VERSION "dbc-export 1 2026.26.6.5"

NS_ :

BS_:

BU_: ADSP APB APP APS APSB BB BMS CC CMP CMPD CP DAS DI DIF DIR DPB EPAS3P EPAS3S EPASTP EPASTS EPBL EPBR ESP EVSE FC GTW HCML HCMR HVP IBST ICR IDB LS OCS1P ODIN PARK PCS PCS2 PLG PM PMF PMR PNCD PTC RADC RCM RCM2 RCM3 RCU SCCM SCM SCS SDCR TAS TCU TCU2 TPMS TRCM UDS UI UIS UMC USM V2G VC VCBATT VCBATT0 VCBATT1 VCBATT2 VCCC VCFRONT VCFRONT1 VCFRONT2 VCLEFT VCRIGHT VCSEAT2L VCSEAT2R VCSEC VEH

BO_ 1300 FC_serial: 8 FC
 SG_ FC_serialDataSelect M : 0|7@1+ (1,0) [0|127] "" Vector__XXX
 SG_ FC_serialChar01 m0 : 8|8@1+ (1,0) [0|255] "" Vector__XXX
 SG_ FC_serialChar02 m0 : 16|8@1+ (1,0) [0|255] "" Vector__XXX
 SG_ FC_serialChar03 m0 : 24|8@1+ (1,0) [0|255] "" Vector__XXX
 SG_ FC_serialChar04 m0 : 32|8@1+ (1,0) [0|255] "" Vector__XXX
 SG_ FC_serialChar05 m0 : 40|8@1+ (1,0) [0|255] "" Vector__XXX
 SG_ FC_serialChar06 m0 : 48|8@1+ (1,0) [0|255] "" Vector__XXX
 SG_ FC_serialChar07 m0 : 56|8@1+ (1,0) [0|255] "" Vector__XXX
 SG_ FC_serialChar08 m1 : 8|8@1+ (1,0) [0|255] "" Vector__XXX
 SG_ FC_serialChar09 m1 : 16|8@1+ (1,0) [0|255] "" Vector__XXX
 SG_ FC_serialChar10 m1 : 24|8@1+ (1,0) [0|255] "" Vector__XXX
 SG_ FC_serialChar11 m1 : 32|8@1+ (1,0) [0|255] "" Vector__XXX
 SG_ FC_serialChar12 m1 : 40|8@1+ (1,0) [0|255] "" Vector__XXX
 SG_ FC_serialChar13 m1 : 48|8@1+ (1,0) [0|255] "" Vector__XXX
 SG_ FC_serialChar14 m1 : 56|8@1+ (1,0) [0|255] "" Vector__XXX
 SG_ FC_serialChar15 m2 : 8|8@1+ (1,0) [0|255] "" Vector__XXX
 SG_ FC_serialChar16 m2 : 16|8@1+ (1,0) [0|255] "" Vector__XXX
 SG_ FC_serialChar17 m2 : 24|8@1+ (1,0) [0|255] "" Vector__XXX

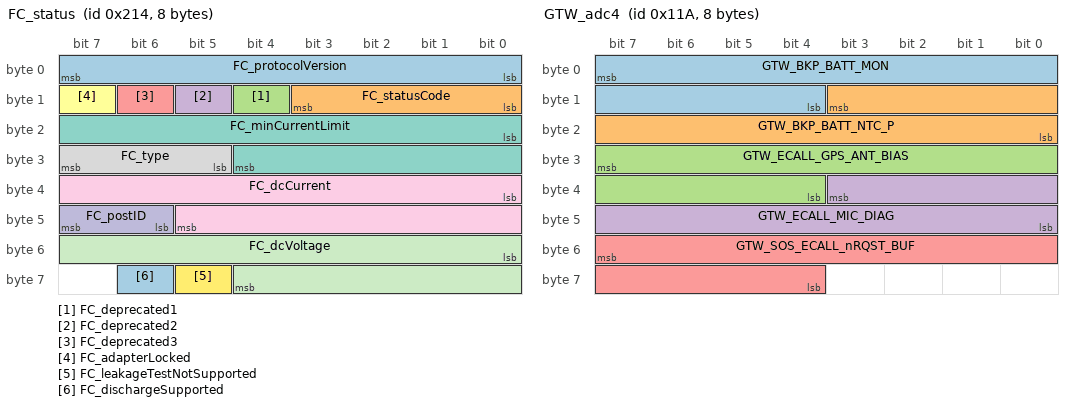
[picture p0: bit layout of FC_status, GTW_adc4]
BO_ 532 FC_status: 8 FC
 SG_ FC_protocolVersion : 0|8@1+ (1,0) [0|255] "" Vector__XXX
 SG_ FC_statusCode : 8|4@1+ (1,0) [1|15] "" Vector__XXX
 SG_ FC_deprecated1 : 12|1@1+ (1,0) [0|1] "" Vector__XXX
 SG_ FC_deprecated2 : 13|1@1+ (1,0) [0|1] "" Vector__XXX
 SG_ FC_deprecated3 : 14|1@1+ (1,0) [0|1] "" Vector__XXX
 SG_ FC_adapterLocked : 15|1@1+ (1,0) [0|1] "" Vector__XXX
 SG_ FC_minCurrentLimit : 16|13@1+ (0.1,0) [0|600] "A" Vector__XXX
 SG_ FC_type : 29|3@1+ (1,0) [0|6] "" Vector__XXX
 SG_ FC_dcCurrent : 32|14@1- (0.07324219,0) [-600|599.92675781] "A" Vector__XXX
 SG_ FC_postID : 46|2@1+ (1,0) [0|2] "" Vector__XXX
 SG_ FC_dcVoltage : 48|13@1+ (0.07324219,0) [0|599.92675822] "V" Vector__XXX
 SG_ FC_leakageTestNotSupported : 61|1@1+ (1,0) [0|1] "" Vector__XXX
 SG_ FC_dischargeSupported : 62|1@1+ (1,0) [0|1] "" Vector__XXX

BO_ 533 FC_status2: 1 FC
 SG_ FC_externalIsolationResistance : 0|8@1+ (40,0) [0|10160] "kOhm" Vector__XXX

BO_ 535 FC_status3: 8 FC
 SG_ FC_status3DataSelect M : 0|7@1+ (1,0) [0|127] "" Vector__XXX
 SG_ FC_status3DummySig : 7|1@1+ (1,0) [0|1] "" Vector__XXX
 SG_ FC_class m0 : 8|8@1+ (1,0) [1|255] "" Vector__XXX
 SG_ FC_brand m0 : 16|4@1+ (1,0) [1|15] "" Vector__XXX
 SG_ FC_coolingType m0 : 20|4@1+ (1,0) [1|15] "" Vector__XXX
 SG_ FC_uiStopType m0 : 24|4@1+ (1,0) [1|15] "" Vector__XXX
 SG_ FC_emergencyShutdownSupported m0 : 28|1@1+ (1,0) [0|1] "" Vector__XXX
 SG_ FC_generation m0 : 32|8@1+ (1,0) [1|255] "" Vector__XXX
 SG_ FC_billingEnergy m1 : 8|16@1+ (0.015259,0) [0|999.998565] "kWh" Vector__XXX

BO_ 888 GTW_ECall: 1 GTW
 SG_ GTW_GTW_SOS_ECALL_RQST : 0|1@1+ (1,0) [0|1] "" Vector__XXX
 SG_ GTW_LTE_ECALL_LOCK : 1|1@1+ (1,0) [0|1] "" Vector__XXX

BO_ 282 GTW_adc4: 8 GTW
 SG_ GTW_BKP_BATT_MON : 7|12@0+ (1,0) [0|4094] "mV" Vector__XXX
 SG_ GTW_BKP_BATT_NTC_P : 11|12@0+ (1,0) [0|4094] "mV" Vector__XXX
 SG_ GTW_ECALL_GPS_ANT_BIAS : 31|12@0+ (1,0) [0|4094] "mV" Vector__XXX
 SG_ GTW_ECALL_MIC_DIAG : 35|12@0+ (1,0) [0|4094] "mV" Vector__XXX
 SG_ GTW_SOS_ECALL_nRQST_BUF : 55|12@0+ (1,0) [0|4094] "mV" Vector__XXX

BO_ 1384 GTW_alertLog: 8 GTW
 SG_ GTW_alertID M : 0|9@1+ (1,0) [0|511] "" Vector__XXX
 SG_ GTW_alertState : 15|1@1+ (1,0) [0|1] "" Vector__XXX
 SG_ GTW_a014_crcVersion m14 : 16|32@1+ (1,0) [0|4294967295] "" Vector__XXX
 SG_ GTW_a015_crcVersion m15 : 16|32@1+ (1,0) [0|4294967295] "" Vector__XXX
 SG_ GTW_a016_crcVersion m16 : 16|32@1+ (1,0) [0|4294967295] "" Vector__XXX
 SG_ GTW_a017_crcVersion m17 : 16|32@1+ (1,0) [0|4294967295] "" Vector__XXX
 SG_ GTW_a018_crcVersion m18 : 16|32@1+ (1,0) [0|4294967295] "" Vector__XXX
 SG_ GTW_a019_crcVersion m19 : 16|32@1+ (1,0) [0|4294967295] "" Vector__XXX
 SG_ GTW_a020_crcVersion m20 : 16|32@1+ (1,0) [0|4294967295] "" Vector__XXX
 SG_ GTW_a021_crcVersion m21 : 16|32@1+ (1,0) [0|4294967295] "" Vector__XXX
 SG_ GTW_a022_crcVersion m22 : 16|32@1+ (1,0) [0|4294967295] "" Vector__XXX
 SG_ GTW_a023_crcVersion m23 : 16|32@1+ (1,0) [0|4294967295] "" Vector__XXX
 SG_ GTW_a024_crcVersion m24 : 16|32@1+ (1,0) [0|4294967295] "" Vector__XXX
 SG_ GTW_a025_crcVersion m25 : 16|32@1+ (1,0) [0|4294967295] "" Vector__XXX
 SG_ GTW_a026_crcVersion m26 : 16|32@1+ (1,0) [0|4294967295] "" Vector__XXX
 SG_ GTW_a027_crcVersion m27 : 16|32@1+ (1,0) [0|4294967295] "" Vector__XXX
 SG_ GTW_a028_crcVersion m28 : 16|32@1+ (1,0) [0|4294967295] "" Vector__XXX
 SG_ GTW_a029_crcVersion m29 : 16|32@1+ (1,0) [0|4294967295] "" Vector__XXX
 SG_ GTW_a030_crcVersion m30 : 16|32@1+ (1,0) [0|4294967295] "" Vector__XXX
 SG_ GTW_a031_crcVersion m31 : 16|32@1+ (1,0) [0|4294967295] "" Vector__XXX
 SG_ GTW_a032_crcVersion m32 : 16|32@1+ (1,0) [0|4294967295] "" Vector__XXX
 SG_ GTW_a033_crcVersion m33 : 16|32@1+ (1,0) [0|4294967295] "" Vector__XXX
 SG_ GTW_a034_crcVersion m34 : 16|32@1+ (1,0) [0|4294967295] "" Vector__XXX
 SG_ GTW_a035_crcVersion m35 : 16|32@1+ (1,0) [0|4294967295] "" Vector__XXX
 SG_ GTW_a036_crcVersion m36 : 16|32@1+ (1,0) [0|4294967295] "" Vector__XXX
 SG_ GTW_a037_crcVersion m37 : 16|32@1+ (1,0) [0|4294967295] "" Vector__XXX
 SG_ GTW_a038_crcVersion m38 : 16|32@1+ (1,0) [0|4294967295] "" Vector__XXX
 SG_ GTW_a039_crcVersion m39 : 16|32@1+ (1,0) [0|4294967295] "" Vector__XXX
 SG_ GTW_a040_crcVersion m40 : 16|32@1+ (1,0) [0|4294967295] "" Vector__XXX
 SG_ GTW_a041_crcVersion m41 : 16|32@1+ (1,0) [0|4294967295] "" Vector__XXX
 SG_ GTW_a042_crcVersion m42 : 16|32@1+ (1,0) [0|4294967295] "" Vector__XXX
 SG_ GTW_a043_crcVersion m43 : 16|32@1+ (1,0) [0|4294967295] "" Vector__XXX
 SG_ GTW_a045_crcVersion m45 : 16|32@1+ (1,0) [0|4294967295] "" Vector__XXX
 SG_ GTW_a046_crcVersion m46 : 16|32@1+ (1,0) [0|4294967295] "" Vector__XXX
 SG_ GTW_a047_crcVersion m47 : 16|32@1+ (1,0) [0|4294967295] "" Vector__XXX
 SG_ GTW_a048_crcVersion m48 : 16|32@1+ (1,0) [0|4294967295] "" Vector__XXX
 SG_ GTW_a049_headerError m49 : 16|2@1+ (1,0) [0|3] "" Vector__XXX
 SG_ GTW_a054_crcVersion m54 : 16|32@1+ (1,0) [0|4294967295] "" Vector__XXX
 SG_ GTW_a055_crcVersion m55 : 16|32@1+ (1,0) [0|4294967295] "" Vector__XXX
 SG_ GTW_a062_bmpWatchdogReason m62 : 16|3@1+ (1,0) [0|7] "" Vector__XXX
 SG_ GTW_a063_VEH_faultConfinement m63 : 16|2@1+ (1,0) [0|3] "" Vector__XXX
 SG_ GTW_a064_CH_faultConfinement m64 : 16|2@1+ (1,0) [0|3] "" Vector__XXX
 SG_ GTW_a065_PARTY_faultConfinement m65 : 16|2@1+ (1,0) [0|3] "" Vector__XXX
 SG_ GTW_a066_type m66 : 16|5@1+ (1,0) [0|31] "" Vector__XXX
 SG_ GTW_a066_exceptionCfgId m66 : 21|8@1+ (1,0) [0|255] "" Vector__XXX
 SG_ GTW_a066_uptime m66 : 29|32@1+ (1,0) [0|4294967295] "" Vector__XXX
 SG_ GTW_a066_core m66 : 61|3@1+ (1,0) [0|7] "" Vector__XXX
 SG_ GTW_a068_codeKeyMissing m68 : 16|1@1+ (1,0) [0|1] "" Vector__XXX
 SG_ GTW_a068_cmdKeyMissing m68 : 17|1@1+ (1,0) [0|1] "" Vector__XXX
 SG_ GTW_a069_sdIntStatusErrs m69 : 16|1@1+ (1,0) [0|1] "" Vector__XXX
 SG_ GTW_a069_sdTimeout m69 : 17|1@1+ (1,0) [0|1] "" Vector__XXX
 SG_ GTW_a069_sdCmdErr m69 : 18|1@1+ (1,0) [0|1] "" Vector__XXX
 SG_ GTW_a069_sdWriteErr m69 : 19|1@1+ (1,0) [0|1] "" Vector__XXX
 SG_ GTW_a069_sdReadErr m69 : 20|1@1+ (1,0) [0|1] "" Vector__XXX
 SG_ GTW_a069_autoCmd12Err m69 : 21|1@1+ (1,0) [0|1] "" Vector__XXX
 SG_ GTW_a072_updtFailureMask m72 : 16|32@1+ (1,0) [0|4294967295] "" Vector__XXX
 SG_ GTW_a073_SOCResetRequestor m73 : 16|3@1+ (1,0) [0|7] "" Vector__XXX
 SG_ GTW_a077_bmpPmicErrorType m77 : 16|3@1+ (1,0) [0|7] "" Vector__XXX
 SG_ GTW_a097_crcVersion m97 : 16|32@1+ (1,0) [0|4294967295] "" Vector__XXX
 SG_ GTW_a098_crcVersion m98 : 16|32@1+ (1,0) [0|4294967295] "" Vector__XXX
 SG_ GTW_a099_crcVersion m99 : 16|32@1+ (1,0) [0|4294967295] "" Vector__XXX
 SG_ GTW_a100_crcVersion m100 : 16|32@1+ (1,0) [0|4294967295] "" Vector__XXX
 SG_ GTW_a101_switchStuck m101 : 16|1@1+ (1,0) [0|1] "" Vector__XXX
 SG_ GTW_a101_ETH_SW_nINT m101 : 17|1@1+ (1,0) [0|1] "" Vector__XXX
 SG_ GTW_a106_crcVersion m106 : 16|32@1+ (1,0) [0|4294967295] "" Vector__XXX
 SG_ GTW_a107_crcVersion m107 : 16|32@1+ (1,0) [0|4294967295] "" Vector__XXX
 SG_ GTW_a108_crcVersion m108 : 16|32@1+ (1,0) [0|4294967295] "" Vector__XXX
 SG_ GTW_a117_MC_RGM_DES m117 : 16|32@1+ (1,0) [0|4294967295] "" Vector__XXX
 SG_ GTW_a118_MC_RGM_FES m118 : 16|32@1+ (1,0) [0|4294967295] "" Vector__XXX
 SG_ GTW_a122_BDY_faultConfinement m122 : 16|2@1+ (1,0) [0|3] "" Vector__XXX
 SG_ GTW_a129_crcVersion m129 : 16|32@1+ (1,0) [0|4294967295] "" Vector__XXX
 SG_ GTW_a138_sdLifetimeUsed m138 : 16|8@1+ (1,0) [0|255] "" Vector__XXX
 SG_ GTW_a139_crcVersion m139 : 16|32@1+ (1,0) [0|4294967295] "" Vector__XXX
 SG_ GTW_a150_crcVersion m150 : 16|32@1+ (1,0) [0|4294967295] "" Vector__XXX
 SG_ GTW_a151_crcVersion m151 : 16|32@1+ (1,0) [0|4294967295] "" Vector__XXX
 SG_ GTW_a155_crcVersion m155 : 16|32@1+ (1,0) [0|4294967295] "" Vector__XXX
 SG_ GTW_a164_crcVersion m164 : 16|32@1+ (1,0) [0|4294967295] "" Vector__XXX
 SG_ GTW_a165_crcVersion m165 : 16|32@1+ (1,0) [0|4294967295] "" Vector__XXX
 SG_ GTW_a169_TPMS_pressureFL m169 : 16|8@1+ (1,0) [0|255] "" Vector__XXX
 SG_ GTW_a170_TPMS_pressureFR m170 : 16|8@1+ (1,0) [0|255] "" Vector__XXX
 SG_ GTW_a171_TPMS_pressureRL m171 : 16|8@1+ (1,0) [0|255] "" Vector__XXX
 SG_ GTW_a172_TPMS_pressureRR m172 : 16|8@1+ (1,0) [0|255] "" Vector__XXX
 SG_ GTW_a173_TPMS_pressureFL m173 : 16|8@1+ (1,0) [0|255] "" Vector__XXX
 SG_ GTW_a174_TPMS_pressureFR m174 : 16|8@1+ (1,0) [0|255] "" Vector__XXX
 SG_ GTW_a175_TPMS_pressureRL m175 : 16|8@1+ (1,0) [0|255] "" Vector__XXX
 SG_ GTW_a176_TPMS_pressureRR m176 : 16|8@1+ (1,0) [0|255] "" Vector__XXX
 SG_ GTW_a219_crcVersion m219 : 16|32@1+ (1,0) [0|4294967295] "" Vector__XXX
 SG_ GTW_a223_crcVersion m223 : 16|32@1+ (1,0) [0|4294967295] "" Vector__XXX
 SG_ GTW_a226_crcVersion m226 : 16|32@1+ (1,0) [0|4294967295] "" Vector__XXX
 SG_ GTW_a227_crcVersion m227 : 16|32@1+ (1,0) [0|4294967295] "" Vector__XXX
 SG_ GTW_a228_crcVersion m228 : 16|32@1+ (1,0) [0|4294967295] "" Vector__XXX
 SG_ GTW_a244_crcVersion m244 : 16|32@1+ (1,0) [0|4294967295] "" Vector__XXX
 SG_ GTW_a245_page0ControlValue m245 : 16|16@1+ (1,0) [0|65535] "" Vector__XXX
 SG_ GTW_a245_page1ControlValue m245 : 32|16@1+ (1,0) [0|65535] "" Vector__XXX
 SG_ GTW_a261_failureReason m261 : 16|3@1+ (1,0) [0|7] "" Vector__XXX
 SG_ GTW_a261_failureData1 m261 : 24|16@1+ (1,0) [0|65535] "" Vector__XXX
 SG_ GTW_a261_failureData2 m261 : 40|16@1+ (1,0) [0|65535] "" Vector__XXX
 SG_ GTW_a273_crcVersion m273 : 16|32@1+ (1,0) [0|4294967295] "" Vector__XXX
 SG_ GTW_a274_crcVersion m274 : 16|32@1+ (1,0) [0|4294967295] "" Vector__XXX
 SG_ GTW_a277_mitigationFailureReason m277 : 16|3@1+ (1,0) [0|7] "" Vector__XXX
 SG_ GTW_a279_repeatCount m279 : 16|8@1+ (1,0) [0|255] "" Vector__XXX
 SG_ GTW_a279_failureReason m279 : 24|3@1+ (1,0) [0|7] "" Vector__XXX
 SG_ GTW_a279_failureData1 m279 : 32|16@1+ (1,0) [0|65535] "" Vector__XXX
 SG_ GTW_a279_failureData2 m279 : 48|16@1+ (1,0) [0|65535] "" Vector__XXX
 SG_ GTW_a309_crcVersion m309 : 16|32@1+ (1,0) [0|4294967295] "" Vector__XXX
 SG_ GTW_a317_status m317 : 16|3@1+ (1,0) [0|7] "" Vector__XXX
 SG_ GTW_a317_errorCode m317 : 19|5@1+ (1,0) [0|31] "" Vector__XXX
 SG_ GTW_a329_crcVersion m329 : 16|32@1+ (1,0) [0|4294967295] "" Vector__XXX
 SG_ GTW_a330_crcVersion m330 : 16|32@1+ (1,0) [0|4294967295] "" Vector__XXX
 SG_ GTW_a331_crcVersion m331 : 16|32@1+ (1,0) [0|4294967295] "" Vector__XXX
 SG_ GTW_a342_crcVersion m342 : 16|32@1+ (1,0) [0|4294967295] "" Vector__XXX
 SG_ GTW_a348_crcVersion m348 : 16|32@1+ (1,0) [0|4294967295] "" Vector__XXX
 SG_ GTW_a349_crcVersion m349 : 16|32@1+ (1,0) [0|4294967295] "" Vector__XXX
 SG_ GTW_a354_crcVersion m354 : 16|32@1+ (1,0) [0|4294967295] "" Vector__XXX
 SG_ GTW_a355_crcVersion m355 : 16|32@1+ (1,0) [0|4294967295] "" Vector__XXX
 SG_ GTW_a358_crcVersion m358 : 16|32@1+ (1,0) [0|4294967295] "" Vector__XXX
 SG_ GTW_a359_crcVersion m359 : 16|32@1+ (1,0) [0|4294967295] "" Vector__XXX
 SG_ GTW_a360_crcVersion m360 : 16|32@1+ (1,0) [0|4294967295] "" Vector__XXX
 SG_ GTW_a361_crcVersion m361 : 16|32@1+ (1,0) [0|4294967295] "" Vector__XXX
 SG_ GTW_a362_crcVersion m362 : 16|32@1+ (1,0) [0|4294967295] "" Vector__XXX
 SG_ GTW_a363_crcVersion m363 : 16|32@1+ (1,0) [0|4294967295] "" Vector__XXX
 SG_ GTW_a364_crcVersion m364 : 16|32@1+ (1,0) [0|4294967295] "" Vector__XXX
 SG_ GTW_a380_crcVersion m380 : 16|32@1+ (1,0) [0|4294967295] "" Vector__XXX
 SG_ GTW_a381_crcVersion m381 : 16|32@1+ (1,0) [0|4294967295] "" Vector__XXX
 SG_ GTW_a382_crcVersion m382 : 16|32@1+ (1,0) [0|4294967295] "" Vector__XXX
 SG_ GTW_a383_crcVersion m383 : 16|32@1+ (1,0) [0|4294967295] "" Vector__XXX
 SG_ GTW_a384_crcVersion m384 : 16|32@1+ (1,0) [0|4294967295] "" Vector__XXX
 SG_ GTW_a385_crcVersion m385 : 16|32@1+ (1,0) [0|4294967295] "" Vector__XXX
 SG_ GTW_a386_crcVersion m386 : 16|32@1+ (1,0) [0|4294967295] "" Vector__XXX
 SG_ GTW_a394_crcVersion m394 : 16|32@1+ (1,0) [0|4294967295] "" Vector__XXX
 SG_ GTW_a401_crcVersion m401 : 16|32@1+ (1,0) [0|4294967295] "" Vector__XXX
 SG_ GTW_a402_crcVersion m402 : 16|32@1+ (1,0) [0|4294967295] "" Vector__XXX
 SG_ GTW_a409_RES_CAUSE m409 : 16|32@1+ (1,0) [0|4294967295] "" Vector__XXX
 SG_ GTW_a410_RES_CAUSE2 m410 : 16|32@1+ (1,0) [0|4294967295] "" Vector__XXX
 SG_ GTW_a418_crcVersion m418 : 16|32@1+ (1,0) [0|4294967295] "" Vector__XXX
 SG_ GTW_a427_crcVersion m427 : 16|32@1+ (1,0) [0|4294967295] "" Vector__XXX
 SG_ GTW_a428_crcVersion m428 : 16|32@1+ (1,0) [0|4294967295] "" Vector__XXX
 SG_ GTW_a429_crcVersion m429 : 16|32@1+ (1,0) [0|4294967295] "" Vector__XXX
 SG_ GTW_a439_crcVersion m439 : 16|32@1+ (1,0) [0|4294967295] "" Vector__XXX

BO_ 62 GTW_alertMatrix: 8 GTW
 SG_ GTW_matrixIndex M : 0|4@1+ (1,0) [0|15] "" Vector__XXX
 SG_ GTW_w001_canEthTxQueue m0 : 4|1@1+ (1,0) [0|1] "" Vector__XXX
 SG_ GTW_w002_taskError m0 : 5|1@1+ (1,0) [0|1] "" Vector__XXX
 SG_ GTW_w003_logWriteRecord m0 : 6|1@1+ (1,0) [0|1] "" Vector__XXX
 SG_ GTW_w004_mallocHook m0 : 7|1@1+ (1,0) [0|1] "" Vector__XXX
 SG_ GTW_w005_stackOverflowHook m0 : 8|1@1+ (1,0) [0|1] "" Vector__XXX
 SG_ GTW_w006_ifTxOutputFull m0 : 9|1@1+ (1,0) [0|1] "" Vector__XXX
 SG_ GTW_w007_ifRxBufError m0 : 10|1@1+ (1,0) [0|1] "" Vector__XXX
 SG_ GTW_w008_ifPbufAllocError m0 : 11|1@1+ (1,0) [0|1] "" Vector__XXX
 SG_ GTW_w009_lateTask m0 : 12|1@1+ (1,0) [0|1] "" Vector__XXX
 SG_ GTW_w010_wdTaskCount m0 : 13|1@1+ (1,0) [0|1] "" Vector__XXX
 SG_ GTW_w011_cancoreWatchdog m0 : 14|1@1+ (1,0) [0|1] "" Vector__XXX
 SG_ GTW_w012_maincoreWatchdog m0 : 15|1@1+ (1,0) [0|1] "" Vector__XXX
 SG_ GTW_w014_APSversionMismatch m0 : 17|1@1+ (1,0) [0|1] "" Vector__XXX
 SG_ GTW_w015_DIFversionMismatch m0 : 18|1@1+ (1,0) [0|1] "" Vector__XXX
 SG_ GTW_w016_BLEEPCENTERversionMisma m0 : 19|1@1+ (1,0) [0|1] "" Vector__XXX
 SG_ GTW_w017_BMSversionMismatch m0 : 20|1@1+ (1,0) [0|1] "" Vector__XXX
 SG_ GTW_w018_CMPversionMismatch m0 : 21|1@1+ (1,0) [0|1] "" Vector__XXX
 SG_ GTW_w019_CPversionMismatch m0 : 22|1@1+ (1,0) [0|1] "" Vector__XXX
 SG_ GTW_w020_DIRversionMismatch m0 : 23|1@1+ (1,0) [0|1] "" Vector__XXX
 SG_ GTW_w021_EPAS3PversionMismatch m0 : 24|1@1+ (1,0) [0|1] "" Vector__XXX
 SG_ GTW_w022_EPBLversionMismatch m0 : 25|1@1+ (1,0) [0|1] "" Vector__XXX
 SG_ GTW_w023_EPBRversionMismatch m0 : 26|1@1+ (1,0) [0|1] "" Vector__XXX
 SG_ GTW_w024_ESPversionMismatch m0 : 27|1@1+ (1,0) [0|1] "" Vector__XXX
 SG_ GTW_w025_ESPCALversionMismatch m0 : 28|1@1+ (1,0) [0|1] "" Vector__XXX
 SG_ GTW_w026_GTWversionMismatch m0 : 29|1@1+ (1,0) [0|1] "" Vector__XXX
 SG_ GTW_w027_HVPversionMismatch m0 : 30|1@1+ (1,0) [0|1] "" Vector__XXX
 SG_ GTW_w028_IBSTversionMismatch m0 : 31|1@1+ (1,0) [0|1] "" Vector__XXX
 SG_ GTW_w029_IBSTCALversionMismatch m0 : 32|1@1+ (1,0) [0|1] "" Vector__XXX
 SG_ GTW_w030_OCS1PversionMismatch m0 : 33|1@1+ (1,0) [0|1] "" Vector__XXX
 SG_ GTW_w031_PARKversionMismatch m0 : 34|1@1+ (1,0) [0|1] "" Vector__XXX
 SG_ GTW_w032_PCSversionMismatch m0 : 35|1@1+ (1,0) [0|1] "" Vector__XXX
 SG_ GTW_w033_PCSCPU2versionMismatch m0 : 36|1@1+ (1,0) [0|1] "" Vector__XXX
 SG_ GTW_w034_PMRversionMismatch m0 : 37|1@1+ (1,0) [0|1] "" Vector__XXX
 SG_ GTW_w035_PMFversionMismatch m0 : 38|1@1+ (1,0) [0|1] "" Vector__XXX
 SG_ GTW_w036_PTCversionMismatch m0 : 39|1@1+ (1,0) [0|1] "" Vector__XXX
 SG_ GTW_w037_RADCversionMismatch m0 : 40|1@1+ (1,0) [0|1] "" Vector__XXX
 SG_ GTW_w038_RCMversionMismatch m0 : 41|1@1+ (1,0) [0|1] "" Vector__XXX
 SG_ GTW_w039_RCMCALversionMismatch m0 : 42|1@1+ (1,0) [0|1] "" Vector__XXX
 SG_ GTW_w040_SCCMversionMismatch m0 : 43|1@1+ (1,0) [0|1] "" Vector__XXX
 SG_ GTW_w041_VCSECversionMismatch m0 : 44|1@1+ (1,0) [0|1] "" Vector__XXX
 SG_ GTW_w042_TASversionMismatch m0 : 45|1@1+ (1,0) [0|1] "" Vector__XXX
 SG_ GTW_w043_THSversionMismatch m0 : 46|1@1+ (1,0) [0|1] "" Vector__XXX
 SG_ GTW_w045_VCFRONTversionMismatch m0 : 48|1@1+ (1,0) [0|1] "" Vector__XXX
 SG_ GTW_w046_VCLEFTversionMismatch m0 : 49|1@1+ (1,0) [0|1] "" Vector__XXX
 SG_ GTW_w047_VCRIGHTversionMismatch m0 : 50|1@1+ (1,0) [0|1] "" Vector__XXX
 SG_ GTW_w048_EPAS3SversionMismatch m0 : 51|1@1+ (1,0) [0|1] "" Vector__XXX
 SG_ GTW_w049_corruptedManifest m0 : 52|1@1+ (1,0) [0|1] "" Vector__XXX
 SG_ GTW_w050_sdCardInitFailure m0 : 53|1@1+ (1,0) [0|1] "" Vector__XXX
 SG_ GTW_w051_sdCardFileSystemFailure m0 : 54|1@1+ (1,0) [0|1] "" Vector__XXX
 SG_ GTW_w052_ifTxSpans m0 : 55|1@1+ (1,0) [0|1] "" Vector__XXX
 SG_ GTW_w053_busSleepFailure m0 : 56|1@1+ (1,0) [0|1] "" Vector__XXX
 SG_ GTW_w054_OPCRversionMismatch m0 : 57|1@1+ (1,0) [0|1] "" Vector__XXX
 SG_ GTW_w055_OPCFversionMismatch m0 : 58|1@1+ (1,0) [0|1] "" Vector__XXX
 SG_ GTW_w057_i2cFailure m0 : 60|1@1+ (1,0) [0|1] "" Vector__XXX
 SG_ GTW_w058_rtcAlarmFailure m0 : 61|1@1+ (1,0) [0|1] "" Vector__XXX
 SG_ GTW_w059_inFactoryMode m0 : 62|1@1+ (1,0) [0|1] "" Vector__XXX
 SG_ GTW_w060_unFused m0 : 63|1@1+ (1,0) [0|1] "" Vector__XXX
 SG_ GTW_w061_bmpSleepFailure m1 : 4|1@1+ (1,0) [0|1] "" Vector__XXX
 SG_ GTW_w062_bmpWatchdog m1 : 5|1@1+ (1,0) [0|1] "" Vector__XXX
 SG_ GTW_w063_VEH_canFault m1 : 6|1@1+ (1,0) [0|1] "" Vector__XXX
 SG_ GTW_w064_CH_canFault m1 : 7|1@1+ (1,0) [0|1] "" Vector__XXX
 SG_ GTW_w065_PARTY_canFault m1 : 8|1@1+ (1,0) [0|1] "" Vector__XXX
 SG_ GTW_w066_exception m1 : 9|1@1+ (1,0) [0|1] "" Vector__XXX
 SG_ GTW_w067_tcpDebug m1 : 10|1@1+ (1,0) [0|1] "" Vector__XXX
 SG_ GTW_w068_prodKeyMissing m1 : 11|1@1+ (1,0) [0|1] "" Vector__XXX
 SG_ GTW_w069_diskioErr m1 : 12|1@1+ (1,0) [0|1] "" Vector__XXX
 SG_ GTW_w070_hrlDump m1 : 13|1@1+ (1,0) [0|1] "" Vector__XXX
 SG_ GTW_w071_hrlTrigger m1 : 14|1@1+ (1,0) [0|1] "" Vector__XXX
 SG_ GTW_w072_updateFailure m1 : 15|1@1+ (1,0) [0|1] "" Vector__XXX
 SG_ GTW_w073_steeringWheelReset m1 : 16|1@1+ (1,0) [0|1] "" Vector__XXX
 SG_ GTW_w074_epas3pMIA m1 : 17|1@1+ (1,0) [0|1] "" Vector__XXX
 SG_ GTW_w075_epas3sMIA m1 : 18|1@1+ (1,0) [0|1] "" Vector__XXX
 SG_ GTW_w076_ethInterfaceReset m1 : 19|1@1+ (1,0) [0|1] "" Vector__XXX
 SG_ GTW_w077_bmpPmicError m1 : 20|1@1+ (1,0) [0|1] "" Vector__XXX
 SG_ GTW_w078_VEHbusOverloaded m1 : 21|1@1+ (1,0) [0|1] "" Vector__XXX
 SG_ GTW_w079_PARTYbusOverloaded m1 : 22|1@1+ (1,0) [0|1] "" Vector__XXX
 SG_ GTW_w080_CHbusOverloaded m1 : 23|1@1+ (1,0) [0|1] "" Vector__XXX
 SG_ GTW_w081_udsMessageRejected m1 : 24|1@1+ (1,0) [0|1] "" Vector__XXX
 SG_ GTW_w082_sdCardBSCorrupted m1 : 25|1@1+ (1,0) [0|1] "" Vector__XXX
 SG_ GTW_w083_udsMsgDroppedByTcpStack m1 : 26|1@1+ (1,0) [0|1] "" Vector__XXX
 SG_ GTW_w084_canFrameDropped m1 : 27|1@1+ (1,0) [0|1] "" Vector__XXX
 SG_ GTW_w085_fuseStateUnknown m1 : 28|1@1+ (1,0) [0|1] "" Vector__XXX
 SG_ GTW_w086_ocu m1 : 29|1@1+ (1,0) [0|1] "" Vector__XXX
 SG_ GTW_w087_ocuInProgress m1 : 30|1@1+ (1,0) [0|1] "" Vector__XXX
 SG_ GTW_w088_sdCardInvReqParallel m1 : 31|1@1+ (1,0) [0|1] "" Vector__XXX
 SG_ GTW_w089_sdCardWatchdog m1 : 32|1@1+ (1,0) [0|1] "" Vector__XXX
 SG_ GTW_w090_ocuFailed m1 : 33|1@1+ (1,0) [0|1] "" Vector__XXX
 SG_ GTW_w091_lowStack m1 : 34|1@1+ (1,0) [0|1] "" Vector__XXX
 SG_ GTW_w092_sdCardInvReqZero m1 : 35|1@1+ (1,0) [0|1] "" Vector__XXX
 SG_ GTW_w093_sdCardInvReqOverflowBas m1 : 36|1@1+ (1,0) [0|1] "" Vector__XXX
 SG_ GTW_w094_sdCardInvReqOverflowCou m1 : 37|1@1+ (1,0) [0|1] "" Vector__XXX
 SG_ GTW_w095_sdCardFull m1 : 38|1@1+ (1,0) [0|1] "" Vector__XXX
 SG_ GTW_w096_sdCardFatCorrupted m1 : 39|1@1+ (1,0) [0|1] "" Vector__XXX
 SG_ GTW_w097_HCMLversionMismatch m1 : 40|1@1+ (1,0) [0|1] "" Vector__XXX
 SG_ GTW_w098_HCMRversionMismatch m1 : 41|1@1+ (1,0) [0|1] "" Vector__XXX
 SG_ GTW_w099_SWCversionMismatch m1 : 42|1@1+ (1,0) [0|1] "" Vector__XXX
 SG_ GTW_w100_CBCversionMismatch m1 : 43|1@1+ (1,0) [0|1] "" Vector__XXX
 SG_ GTW_w101_switchWatchdog m1 : 44|1@1+ (1,0) [0|1] "" Vector__XXX
 SG_ GTW_w103_sdCardFormatted m1 : 46|1@1+ (1,0) [0|1] "" Vector__XXX
 SG_ GTW_w104_sdCardDriverArgCorrupte m1 : 47|1@1+ (1,0) [0|1] "" Vector__XXX
 SG_ GTW_w105_eBuckConfigured m1 : 48|1@1+ (1,0) [0|1] "" Vector__XXX
 SG_ GTW_w106_BLEEPLEFTversionMismatc m1 : 49|1@1+ (1,0) [0|1] "" Vector__XXX
 SG_ GTW_w107_BLEEPRIGHTversionMismat m1 : 50|1@1+ (1,0) [0|1] "" Vector__XXX
 SG_ GTW_w108_BLEEPREARversionMismatc m1 : 51|1@1+ (1,0) [0|1] "" Vector__XXX
 SG_ GTW_w109_failedToStartUpdater m1 : 52|1@1+ (1,0) [0|1] "" Vector__XXX
 SG_ GTW_w110_readMdioFailed m1 : 53|1@1+ (1,0) [0|1] "" Vector__XXX
 SG_ GTW_w111_writeMdioFailed m1 : 54|1@1+ (1,0) [0|1] "" Vector__XXX
 SG_ GTW_w112_z4bDisabled m1 : 55|1@1+ (1,0) [0|1] "" Vector__XXX
 SG_ GTW_w113_unrecognizedCanMessage m1 : 56|1@1+ (1,0) [0|1] "" Vector__XXX
 SG_ GTW_w114_updtRetried m1 : 57|1@1+ (1,0) [0|1] "" Vector__XXX
 SG_ GTW_w115_hrlEventFileAvail m1 : 58|1@1+ (1,0) [0|1] "" Vector__XXX
 SG_ GTW_w116_switchInitFailed m1 : 59|1@1+ (1,0) [0|1] "" Vector__XXX
 SG_ GTW_w117_unexpectedDestructiveRe m1 : 60|1@1+ (1,0) [0|1] "" Vector__XXX
 SG_ GTW_w118_unexpectedFunctionalRes m1 : 61|1@1+ (1,0) [0|1] "" Vector__XXX
 SG_ GTW_w120_switchUnlocked m1 : 63|1@1+ (1,0) [0|1] "" Vector__XXX
 SG_ GTW_w122_BDY_canFault m2 : 5|1@1+ (1,0) [0|1] "" Vector__XXX
 SG_ GTW_w123_BDYbusOverloaded m2 : 6|1@1+ (1,0) [0|1] "" Vector__XXX
 SG_ GTW_w125_switchReplayUnlocked m2 : 8|1@1+ (1,0) [0|1] "" Vector__XXX
 SG_ GTW_w127_noFilePointersAvailable m2 : 10|1@1+ (1,0) [0|1] "" Vector__XXX
 SG_ GTW_w129_ICRversionMismatch m2 : 12|1@1+ (1,0) [0|1] "" Vector__XXX
 SG_ GTW_w133_adspFaultDetected m2 : 16|1@1+ (1,0) [0|1] "" Vector__XXX
 SG_ GTW_w134_disableFeatureFailed m2 : 17|1@1+ (1,0) [0|1] "" Vector__XXX
 SG_ GTW_w135_canLogQueueFull m2 : 18|1@1+ (1,0) [0|1] "" Vector__XXX
 SG_ GTW_w136_hrlGameModeFileAvail m2 : 19|1@1+ (1,0) [0|1] "" Vector__XXX
 SG_ GTW_w137_lowHeap m2 : 20|1@1+ (1,0) [0|1] "" Vector__XXX
 SG_ GTW_w138_sdCardEndOfLife m2 : 21|1@1+ (1,0) [0|1] "" Vector__XXX
 SG_ GTW_w139_CMPDversionMismatch m2 : 22|1@1+ (1,0) [0|1] "" Vector__XXX
 SG_ GTW_w140_cancoreHeartbeat m2 : 23|1@1+ (1,0) [0|1] "" Vector__XXX
 SG_ GTW_w141_teleCANETHis m2 : 24|1@1+ (1,0) [0|1] "" Vector__XXX
 SG_ GTW_w143_possibleCanWakeIssue m2 : 26|1@1+ (1,0) [0|1] "" Vector__XXX
 SG_ GTW_w144_hrlStateMachine m2 : 27|1@1+ (1,0) [0|1] "" Vector__XXX
 SG_ GTW_w145_carConfigsNotWritten m2 : 28|1@1+ (1,0) [0|1] "" Vector__XXX
 SG_ GTW_w146_performancePackageMisma m2 : 29|1@1+ (1,0) [0|1] "" Vector__XXX
 SG_ GTW_w147_updateAbortFor12v m2 : 30|1@1+ (1,0) [0|1] "" Vector__XXX
 SG_ GTW_w149_rtcTimeSetInPast m2 : 32|1@1+ (1,0) [0|1] "" Vector__XXX
 SG_ GTW_w150_HCM3LversionMismatch m2 : 33|1@1+ (1,0) [0|1] "" Vector__XXX
 SG_ GTW_w151_HCM3RversionMismatch m2 : 34|1@1+ (1,0) [0|1] "" Vector__XXX
 SG_ GTW_w153_externalRtcAlarmFailure m2 : 36|1@1+ (1,0) [0|1] "" Vector__XXX
 SG_ GTW_w155_PMversionMismatch m2 : 38|1@1+ (1,0) [0|1] "" Vector__XXX
 SG_ GTW_w164_VCBATTversionMismatch m2 : 47|1@1+ (1,0) [0|1] "" Vector__XXX
 SG_ GTW_w165_USMversionMismatch m2 : 48|1@1+ (1,0) [0|1] "" Vector__XXX
 SG_ GTW_w166_nErrCanFaultVeh m2 : 49|1@1+ (1,0) [0|1] "" Vector__XXX
 SG_ GTW_w167_nErrCanFaultCh m2 : 50|1@1+ (1,0) [0|1] "" Vector__XXX
 SG_ GTW_w168_nErrCanFaultParty m2 : 51|1@1+ (1,0) [0|1] "" Vector__XXX
 SG_ GTW_w169_TPMSsoftWarnFrontLeft m2 : 52|1@1+ (1,0) [0|1] "" Vector__XXX
 SG_ GTW_w170_TPMSsoftWarnFrontRight m2 : 53|1@1+ (1,0) [0|1] "" Vector__XXX
 SG_ GTW_w171_TPMSsoftWarnRearLeft m2 : 54|1@1+ (1,0) [0|1] "" Vector__XXX
 SG_ GTW_w172_TPMSsoftWarnRearRight m2 : 55|1@1+ (1,0) [0|1] "" Vector__XXX
 SG_ GTW_w173_TPMShardWarnFrontLeft m2 : 56|1@1+ (1,0) [0|1] "" Vector__XXX
 SG_ GTW_w174_TPMShardWarnFrontRight m2 : 57|1@1+ (1,0) [0|1] "" Vector__XXX
 SG_ GTW_w175_TPMShardWarnRearLeft m2 : 58|1@1+ (1,0) [0|1] "" Vector__XXX
 SG_ GTW_w176_TPMShardWarnRearRight m2 : 59|1@1+ (1,0) [0|1] "" Vector__XXX
 SG_ GTW_w186_swrPrecaution m3 : 9|1@1+ (1,0) [0|1] "" Vector__XXX
 SG_ GTW_w218_switchOTPIncorrect m3 : 41|1@1+ (1,0) [0|1] "" Vector__XXX
 SG_ GTW_w219_CMPSversionMismatch m3 : 42|1@1+ (1,0) [0|1] "" Vector__XXX
 SG_ GTW_w223_LVBMSversionMismatch m3 : 46|1@1+ (1,0) [0|1] "" Vector__XXX
 SG_ GTW_w224_sdCardUpgradeNeeded m3 : 47|1@1+ (1,0) [0|1] "" Vector__XXX
 SG_ GTW_w225_resetOnSleepWake m3 : 48|1@1+ (1,0) [0|1] "" Vector__XXX
 SG_ GTW_w226_DISPversionMismatch m3 : 49|1@1+ (1,0) [0|1] "" Vector__XXX
 SG_ GTW_w227_DISPTOUCHversionMismatc m3 : 50|1@1+ (1,0) [0|1] "" Vector__XXX
 SG_ GTW_w228_DISPOSDversionMismatch m3 : 51|1@1+ (1,0) [0|1] "" Vector__XXX
 SG_ GTW_w229_displaySoftsetConnectio m3 : 52|1@1+ (1,0) [0|1] "" Vector__XXX
 SG_ GTW_w230_touchInterruptStorm m3 : 53|1@1+ (1,0) [0|1] "" Vector__XXX
 SG_ GTW_w244_SDCRversionMismatch m4 : 7|1@1+ (1,0) [0|1] "" Vector__XXX
 SG_ GTW_w245_apsNotDisabled m4 : 8|1@1+ (1,0) [0|1] "" Vector__XXX
 SG_ GTW_w246_touchcoreHeartbeat m4 : 9|1@1+ (1,0) [0|1] "" Vector__XXX
 SG_ GTW_w255_rtc32KHzWatchdog m4 : 18|1@1+ (1,0) [0|1] "" Vector__XXX
 SG_ GTW_w260_unknownPN m4 : 23|1@1+ (1,0) [0|1] "" Vector__XXX
 SG_ GTW_w261_adspWatchdog m4 : 24|1@1+ (1,0) [0|1] "" Vector__XXX
 SG_ GTW_w262_canLogBlockDropped m4 : 25|1@1+ (1,0) [0|1] "" Vector__XXX
 SG_ GTW_w263_hrlUdpFileAvail m4 : 26|1@1+ (1,0) [0|1] "" Vector__XXX
 SG_ GTW_w264_hrlPseudoFileAvail m4 : 27|1@1+ (1,0) [0|1] "" Vector__XXX
 SG_ GTW_w265_optionFlagsError m4 : 28|1@1+ (1,0) [0|1] "" Vector__XXX
 SG_ GTW_w266_dpp1MIA m4 : 29|1@1+ (1,0) [0|1] "" Vector__XXX
 SG_ GTW_w267_dpp2MIA m4 : 30|1@1+ (1,0) [0|1] "" Vector__XXX
 SG_ GTW_w268_stoMIA m4 : 31|1@1+ (1,0) [0|1] "" Vector__XXX
 SG_ GTW_w273_BLEEPREARLEFTversionMis m4 : 36|1@1+ (1,0) [0|1] "" Vector__XXX
 SG_ GTW_w274_BLEEPREARRIGHTversionMi m4 : 37|1@1+ (1,0) [0|1] "" Vector__XXX
 SG_ GTW_w275_VDDCORE_DrMOS_Fault m4 : 38|1@1+ (1,0) [0|1] "" Vector__XXX
 SG_ GTW_w276_VDDSOC_DrMOS_Fault m4 : 39|1@1+ (1,0) [0|1] "" Vector__XXX
 SG_ GTW_w277_NonRevCDrMOSMitigationF m4 : 40|1@1+ (1,0) [0|1] "" Vector__XXX
 SG_ GTW_w278_ethSwitchCongested m4 : 41|1@1+ (1,0) [0|1] "" Vector__XXX
 SG_ GTW_w279_adspRepeatedWatchdog m4 : 42|1@1+ (1,0) [0|1] "" Vector__XXX
 SG_ GTW_w280_hrlFrameDropped m4 : 43|1@1+ (1,0) [0|1] "" Vector__XXX
 SG_ GTW_w281_likelyMissedPoke m4 : 44|1@1+ (1,0) [0|1] "" Vector__XXX
 SG_ GTW_w282_tcuPhyConfigurationFail m4 : 45|1@1+ (1,0) [0|1] "" Vector__XXX
 SG_ GTW_w309_VCUSBversionMismatch m5 : 12|1@1+ (1,0) [0|1] "" Vector__XXX
 SG_ GTW_w311_canLogQueueFullBeforeFs m5 : 14|1@1+ (1,0) [0|1] "" Vector__XXX
 SG_ GTW_w312_hrlFileIncomplete m5 : 15|1@1+ (1,0) [0|1] "" Vector__XXX
 SG_ GTW_w313_OSDActive m5 : 16|1@1+ (1,0) [0|1] "" Vector__XXX
 SG_ GTW_w314_canLogBlockWriteErr m5 : 17|1@1+ (1,0) [0|1] "" Vector__XXX
 SG_ GTW_w316_sdCardChkdskRepair m5 : 19|1@1+ (1,0) [0|1] "" Vector__XXX
 SG_ GTW_w317_sdCardChkdskRepairFaile m5 : 20|1@1+ (1,0) [0|1] "" Vector__XXX
 SG_ GTW_w322_gestureUnrecognizedFrom m5 : 25|1@1+ (1,0) [0|1] "" Vector__XXX
 SG_ GTW_w323_gestureStartOutOfStrip m5 : 26|1@1+ (1,0) [0|1] "" Vector__XXX
 SG_ GTW_w328_smartShiftDisabled m5 : 31|1@1+ (1,0) [0|1] "" Vector__XXX
 SG_ GTW_w329_FOHMversionMismatch m5 : 32|1@1+ (1,0) [0|1] "" Vector__XXX
 SG_ GTW_w330_SWSLversionMismatch m5 : 33|1@1+ (1,0) [0|1] "" Vector__XXX
 SG_ GTW_w331_SWSRversionMismatch m5 : 34|1@1+ (1,0) [0|1] "" Vector__XXX
 SG_ GTW_w332_unknownDisplayPN m5 : 35|1@1+ (1,0) [0|1] "" Vector__XXX
 SG_ GTW_w334_hrlFolderSpaceLow m5 : 37|1@1+ (1,0) [0|1] "" Vector__XXX
 SG_ GTW_w336_possibleCanTxIssue m5 : 39|1@1+ (1,0) [0|1] "" Vector__XXX
 SG_ GTW_w342_VCBLDCPPversionMismatch m5 : 45|1@1+ (1,0) [0|1] "" Vector__XXX
 SG_ GTW_w348_VCBLDCFversionMismatch m5 : 51|1@1+ (1,0) [0|1] "" Vector__XXX
 SG_ GTW_w349_VCBLDCPBversionMismatch m5 : 52|1@1+ (1,0) [0|1] "" Vector__XXX
 SG_ GTW_w350_mOSDCrcCheck m5 : 53|1@1+ (1,0) [0|1] "" Vector__XXX
 SG_ GTW_w351_sOSDCrcCheck m5 : 54|1@1+ (1,0) [0|1] "" Vector__XXX
 SG_ GTW_w352_mASILStatusCheck m5 : 55|1@1+ (1,0) [0|1] "" Vector__XXX
 SG_ GTW_w353_sASILStatusCheck m5 : 56|1@1+ (1,0) [0|1] "" Vector__XXX
 SG_ GTW_w354_EPASTPversionMismatch m5 : 57|1@1+ (1,0) [0|1] "" Vector__XXX
 SG_ GTW_w355_EPASTSversionMismatch m5 : 58|1@1+ (1,0) [0|1] "" Vector__XXX
 SG_ GTW_w356_touchGPIOStatusCheck m5 : 59|1@1+ (1,0) [0|1] "" Vector__XXX
 SG_ GTW_w358_RGBIPFLversionMismatch m5 : 61|1@1+ (1,0) [0|1] "" Vector__XXX
 SG_ GTW_w359_RGBIPFRversionMismatch m5 : 62|1@1+ (1,0) [0|1] "" Vector__XXX
 SG_ GTW_w360_RGBDOORFLversionMismatc m5 : 63|1@1+ (1,0) [0|1] "" Vector__XXX
 SG_ GTW_w361_RGBDOORRLversionMismatc m6 : 4|1@1+ (1,0) [0|1] "" Vector__XXX
 SG_ GTW_w362_RGBDOORFRversionMismatc m6 : 5|1@1+ (1,0) [0|1] "" Vector__XXX
 SG_ GTW_w363_RGBDOORRRversionMismatc m6 : 6|1@1+ (1,0) [0|1] "" Vector__XXX
 SG_ GTW_w364_BLEEPCRADLEversionMisma m6 : 7|1@1+ (1,0) [0|1] "" Vector__XXX
 SG_ GTW_w366_uiGearRequestMismatch m6 : 9|1@1+ (1,0) [0|1] "" Vector__XXX
 SG_ GTW_w376_blFailedToExecBootImg m6 : 19|1@1+ (1,0) [0|1] "" Vector__XXX
 SG_ GTW_w380_DPBversionMismatch m6 : 23|1@1+ (1,0) [0|1] "" Vector__XXX
 SG_ GTW_w381_DPBCALversionMismatch m6 : 24|1@1+ (1,0) [0|1] "" Vector__XXX
 SG_ GTW_w382_IDBversionMismatch m6 : 25|1@1+ (1,0) [0|1] "" Vector__XXX
 SG_ GTW_w383_IDB1versionMismatch m6 : 26|1@1+ (1,0) [0|1] "" Vector__XXX
 SG_ GTW_w384_IDBCALversionMismatch m6 : 27|1@1+ (1,0) [0|1] "" Vector__XXX
 SG_ GTW_w385_RCUversionMismatch m6 : 28|1@1+ (1,0) [0|1] "" Vector__XXX
 SG_ GTW_w386_RCUCALversionMismatch m6 : 29|1@1+ (1,0) [0|1] "" Vector__XXX
 SG_ GTW_w387_externalRtcReadFailure m6 : 30|1@1+ (1,0) [0|1] "" Vector__XXX
 SG_ GTW_w388_adspWatchdogSkipped m6 : 31|1@1+ (1,0) [0|1] "" Vector__XXX
 SG_ GTW_w389_rcmEventDetected m6 : 32|1@1+ (1,0) [0|1] "" Vector__XXX
 SG_ GTW_w390_displayFwQueryFailed m6 : 33|1@1+ (1,0) [0|1] "" Vector__XXX
 SG_ GTW_w391_adspMacAddrCheckFailed m6 : 34|1@1+ (1,0) [0|1] "" Vector__XXX
 SG_ GTW_w393_osdSramCrcMismatch m6 : 36|1@1+ (1,0) [0|1] "" Vector__XXX
 SG_ GTW_w394_WIPERversionMismatch m6 : 37|1@1+ (1,0) [0|1] "" Vector__XXX
 SG_ GTW_w395_lwipIcmpError m6 : 38|1@1+ (1,0) [0|1] "" Vector__XXX
 SG_ GTW_w396_alreadyInReverse m6 : 39|1@1+ (1,0) [0|1] "" Vector__XXX
 SG_ GTW_w397_alreadyInDrive m6 : 40|1@1+ (1,0) [0|1] "" Vector__XXX
 SG_ GTW_w398_awakeForExtendedTime m6 : 41|1@1+ (1,0) [0|1] "" Vector__XXX
 SG_ GTW_w399_ethIfRxTcpipQueueDrop m6 : 42|1@1+ (1,0) [0|1] "" Vector__XXX
 SG_ GTW_w400_ethlSwitchOTPIncorrect m6 : 43|1@1+ (1,0) [0|1] "" Vector__XXX
 SG_ GTW_w401_VCSEAT2LversionMismatch m6 : 44|1@1+ (1,0) [0|1] "" Vector__XXX
 SG_ GTW_w402_VCSEAT2RversionMismatch m6 : 45|1@1+ (1,0) [0|1] "" Vector__XXX
 SG_ GTW_w409_unexpectedResetCause m6 : 52|1@1+ (1,0) [0|1] "" Vector__XXX
 SG_ GTW_w410_unexpectedResetCause2 m6 : 53|1@1+ (1,0) [0|1] "" Vector__XXX
 SG_ GTW_w411_tASILStatusCheck m6 : 54|1@1+ (1,0) [0|1] "" Vector__XXX
 SG_ GTW_w414_socHeldInReset m6 : 57|1@1+ (1,0) [0|1] "" Vector__XXX
 SG_ GTW_w418_TRCMversionMismatch m6 : 61|1@1+ (1,0) [0|1] "" Vector__XXX
 SG_ GTW_w420_unexpectedCanMessageLen m6 : 63|1@1+ (1,0) [0|1] "" Vector__XXX
 SG_ GTW_w421_ModemEthLinkDown m7 : 4|1@1+ (1,0) [0|1] "" Vector__XXX
 SG_ GTW_w422_ethSwitchSevereCongesti m7 : 5|1@1+ (1,0) [0|1] "" Vector__XXX
 SG_ GTW_w427_DISPBRIDGEversionMismat m7 : 10|1@1+ (1,0) [0|1] "" Vector__XXX
 SG_ GTW_w428_LUMBAR32LversionMismatc m7 : 11|1@1+ (1,0) [0|1] "" Vector__XXX
 SG_ GTW_w429_LUMBAR32RversionMismatc m7 : 12|1@1+ (1,0) [0|1] "" Vector__XXX
 SG_ GTW_w436_possibleCanRxIssue m7 : 19|1@1+ (1,0) [0|1] "" Vector__XXX
 SG_ GTW_w437_softFlowControlNotRunni m7 : 20|1@1+ (1,0) [0|1] "" Vector__XXX
 SG_ GTW_w438_wakeSourceUnknown m7 : 21|1@1+ (1,0) [0|1] "" Vector__XXX
 SG_ GTW_w439_VCCCversionMismatch m7 : 22|1@1+ (1,0) [0|1] "" Vector__XXX
 SG_ GTW_w450_unexpectedAutopilotCont m7 : 33|1@1+ (1,0) [0|1] "" Vector__XXX
 SG_ GTW_w451_diagCanBufferExhausted m7 : 34|1@1+ (1,0) [0|1] "" Vector__XXX
 SG_ GTW_w452_diagCanStaleSocket m7 : 35|1@1+ (1,0) [0|1] "" Vector__XXX
 SG_ GTW_w453_diagCanFdSetDesync m7 : 36|1@1+ (1,0) [0|1] "" Vector__XXX
 SG_ GTW_w454_diagCanFrameOverread m7 : 37|1@1+ (1,0) [0|1] "" Vector__XXX
 SG_ GTW_w455_hrlDumpPageOwnershipErr m7 : 38|1@1+ (1,0) [0|1] "" Vector__XXX
 SG_ GTW_w456_hrlStateMachinePageOwne m7 : 39|1@1+ (1,0) [0|1] "" Vector__XXX
 SG_ GTW_w463_displayEdidReadFailed m7 : 46|1@1+ (1,0) [0|1] "" Vector__XXX
 SG_ GTW_w469_backlightFsmUnhealthy m7 : 52|1@1+ (1,0) [0|1] "" Vector__XXX

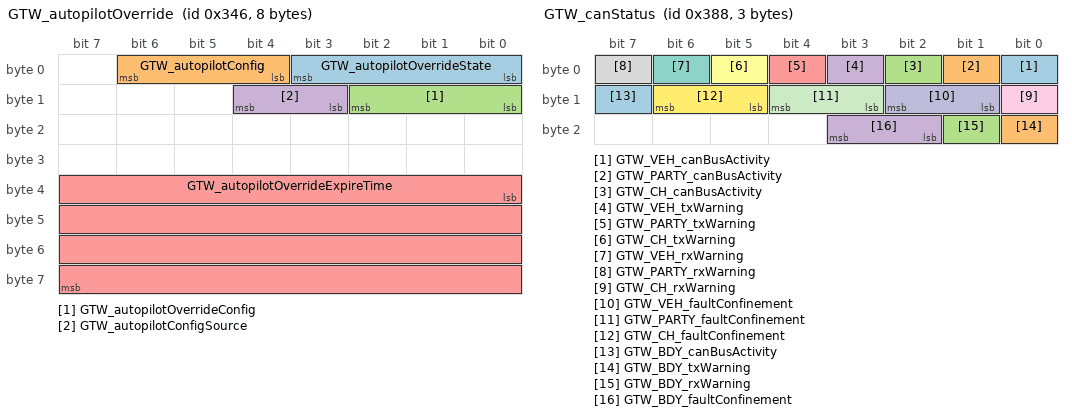
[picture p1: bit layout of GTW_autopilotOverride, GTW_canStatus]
BO_ 838 GTW_autopilotOverride: 8 GTW
 SG_ GTW_autopilotOverrideState : 0|4@1+ (1,0) [0|15] "" Vector__XXX
 SG_ GTW_autopilotConfig : 4|3@1+ (1,0) [0|7] "" Vector__XXX
 SG_ GTW_autopilotOverrideConfig : 8|3@1+ (1,0) [0|7] "" Vector__XXX
 SG_ GTW_autopilotConfigSource : 11|2@1+ (1,0) [0|3] "" Vector__XXX
 SG_ GTW_autopilotOverrideExpireTime : 32|32@1+ (1,0) [0|4294967295] "" Vector__XXX

BO_ 904 GTW_canStatus: 3 GTW
 SG_ GTW_VEH_canBusActivity : 0|1@1+ (1,0) [0|1] "" Vector__XXX
 SG_ GTW_PARTY_canBusActivity : 1|1@1+ (1,0) [0|1] "" Vector__XXX
 SG_ GTW_CH_canBusActivity : 2|1@1+ (1,0) [0|1] "" Vector__XXX
 SG_ GTW_VEH_txWarning : 3|1@1+ (1,0) [0|1] "" Vector__XXX
 SG_ GTW_PARTY_txWarning : 4|1@1+ (1,0) [0|1] "" Vector__XXX
 SG_ GTW_CH_txWarning : 5|1@1+ (1,0) [0|1] "" Vector__XXX
 SG_ GTW_VEH_rxWarning : 6|1@1+ (1,0) [0|1] "" Vector__XXX
 SG_ GTW_PARTY_rxWarning : 7|1@1+ (1,0) [0|1] "" Vector__XXX
 SG_ GTW_CH_rxWarning : 8|1@1+ (1,0) [0|1] "" Vector__XXX
 SG_ GTW_VEH_faultConfinement : 9|2@1+ (1,0) [0|3] "" Vector__XXX
 SG_ GTW_PARTY_faultConfinement : 11|2@1+ (1,0) [0|3] "" Vector__XXX
 SG_ GTW_CH_faultConfinement : 13|2@1+ (1,0) [0|3] "" Vector__XXX
 SG_ GTW_BDY_canBusActivity : 15|1@1+ (1,0) [0|1] "" Vector__XXX
 SG_ GTW_BDY_txWarning : 16|1@1+ (1,0) [0|1] "" Vector__XXX
 SG_ GTW_BDY_rxWarning : 17|1@1+ (1,0) [0|1] "" Vector__XXX
 SG_ GTW_BDY_faultConfinement : 18|2@1+ (1,0) [0|3] "" Vector__XXX

BO_ 2047 GTW_carConfig: 8 GTW
 SG_ GTW_carConfigMultiplexer M : 0|8@1+ (1,0) [0|255] "" Vector__XXX
 SG_ GTW_deliveryStatus m1 : 8|1@1+ (1,0) [0|1] "" Vector__XXX
 SG_ GTW_cabinPTCHeaterType m1 : 10|1@1+ (1,0) [0|1] "" Vector__XXX
 SG_ GTW_rightHandDrive m1 : 11|1@1+ (1,0) [0|1] "" Vector__XXX
 SG_ GTW_rearLightType m1 : 12|2@1+ (1,0) [0|3] "" Vector__XXX
 SG_ GTW_headlamps m1 : 14|2@1+ (1,0) [0|3] "" Vector__XXX
 SG_ GTW_country m1 : 16|16@1+ (1,0) [0|65535] "" Vector__XXX
 SG_ GTW_tireType m1 : 32|6@1+ (1,0) [0|63] "" Vector__XXX
 SG_ GTW_dasHw m1 : 40|3@1+ (1,0) [3|5] "" Vector__XXX
 SG_ GTW_brakeHWType m1 : 43|5@1+ (1,0) [0|31] "" Vector__XXX
 SG_ GTW_restraintsHardwareType m1 : 48|8@1+ (1,0) [0|255] "" Vector__XXX
 SG_ GTW_drivetrainType m1 : 56|4@1+ (1,0) [0|4] "" Vector__XXX
 SG_ GTW_radarHeaterType m1 : 60|3@1+ (1,0) [0|5] "" Vector__XXX
 SG_ GTW_exteriorTrimType m2 : 8|1@1+ (1,0) [0|1] "" Vector__XXX
 SG_ GTW_frontSeatHeaters m2 : 9|1@1+ (1,0) [0|1] "" Vector__XXX
 SG_ GTW_rearSeatHeaters m2 : 10|1@1+ (1,0) [0|1] "" Vector__XXX
 SG_ GTW_eCallAntennaHW m2 : 12|1@1+ (1,0) [0|1] "" Vector__XXX
 SG_ GTW_homelinkType m2 : 13|1@1+ (1,0) [0|1] "" Vector__XXX
 SG_ GTW_vdcType m2 : 14|1@1+ (1,0) [0|1] "" Vector__XXX
 SG_ GTW_memoryMirrors m2 : 17|1@1+ (1,0) [0|1] "" Vector__XXX
 SG_ GTW_powerLiftgateType m2 : 18|2@1+ (1,0) [0|2] "" Vector__XXX
 SG_ GTW_lumbarECUType m2 : 20|4@1+ (1,0) [0|15] "" Vector__XXX
 SG_ GTW_rearSeatHeaterType m2 : 24|2@1+ (1,0) [0|3] "" Vector__XXX
 SG_ GTW_auxParkLamps m2 : 26|2@1+ (1,0) [0|3] "" Vector__XXX
 SG_ GTW_interiorCabinRadarType m2 : 28|1@1+ (1,0) [0|1] "" Vector__XXX
 SG_ GTW_hvacPanelVaneType m2 : 29|1@1+ (1,0) [0|1] "" Vector__XXX
 SG_ GTW_intakeAirFilterType m2 : 30|2@1+ (1,0) [0|2] "" Vector__XXX
 SG_ GTW_eBuckConfig m2 : 32|1@1+ (1,0) [0|1] "" Vector__XXX
 SG_ GTW_steeringHeaterEnabled m2 : 33|1@1+ (1,0) [0|1] "" Vector__XXX
 SG_ GTW_activeHighBeam m2 : 34|1@1+ (1,0) [0|1] "" Vector__XXX
 SG_ GTW_airbagCutoffSwitch m2 : 35|1@1+ (1,0) [0|1] "" Vector__XXX
 SG_ GTW_intrusionSensorType m2 : 36|1@1+ (1,0) [0|1] "" Vector__XXX
 SG_ GTW_spoilerType m2 : 37|1@1+ (1,0) [0|1] "" Vector__XXX
 SG_ GTW_backupCameraType m2 : 38|1@1+ (1,0) [0|1] "" Vector__XXX
 SG_ GTW_rearFogLamps m2 : 39|1@1+ (1,0) [0|1] "" Vector__XXX
 SG_ GTW_roofType m2 : 40|1@1+ (1,0) [0|1] "" Vector__XXX
 SG_ GTW_thirdRowSeatType m2 : 41|1@1+ (1,0) [0|1] "" Vector__XXX
 SG_ GTW_autopilot m2 : 42|3@1+ (1,0) [0|7] "" Vector__XXX
 SG_ GTW_superchargingAccess m2 : 45|2@1+ (1,0) [0|3] "" Vector__XXX
 SG_ GTW_exteriorColor m2 : 48|5@1+ (1,0) [0|31] "" Vector__XXX
 SG_ GTW_pedestrianWarningSound m2 : 53|2@1+ (1,0) [0|3] "" Vector__XXX
 SG_ GTW_steeringColumnUJointType m2 : 55|1@1+ (1,0) [0|1] "" Vector__XXX
 SG_ GTW_bPillarNFCParam m2 : 56|1@1+ (1,0) [0|1] "" Vector__XXX
 SG_ GTW_interiorLighting m2 : 57|3@1+ (1,0) [0|7] "" Vector__XXX
 SG_ GTW_headlightLevelerType m2 : 60|2@1+ (1,0) [0|3] "" Vector__XXX
 SG_ GTW_numberHVILNodes m2 : 62|2@1+ (1,0) [0|3] "" Vector__XXX
 SG_ GTW_mapRegion m3 : 8|4@1+ (1,0) [0|15] "" Vector__XXX
 SG_ GTW_performancePackage m3 : 12|3@1+ (1,0) [0|7] "" Vector__XXX
 SG_ GTW_chassisType m3 : 18|4@1+ (1,0) [0|15] "" Vector__XXX
 SG_ GTW_airSuspension m3 : 22|2@1+ (1,0) [0|3] "" Vector__XXX
 SG_ GTW_centerConsoleControllerType m3 : 24|2@1+ (1,0) [0|3] "" Vector__XXX
 SG_ GTW_autopilotCameraType m3 : 26|1@1+ (1,0) [0|1] "" Vector__XXX
 SG_ GTW_connectivityPackage m3 : 27|1@1+ (1,0) [0|1] "" Vector__XXX
 SG_ GTW_plcSupportType m3 : 28|2@1+ (1,0) [0|3] "" Vector__XXX
 SG_ GTW_badgingVersion m3 : 30|2@1+ (1,0) [0|3] "" Vector__XXX
 SG_ GTW_packEnergy m3 : 32|5@1+ (1,0) [0|31] "" Vector__XXX
 SG_ GTW_frontSeatReclinerHardware m3 : 37|2@1+ (1,0) [0|3] "" Vector__XXX
 SG_ GTW_brakeLineSwitchType m3 : 39|1@1+ (1,0) [0|1] "" Vector__XXX
 SG_ GTW_espValveType m3 : 40|2@1+ (1,0) [0|3] "" Vector__XXX
 SG_ GTW_softRange m3 : 42|3@1+ (1,0) [0|7] "" Vector__XXX
 SG_ GTW_refrigerantType m3 : 45|2@1+ (1,0) [0|3] "" Vector__XXX
 SG_ GTW_wheelType m3 : 48|7@1+ (1,0) [0|127] "" Vector__XXX
 SG_ GTW_ptcControlMode m3 : 55|2@1+ (1,0) [0|3] "" Vector__XXX
 SG_ GTW_brakeActuationType m3 : 57|3@1+ (1,0) [0|4] "" Vector__XXX
 SG_ GTW_secondRowSeatType m3 : 60|3@1+ (1,0) [0|7] "" Vector__XXX
 SG_ GTW_secondRowSeatMotorType m3 : 63|1@1+ (1,0) [0|1] "" Vector__XXX
 SG_ GTW_birthday m4 : 8|32@1+ (1,0) [0|4294967295] "" Vector__XXX
 SG_ GTW_eCallEnabled m4 : 40|2@1+ (1,0) [0|3] "" Vector__XXX
 SG_ GTW_parkAssistECUType m4 : 42|2@1+ (1,0) [0|3] "" Vector__XXX
 SG_ GTW_passengerAirbagType m4 : 44|2@1+ (1,0) [0|3] "" Vector__XXX
 SG_ GTW_forwardRadarHw m4 : 46|2@1+ (1,0) [0|2] "" Vector__XXX
 SG_ GTW_frontSeatType m4 : 48|4@1+ (1,0) [0|15] "" Vector__XXX
 SG_ GTW_secondRowDisplayType m4 : 52|1@1+ (1,0) [0|1] "" Vector__XXX
 SG_ GTW_wirelessPhoneChargerType m4 : 53|2@1+ (1,0) [0|3] "" Vector__XXX
 SG_ GTW_ethernetTunerType m4 : 55|2@1+ (1,0) [0|3] "" Vector__XXX
 SG_ GTW_interiorTrimType m4 : 60|4@1+ (1,0) [0|15] "" Vector__XXX
 SG_ GTW_gloveboxUSBType m5 : 8|2@1+ (1,0) [0|3] "" Vector__XXX
 SG_ GTW_coolantPumpType m5 : 10|3@1+ (1,0) [0|7] "" Vector__XXX
 SG_ GTW_epblHwType m5 : 13|4@1+ (1,0) [0|15] "" Vector__XXX
 SG_ GTW_epbrHwType m5 : 17|4@1+ (1,0) [0|15] "" Vector__XXX
 SG_ GTW_blowerMotorType m5 : 21|2@1+ (1,0) [0|3] "" Vector__XXX
 SG_ GTW_rearLeftBLEEndpointParameter m5 : 23|1@1+ (1,0) [0|1] "" Vector__XXX
 SG_ GTW_powerMirrorFoldType m5 : 24|1@1+ (1,0) [0|1] "" Vector__XXX
 SG_ GTW_frontUsbHubType m5 : 27|3@1+ (1,0) [0|5] "" Vector__XXX
 SG_ GTW_superManifoldType m5 : 30|2@1+ (1,0) [0|3] "" Vector__XXX
 SG_ GTW_rcmLocation m5 : 32|1@1+ (1,0) [0|1] "" Vector__XXX
 SG_ GTW_autopilotExteriorCameraType m5 : 33|1@1+ (1,0) [0|1] "" Vector__XXX
 SG_ GTW_interiorCamBeautyCoverType m5 : 35|2@1+ (1,0) [0|3] "" Vector__XXX
 SG_ GTW_sirenType m5 : 37|1@1+ (1,0) [0|1] "" Vector__XXX
 SG_ GTW_hornType m5 : 38|1@1+ (1,0) [0|1] "" Vector__XXX
 SG_ GTW_passengerTrackMotorType m5 : 40|1@1+ (1,0) [0|1] "" Vector__XXX
 SG_ GTW_steeringColumnMotorType m5 : 42|2@1+ (1,0) [0|3] "" Vector__XXX
 SG_ GTW_refrigACLineType m5 : 48|2@1+ (1,0) [0|3] "" Vector__XXX
 SG_ GTW_refrigFilterType m5 : 50|2@1+ (1,0) [0|3] "" Vector__XXX
 SG_ GTW_diBurnInType m5 : 52|1@1+ (1,0) [0|1] "" Vector__XXX
 SG_ GTW_specialBadgingType m5 : 53|2@1+ (1,0) [0|3] "" Vector__XXX
 SG_ GTW_chassisSubType m5 : 55|3@1+ (1,0) [0|7] "" Vector__XXX
 SG_ GTW_towPackage m5 : 58|2@1+ (1,0) [0|3] "" Vector__XXX
 SG_ GTW_refrigLccType m5 : 60|1@1+ (1,0) [0|1] "" Vector__XXX
 SG_ GTW_restraintControlsType m5 : 61|1@1+ (1,0) [0|1] "" Vector__XXX
 SG_ GTW_caliperColorType m5 : 62|2@1+ (1,0) [0|3] "" Vector__XXX
 SG_ GTW_wiperMotorType m6 : 9|1@1+ (1,0) [0|1] "" Vector__XXX
 SG_ GTW_frontOverheadConsoleType m6 : 10|2@1+ (1,0) [0|3] "" Vector__XXX
 SG_ GTW_shifterType m6 : 12|1@1+ (1,0) [0|1] "" Vector__XXX
 SG_ GTW_compressorType m6 : 13|4@1+ (1,0) [0|15] "" Vector__XXX
 SG_ GTW_twelveVBatteryType m6 : 17|3@1+ (1,0) [0|7] "" Vector__XXX
 SG_ GTW_efuseSWConfig m6 : 20|3@1+ (1,0) [0|7] "" Vector__XXX
 SG_ GTW_tollCollectionModuleType m6 : 23|1@1+ (1,0) [0|1] "" Vector__XXX
 SG_ GTW_bleEndpointUpdateMethod m6 : 24|1@1+ (1,0) [0|1] "" Vector__XXX
 SG_ GTW_steeringWheelControllerType m6 : 25|3@1+ (1,0) [0|7] "" Vector__XXX
 SG_ GTW_frontSeatVentilationEnabled m6 : 28|1@1+ (1,0) [0|1] "" Vector__XXX
 SG_ GTW_gloveboxActuatorType m6 : 29|2@1+ (1,0) [0|3] "" Vector__XXX
 SG_ GTW_epasType m6 : 32|4@1+ (1,0) [0|11] "" Vector__XXX
 SG_ GTW_homologationRegionOverride m6 : 36|2@1+ (1,0) [0|3] "" Vector__XXX
 SG_ GTW_windowCommandsPermissionType m6 : 38|2@1+ (1,0) [0|3] "" Vector__XXX
 SG_ GTW_headlightStepperStallDetectM m6 : 42|1@1+ (1,0) [0|1] "" Vector__XXX
 SG_ GTW_rgbInteriorLightingEnabled m6 : 43|2@1+ (1,0) [0|3] "" Vector__XXX
 SG_ GTW_windshieldWiperHeaterType m6 : 45|1@1+ (1,0) [0|1] "" Vector__XXX
 SG_ GTW_thirdRowSeatReclinerType m6 : 46|1@1+ (1,0) [0|1] "" Vector__XXX
 SG_ GTW_driveInterfaceType m6 : 47|1@1+ (1,0) [0|1] "" Vector__XXX
 SG_ GTW_efficiencyPackage m6 : 49|6@1+ (1,0) [0|63] "" Vector__XXX
 SG_ GTW_visorLightType m6 : 55|1@1+ (1,0) [0|1] "" Vector__XXX
 SG_ GTW_gnssAntennaType m6 : 58|2@1+ (1,0) [0|3] "" Vector__XXX
 SG_ GTW_airDistributionBoxType m6 : 60|1@1+ (1,0) [0|1] "" Vector__XXX
 SG_ GTW_frontSeatHeatersEnabled m6 : 62|1@1+ (1,0) [0|1] "" Vector__XXX
 SG_ GTW_windshieldWiperHeaterEnabled m6 : 63|1@1+ (1,0) [0|1] "" Vector__XXX
 SG_ GTW_alcoholInterlockType m7 : 8|1@1+ (1,0) [0|1] "" Vector__XXX
 SG_ GTW_fasciaType m7 : 9|4@1+ (1,0) [0|15] "" Vector__XXX
 SG_ GTW_powerSteeringColumn m7 : 13|1@1+ (1,0) [0|1] "" Vector__XXX
 SG_ GTW_frontSeatHeaterType m7 : 14|1@1+ (1,0) [0|1] "" Vector__XXX
 SG_ GTW_softPerformanceLimit m7 : 15|4@1+ (1,0) [0|15] "" Vector__XXX
 SG_ GTW_gsrFeatureType m7 : 21|2@1+ (1,0) [0|2] "" Vector__XXX
 SG_ GTW_immersiveAudio m7 : 23|2@1+ (1,0) [0|3] "" Vector__XXX
 SG_ GTW_frontSeatVentilationType m7 : 25|1@1+ (1,0) [0|1] "" Vector__XXX
 SG_ GTW_passengerOccupancySensorType m7 : 26|3@1+ (1,0) [0|7] "" Vector__XXX
 SG_ GTW_packPerformanceDeviation m7 : 30|3@1+ (1,0) [0|7] "" Vector__XXX
 SG_ GTW_pressurePadType m7 : 33|2@1+ (1,0) [0|3] "" Vector__XXX
 SG_ GTW_frontFogLamps m7 : 35|1@1+ (1,0) [0|1] "" Vector__XXX
 SG_ GTW_driverOccupancySensorType m7 : 36|1@1+ (1,0) [0|1] "" Vector__XXX
 SG_ GTW_audioType m7 : 37|3@1+ (1,0) [0|7] "" Vector__XXX
 SG_ GTW_thighExtenderType m7 : 41|1@1+ (1,0) [0|1] "" Vector__XXX
 SG_ GTW_occupancyClassificationFeatu m7 : 42|1@1+ (1,0) [0|1] "" Vector__XXX
 SG_ GTW_frontControllerArchitectureT m7 : 46|1@1+ (1,0) [0|1] "" Vector__XXX
 SG_ GTW_domeLightType m7 : 47|2@1+ (1,0) [0|3] "" Vector__XXX
 SG_ GTW_tpmsType m7 : 49|2@1+ (1,0) [0|3] "" Vector__XXX
 SG_ GTW_authenticationEndpointLayout m7 : 52|3@1+ (1,0) [0|6] "" Vector__XXX
 SG_ GTW_socSleepOverride m7 : 57|2@1+ (1,0) [0|3] "" Vector__XXX
 SG_ GTW_r79BehaviorOverride m7 : 59|1@1+ (1,0) [0|1] "" Vector__XXX
 SG_ GTW_steeringHeaterType m7 : 60|3@1+ (1,0) [0|7] "" Vector__XXX
 SG_ GTW_narrowWipingSupported m7 : 63|1@1+ (1,0) [0|1] "" Vector__XXX
 SG_ GTW_frontSeatHeaterGridType m8 : 8|1@1+ (1,0) [0|1] "" Vector__XXX
 SG_ GTW_frontSeatSideSwitchType m8 : 9|1@1+ (1,0) [0|1] "" Vector__XXX
 SG_ GTW_sohRegulatoryStatus m8 : 10|1@1+ (1,0) [0|1] "" Vector__XXX
 SG_ GTW_passengerTiltMotorType m8 : 11|2@1+ (1,0) [0|3] "" Vector__XXX
 SG_ GTW_frunkInteriorReleaseType m8 : 15|1@1+ (1,0) [0|1] "" Vector__XXX
 SG_ GTW_m3yBusArchitecture m8 : 17|2@1+ (1,0) [0|3] "" Vector__XXX
 SG_ GTW_passengerLiftMotorType m8 : 19|2@1+ (1,0) [0|3] "" Vector__XXX
 SG_ GTW_interiorUpperTrimType m8 : 21|1@1+ (1,0) [0|1] "" Vector__XXX
 SG_ GTW_blindSpotIndicatorLightType m8 : 22|2@1+ (1,0) [0|3] "" Vector__XXX
 SG_ GTW_wiperMotorAsicType m8 : 24|2@1+ (1,0) [0|3] "" Vector__XXX
 SG_ GTW_hvacCaseDoorType m8 : 28|1@1+ (1,0) [0|1] "" Vector__XXX
 SG_ GTW_occupancyDetectionSourceRequ m8 : 29|1@1+ (1,0) [0|1] "" Vector__XXX
 SG_ GTW_rduCableType m8 : 31|1@1+ (1,0) [0|1] "" Vector__XXX
 SG_ GTW_parkTelltaleBehaviorType m8 : 32|1@1+ (1,0) [0|1] "" Vector__XXX
 SG_ GTW_numberKeyCardsPairedInFactor m8 : 35|2@1+ (1,0) [0|2] "" Vector__XXX
 SG_ GTW_secondRowSeatVentilationType m8 : 37|1@1+ (1,0) [0|1] "" Vector__XXX
 SG_ GTW_thirdRowSeatHeaterType m8 : 38|1@1+ (1,0) [0|1] "" Vector__XXX
 SG_ GTW_interiorCameraType m8 : 39|2@1+ (1,0) [0|2] "" Vector__XXX
 SG_ GTW_frontFasciaCameraType m8 : 41|2@1+ (1,0) [0|3] "" Vector__XXX
 SG_ GTW_interiorCamFanType m8 : 45|3@1+ (1,0) [0|7] "" Vector__XXX
 SG_ GTW_puddleLampType m8 : 50|2@1+ (1,0) [0|2] "" Vector__XXX
 SG_ GTW_solarLensType m8 : 52|2@1+ (1,0) [0|2] "" Vector__XXX
 SG_ GTW_liftgateGeometryType m8 : 56|2@1+ (1,0) [0|3] "" Vector__XXX
 SG_ GTW_repeaterAeroRibType m8 : 60|3@1+ (1,0) [0|7] "" Vector__XXX
 SG_ GTW_highTipForceWiperArmsType m8 : 63|1@1+ (1,0) [0|1] "" Vector__XXX
 SG_ GTW_rcmUndersideAbuseZThreshold m9 : 8|3@1+ (1,0) [0|7] "" Vector__XXX
 SG_ GTW_rcmUndersideAbuseYThreshold m9 : 11|3@1+ (1,0) [0|7] "" Vector__XXX
 SG_ GTW_rcmUndersideAbuseWindow m9 : 14|2@1+ (1,0) [0|3] "" Vector__XXX
 SG_ GTW_uhfChargePortEnabled m9 : 16|1@1+ (1,0) [0|1] "" Vector__XXX
 SG_ GTW_automaticFeatureResetPackage m9 : 18|1@1+ (1,0) [0|1] "" Vector__XXX
 SG_ GTW_autopilotFeaturePackage m9 : 20|2@1+ (1,0) [0|2] "" Vector__XXX
 SG_ GTW_doorLatchType m9 : 23|1@1+ (1,0) [0|1] "" Vector__XXX
 SG_ GTW_headlinerMaterialType m9 : 25|2@1+ (1,0) [0|3] "" Vector__XXX
 SG_ GTW_glareShieldHeaterType m9 : 27|1@1+ (1,0) [0|1] "" Vector__XXX
 SG_ GTW_rearLightHardwareVariant m9 : 29|2@1+ (1,0) [0|3] "" Vector__XXX
 SG_ GTW_fasciaHarnessCleanPointType m9 : 31|2@1+ (1,0) [0|3] "" Vector__XXX
 SG_ GTW_epasSubType m9 : 33|1@1+ (1,0) [0|1] "" Vector__XXX
 SG_ GTW_wiperSupplyChainOrigin m9 : 35|2@1+ (1,0) [1|3] "" Vector__XXX
 SG_ GTW_windowPinchParameterType m9 : 37|2@1+ (1,0) [0|3] "" Vector__XXX
 SG_ GTW_badgingMaterialType m9 : 39|1@1+ (1,0) [0|1] "" Vector__XXX
 SG_ GTW_mRecordVersion m9 : 40|1@1+ (1,0) [0|1] "" Vector__XXX
 SG_ GTW_tcuType m9 : 47|2@1+ (1,0) [0|2] "" Vector__XXX
 SG_ GTW_carbComplianceBehaviorType m9 : 49|1@1+ (1,0) [0|1] "" Vector__XXX
 SG_ GTW_indirectTPMSCalibrationType m9 : 55|3@1+ (1,0) [0|7] "" Vector__XXX
 SG_ GTW_v2xEnabled m9 : 58|1@1+ (1,0) [0|1] "" Vector__XXX
 SG_ GTW_liftgateStrutType m9 : 60|1@1+ (1,0) [0|1] "" Vector__XXX
 SG_ GTW_exteriorMicrophoneType m9 : 63|1@1+ (1,0) [0|1] "" Vector__XXX
 SG_ GTW_contactorPowerSource m10 : 20|1@1+ (1,0) [0|1] "" Vector__XXX
 SG_ GTW_roofGlassType m10 : 21|3@1+ (1,0) [0|7] "" Vector__XXX
 SG_ GTW_pedalMapNameOverride m10 : 25|1@1+ (1,0) [0|1] "" Vector__XXX

BO_ 792 GTW_carState: 8 GTW
 SG_ GTW_factoryGated : 48|1@1+ (1,0) [0|1] "" Vector__XXX

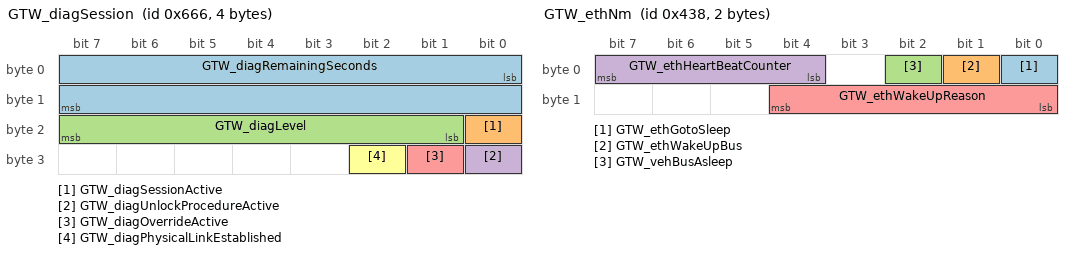
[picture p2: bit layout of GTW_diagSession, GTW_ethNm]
BO_ 1638 GTW_diagSession: 4 GTW
 SG_ GTW_diagRemainingSeconds : 0|16@1+ (1,0) [0|65535] "seconds" Vector__XXX
 SG_ GTW_diagSessionActive : 16|1@1+ (1,0) [0|1] "" Vector__XXX
 SG_ GTW_diagLevel : 17|7@1+ (1,0) [0|127] "" Vector__XXX
 SG_ GTW_diagUnlockProcedureActive : 24|1@1+ (1,0) [0|1] "" Vector__XXX
 SG_ GTW_diagOverrideActive : 25|1@1+ (1,0) [0|1] "" Vector__XXX
 SG_ GTW_diagPhysicalLinkEstablished : 26|1@1+ (1,0) [0|1] "" Vector__XXX

BO_ 1080 GTW_ethNm: 2 GTW
 SG_ GTW_ethGotoSleep : 0|1@1+ (1,0) [0|1] "" Vector__XXX
 SG_ GTW_ethWakeUpBus : 1|1@1+ (1,0) [0|1] "" Vector__XXX
 SG_ GTW_vehBusAsleep : 2|1@1+ (1,0) [0|1] "" Vector__XXX
 SG_ GTW_ethHeartBeatCounter : 4|4@1+ (1,0) [0|15] "" Vector__XXX
 SG_ GTW_ethWakeUpReason : 8|5@1+ (1,0) [0|31] "" Vector__XXX

BO_ 1376 GTW_factoryEcuPresent: 4 GTW
 SG_ GTW_OCS1Ppresent : 0|1@1+ (1,0) [0|1] "" Vector__XXX
 SG_ GTW_PCSpresent : 1|1@1+ (1,0) [0|1] "" Vector__XXX
 SG_ GTW_HVPpresent : 2|1@1+ (1,0) [0|1] "" Vector__XXX
 SG_ GTW_BMSpresent : 3|1@1+ (1,0) [0|1] "" Vector__XXX
 SG_ GTW_CPpresent : 4|1@1+ (1,0) [0|1] "" Vector__XXX
 SG_ GTW_RCMpresent : 5|1@1+ (1,0) [0|1] "" Vector__XXX
 SG_ GTW_SCCMpresent : 6|1@1+ (1,0) [0|1] "" Vector__XXX
 SG_ GTW_VCSECpresent : 7|1@1+ (1,0) [0|1] "" Vector__XXX
 SG_ GTW_EPAS3Ppresent : 8|1@1+ (1,0) [0|1] "" Vector__XXX
 SG_ GTW_EPBLpresent : 9|1@1+ (1,0) [0|1] "" Vector__XXX
 SG_ GTW_EPBRpresent : 10|1@1+ (1,0) [0|1] "" Vector__XXX
 SG_ GTW_ESPpresent : 11|1@1+ (1,0) [0|1] "" Vector__XXX
 SG_ GTW_IBSTpresent : 12|1@1+ (1,0) [0|1] "" Vector__XXX
 SG_ GTW_PARKpresent : 13|1@1+ (1,0) [0|1] "" Vector__XXX
 SG_ GTW_RADCpresent : 14|1@1+ (1,0) [0|1] "" Vector__XXX
 SG_ GTW_TPMSpresent : 15|1@1+ (1,0) [0|1] "" Vector__XXX
 SG_ GTW_VCFRONTpresent : 16|1@1+ (1,0) [0|1] "" Vector__XXX
 SG_ GTW_VCLEFTpresent : 17|1@1+ (1,0) [0|1] "" Vector__XXX
 SG_ GTW_VCRIGHTpresent : 18|1@1+ (1,0) [0|1] "" Vector__XXX
 SG_ GTW_EPAS3Spresent : 19|1@1+ (1,0) [0|1] "" Vector__XXX
 SG_ GTW_CMPpresent : 20|1@1+ (1,0) [0|1] "" Vector__XXX
 SG_ GTW_DASpresent : 21|1@1+ (1,0) [0|1] "" Vector__XXX
 SG_ GTW_PTCpresent : 22|1@1+ (1,0) [0|1] "" Vector__XXX
 SG_ GTW_SWCpresent : 23|1@1+ (1,0) [0|1] "" Vector__XXX
 SG_ GTW_PMRpresent : 25|1@1+ (1,0) [0|1] "" Vector__XXX
 SG_ GTW_PMFpresent : 26|1@1+ (1,0) [0|1] "" Vector__XXX
 SG_ GTW_DIRpresent : 27|1@1+ (1,0) [0|1] "" Vector__XXX
 SG_ GTW_DIFpresent : 28|1@1+ (1,0) [0|1] "" Vector__XXX

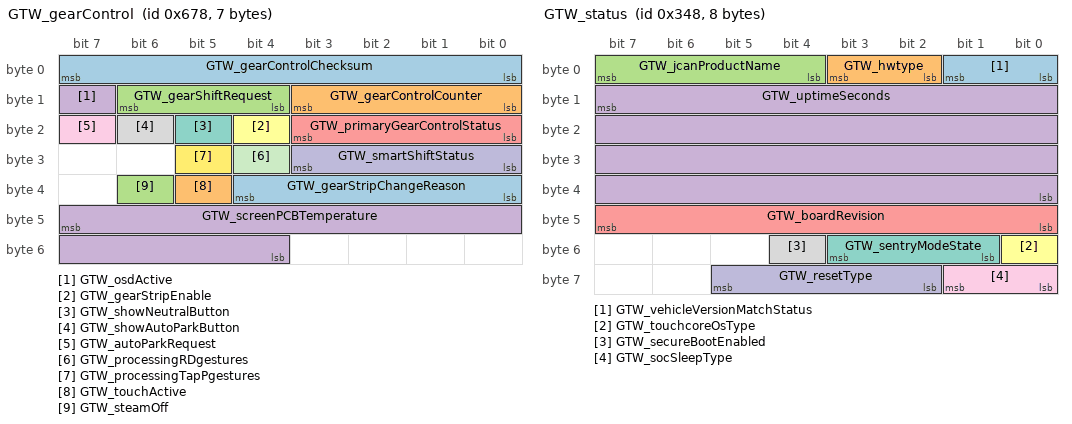
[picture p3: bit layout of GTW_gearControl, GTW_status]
BO_ 1656 GTW_gearControl: 7 GTW
 SG_ GTW_gearControlChecksum : 0|8@1+ (1,0) [0|255] "" Vector__XXX
 SG_ GTW_gearControlCounter : 8|4@1+ (1,0) [0|15] "" Vector__XXX
 SG_ GTW_gearShiftRequest : 12|3@1+ (1,0) [1|7] "" Vector__XXX
 SG_ GTW_osdActive : 15|1@1+ (1,0) [0|1] "" Vector__XXX
 SG_ GTW_primaryGearControlStatus : 16|4@1+ (1,0) [0|15] "" Vector__XXX
 SG_ GTW_gearStripEnable : 20|1@1+ (1,0) [0|1] "" Vector__XXX
 SG_ GTW_showNeutralButton : 21|1@1+ (1,0) [0|1] "" Vector__XXX
 SG_ GTW_showAutoParkButton : 22|1@1+ (1,0) [0|1] "" Vector__XXX
 SG_ GTW_autoParkRequest : 23|1@1+ (1,0) [0|1] "" Vector__XXX
 SG_ GTW_smartShiftStatus : 24|4@1+ (1,0) [1|15] "" Vector__XXX
 SG_ GTW_processingRDgestures : 28|1@1+ (1,0) [0|1] "" Vector__XXX
 SG_ GTW_processingTapPgestures : 29|1@1+ (1,0) [0|1] "" Vector__XXX
 SG_ GTW_gearStripChangeReason : 32|5@1+ (1,0) [1|31] "" Vector__XXX
 SG_ GTW_touchActive : 37|1@1+ (1,0) [0|1] "" Vector__XXX
 SG_ GTW_steamOff : 38|1@1+ (1,0) [0|1] "" Vector__XXX
 SG_ GTW_screenPCBTemperature : 47|12@0- (0.0625,0) [-128|127.875] "degC" Vector__XXX

BO_ 2033 GTW_hrl: 7 GTW
 SG_ GTW_hrlIndex M : 0|2@1+ (1,0) [0|3] "" Vector__XXX
 SG_ GTW_hrlPagesCount m1 : 15|32@0+ (1,0) [0|4294967295] "" Vector__XXX
 SG_ GTW_hrlSdCardSizeGB m1 : 40|8@1+ (1,0) [1|255] "" Vector__XXX
 SG_ GTW_hrlState m2 : 2|1@1+ (1,0) [0|1] "" Vector__XXX
 SG_ GTW_hrlTriggerDuration m2 : 15|16@0+ (1,0) [0|65535] "seconds" Vector__XXX
 SG_ GTW_hrlTriggerType m2 : 24|4@1+ (1,0) [0|15] "" Vector__XXX
 SG_ GTW_hrlTriggerId m2 : 39|16@0+ (1,0) [0|65535] "" Vector__XXX
 SG_ GTW_hrlTriggerBus m2 : 53|3@1+ (1,0) [0|7] "" Vector__XXX

BO_ 2026 GTW_hrlExternalEvent: 8 GTW
 SG_ GTW_hrlEventStartEpoch : 7|32@0+ (1,0) [0|4294967295] "seconds" Vector__XXX
 SG_ GTW_hrlEventEndEpoch : 39|32@0+ (1,0) [0|4294967295] "seconds" Vector__XXX

BO_ 60 GTW_info: 8 GTW
 SG_ GTW_infoIndex M : 0|8@1+ (1,0) [0|255] "" Vector__XXX
 SG_ GTW_buildType m10 : 8|3@1+ (1,0) [0|7] "" Vector__XXX
 SG_ GTW_hardwareId m10 : 32|16@1+ (1,0) [0|65535] "" Vector__XXX
 SG_ GTW_platformType m13 : 8|8@1+ (1,0) [0|255] "" Vector__XXX
 SG_ GTW_appCrc m13 : 32|32@1+ (1,0) [0|4294967295] "" Vector__XXX
 SG_ GTW_applicationGitHash m17 : 8|56@1+ (1,0) [0|7.20575940379e+16] "" Vector__XXX
 SG_ GTW_bootGitHash m18 : 8|56@1+ (1,0) [0|7.20575940379e+16] "" Vector__XXX

BO_ 1370 GTW_mismatchFault: 8 GTW
 SG_ GTW_mismatchFaultIndex M : 0|3@1+ (1,0) [0|7] "" Vector__XXX
 SG_ GTW_mismatchFaultChecksum : 3|8@1+ (1,0) [0|255] "" Vector__XXX
 SG_ GTW_mismatchFaultCounter : 11|4@1+ (1,0) [0|15] "" Vector__XXX
 SG_ GTW_GTWmismatchFault m1 : 15|1@1+ (1,0) [0|1] "" Vector__XXX
 SG_ GTW_BMSmismatchFault m1 : 16|1@1+ (1,0) [0|1] "" Vector__XXX
 SG_ GTW_APSmismatchFault m1 : 17|1@1+ (1,0) [0|1] "" Vector__XXX
 SG_ GTW_BLEEPCENTERmismatchFault m1 : 18|1@1+ (1,0) [0|1] "" Vector__XXX
 SG_ GTW_BLEEPLEFTmismatchFault m1 : 19|1@1+ (1,0) [0|1] "" Vector__XXX
 SG_ GTW_BLEEPREARmismatchFault m1 : 20|1@1+ (1,0) [0|1] "" Vector__XXX
 SG_ GTW_BLEEPRIGHTmismatchFault m1 : 21|1@1+ (1,0) [0|1] "" Vector__XXX
 SG_ GTW_CBCmismatchFault m1 : 22|1@1+ (1,0) [0|1] "" Vector__XXX
 SG_ GTW_CMPmismatchFault m1 : 23|1@1+ (1,0) [0|1] "" Vector__XXX
 SG_ GTW_CPmismatchFault m1 : 24|1@1+ (1,0) [0|1] "" Vector__XXX
 SG_ GTW_DIFmismatchFault m1 : 25|1@1+ (1,0) [0|1] "" Vector__XXX
 SG_ GTW_DIRmismatchFault m1 : 26|1@1+ (1,0) [0|1] "" Vector__XXX
 SG_ GTW_EPAS3PmismatchFault m1 : 27|1@1+ (1,0) [0|1] "" Vector__XXX
 SG_ GTW_EPAS3SmismatchFault m1 : 28|1@1+ (1,0) [0|1] "" Vector__XXX
 SG_ GTW_EPBLmismatchFault m1 : 29|1@1+ (1,0) [0|1] "" Vector__XXX
 SG_ GTW_EPBRmismatchFault m1 : 30|1@1+ (1,0) [0|1] "" Vector__XXX
 SG_ GTW_ESPCALmismatchFault m1 : 31|1@1+ (1,0) [0|1] "" Vector__XXX
 SG_ GTW_ESPmismatchFault m1 : 32|1@1+ (1,0) [0|1] "" Vector__XXX
 SG_ GTW_HCM3LmismatchFault m1 : 33|1@1+ (1,0) [0|1] "" Vector__XXX
 SG_ GTW_HCM3RmismatchFault m1 : 34|1@1+ (1,0) [0|1] "" Vector__XXX
 SG_ GTW_HCMLmismatchFault m1 : 35|1@1+ (1,0) [0|1] "" Vector__XXX
 SG_ GTW_HCMRmismatchFault m1 : 36|1@1+ (1,0) [0|1] "" Vector__XXX
 SG_ GTW_HVPmismatchFault m1 : 37|1@1+ (1,0) [0|1] "" Vector__XXX
 SG_ GTW_IBSTCALmismatchFault m1 : 38|1@1+ (1,0) [0|1] "" Vector__XXX
 SG_ GTW_IBSTmismatchFault m1 : 39|1@1+ (1,0) [0|1] "" Vector__XXX
 SG_ GTW_LVBMSmismatchFault m1 : 40|1@1+ (1,0) [0|1] "" Vector__XXX
 SG_ GTW_OCS1PmismatchFault m1 : 41|1@1+ (1,0) [0|1] "" Vector__XXX
 SG_ GTW_OPCFmismatchFault m1 : 42|1@1+ (1,0) [0|1] "" Vector__XXX
 SG_ GTW_OPCRmismatchFault m1 : 43|1@1+ (1,0) [0|1] "" Vector__XXX
 SG_ GTW_PARKmismatchFault m1 : 44|1@1+ (1,0) [0|1] "" Vector__XXX
 SG_ GTW_PCSCPU2mismatchFault m1 : 45|1@1+ (1,0) [0|1] "" Vector__XXX
 SG_ GTW_PCSmismatchFault m1 : 46|1@1+ (1,0) [0|1] "" Vector__XXX
 SG_ GTW_PMFmismatchFault m1 : 47|1@1+ (1,0) [0|1] "" Vector__XXX
 SG_ GTW_PMRmismatchFault m1 : 48|1@1+ (1,0) [0|1] "" Vector__XXX
 SG_ GTW_PTCmismatchFault m1 : 49|1@1+ (1,0) [0|1] "" Vector__XXX
 SG_ GTW_RCMCALmismatchFault m1 : 50|1@1+ (1,0) [0|1] "" Vector__XXX
 SG_ GTW_RCMmismatchFault m1 : 51|1@1+ (1,0) [0|1] "" Vector__XXX
 SG_ GTW_SCCMmismatchFault m1 : 52|1@1+ (1,0) [0|1] "" Vector__XXX
 SG_ GTW_SDCRmismatchFault m1 : 53|1@1+ (1,0) [0|1] "" Vector__XXX
 SG_ GTW_SWCmismatchFault m1 : 54|1@1+ (1,0) [0|1] "" Vector__XXX
 SG_ GTW_THSmismatchFault m1 : 55|1@1+ (1,0) [0|1] "" Vector__XXX
 SG_ GTW_VCFRONTmismatchFault m1 : 56|1@1+ (1,0) [0|1] "" Vector__XXX
 SG_ GTW_VCLEFTmismatchFault m1 : 57|1@1+ (1,0) [0|1] "" Vector__XXX
 SG_ GTW_VCRIGHTmismatchFault m1 : 58|1@1+ (1,0) [0|1] "" Vector__XXX
 SG_ GTW_VCSECmismatchFault m1 : 59|1@1+ (1,0) [0|1] "" Vector__XXX
 SG_ GTW_PMmismatchFault m1 : 60|1@1+ (1,0) [0|1] "" Vector__XXX

BO_ 840 GTW_status: 8 GTW
 SG_ GTW_vehicleVersionMatchStatus : 0|2@1+ (1,0) [0|3] "" Vector__XXX
 SG_ GTW_hwtype : 2|2@1+ (1,0) [1|3] "" Vector__XXX
 SG_ GTW_jcanProductName : 4|4@1+ (1,0) [1|15] "" Vector__XXX
 SG_ GTW_uptimeSeconds : 15|32@0+ (1,0) [0|4294967295] "s" Vector__XXX
 SG_ GTW_boardRevision : 40|8@1+ (1,0) [0|255] "" Vector__XXX
 SG_ GTW_touchcoreOsType : 48|1@1+ (1,0) [0|1] "" Vector__XXX
 SG_ GTW_sentryModeState : 49|3@1+ (1,0) [0|7] "" Vector__XXX
 SG_ GTW_secureBootEnabled : 52|1@1+ (1,0) [0|1] "" Vector__XXX
 SG_ GTW_socSleepType : 56|2@1+ (1,0) [1|3] "" Vector__XXX
 SG_ GTW_resetType : 58|4@1+ (1,0) [1|15] "" Vector__XXX

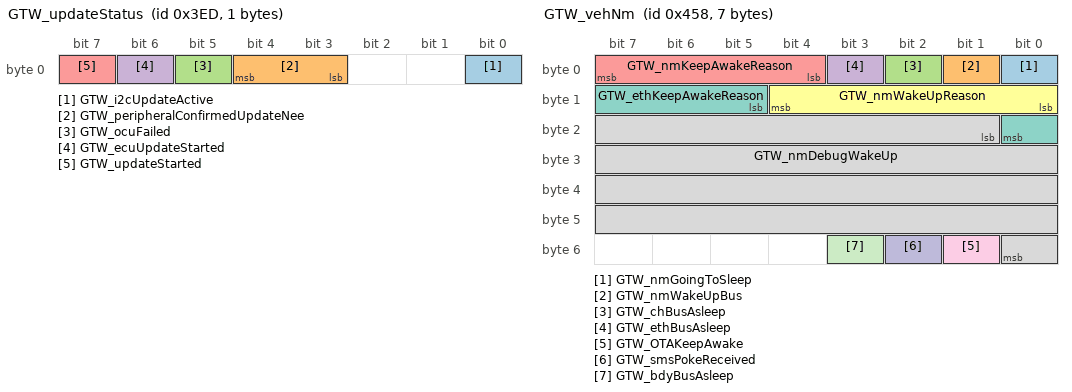
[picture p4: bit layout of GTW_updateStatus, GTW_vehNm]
BO_ 1005 GTW_updateStatus: 1 GTW
 SG_ GTW_i2cUpdateActive : 0|1@1+ (1,0) [0|1] "" Vector__XXX
 SG_ GTW_peripheralConfirmedUpdateNee : 3|2@1+ (1,0) [0|3] "" Vector__XXX
 SG_ GTW_ocuFailed : 5|1@1+ (1,0) [0|1] "" Vector__XXX
 SG_ GTW_ecuUpdateStarted : 6|1@1+ (1,0) [0|1] "" Vector__XXX
 SG_ GTW_updateStarted : 7|1@1+ (1,0) [0|1] "" Vector__XXX

BO_ 1112 GTW_vehNm: 7 GTW
 SG_ GTW_nmGoingToSleep : 0|1@1+ (1,0) [0|1] "" Vector__XXX
 SG_ GTW_nmWakeUpBus : 1|1@1+ (1,0) [0|1] "" Vector__XXX
 SG_ GTW_chBusAsleep : 2|1@1+ (1,0) [0|1] "" Vector__XXX
 SG_ GTW_ethBusAsleep : 3|1@1+ (1,0) [0|1] "" Vector__XXX
 SG_ GTW_nmKeepAwakeReason : 4|4@1+ (1,0) [1|15] "" Vector__XXX
 SG_ GTW_nmWakeUpReason : 8|5@1+ (1,0) [0|31] "" Vector__XXX
 SG_ GTW_ethKeepAwakeReason : 13|4@1+ (1,0) [1|15] "" Vector__XXX
 SG_ GTW_nmDebugWakeUp : 17|32@1+ (1,0) [0|4294967295] "" Vector__XXX
 SG_ GTW_OTAKeepAwake : 49|1@1+ (1,0) [0|1] "" Vector__XXX
 SG_ GTW_smsPokeReceived : 50|1@1+ (1,0) [0|1] "" Vector__XXX
 SG_ GTW_bdyBusAsleep : 51|1@1+ (1,0) [0|1] "" Vector__XXX

BO_ 1650 HCML_info: 8 HCML
 SG_ VC_hcmlInfoIndex M : 0|4@1+ (1,0) [0|15] "" Vector__XXX
 SG_ VC_infoHCMLBuildConfigId m0 : 8|16@1+ (1,0) [0|65535] "" Vector__XXX
 SG_ VC_leftHeadlampLMMVariant m0 : 24|2@1+ (1,0) [1|3] "" Vector__XXX
 SG_ VC_infoHCMLAssemblyId m1 : 8|16@1+ (1,0) [0|65535] "" Vector__XXX
 SG_ VC_infoHCMLPcbaId m1 : 24|16@1+ (1,0) [0|65535] "" Vector__XXX
 SG_ VC_infoHCMLUsageId m1 : 40|16@1+ (1,0) [0|65535] "" Vector__XXX

BO_ 1980 HCMR_info: 8 HCMR
 SG_ VC_hcmrInfoIndex M : 0|4@1+ (1,0) [0|15] "" Vector__XXX
 SG_ VC_infoHCMRBuildConfigId m0 : 8|16@1+ (1,0) [0|65535] "" Vector__XXX
 SG_ VC_rightHeadlampLMMVariant m0 : 24|2@1+ (1,0) [1|3] "" Vector__XXX
 SG_ VC_infoHCMRAssemblyId m1 : 8|16@1+ (1,0) [0|65535] "" Vector__XXX
 SG_ VC_infoHCMRPcbaId m1 : 24|16@1+ (1,0) [0|65535] "" Vector__XXX
 SG_ VC_infoHCMRUsageId m1 : 40|16@1+ (1,0) [0|65535] "" Vector__XXX

BO_TX_BU_ 1300 : FC;
BO_TX_BU_ 532 : FC;
BO_TX_BU_ 533 : FC;
BO_TX_BU_ 535 : FC;
BO_TX_BU_ 888 : GTW;
BO_TX_BU_ 282 : GTW;
BO_TX_BU_ 1384 : GTW;
BO_TX_BU_ 62 : GTW;
BO_TX_BU_ 838 : GTW;
BO_TX_BU_ 904 : GTW;
BO_TX_BU_ 2047 : GTW;
BO_TX_BU_ 792 : GTW;
BO_TX_BU_ 1638 : GTW;
BO_TX_BU_ 1080 : GTW;
BO_TX_BU_ 1376 : GTW;
BO_TX_BU_ 1656 : GTW;
BO_TX_BU_ 2033 : GTW;
BO_TX_BU_ 2026 : GTW;
BO_TX_BU_ 60 : GTW;
BO_TX_BU_ 1370 : GTW;
BO_TX_BU_ 840 : GTW;
BO_TX_BU_ 1005 : GTW;
BO_TX_BU_ 1112 : GTW;
BO_TX_BU_ 1650 : HCML;
BO_TX_BU_ 1980 : HCMR;
CM_ BO_ 1300 "FC ECU message: serial";
CM_ SG_ 1300 FC_serialDataSelect "FC ECU: serial data select";
CM_ SG_ 1300 FC_serialChar01 "FC ECU: serial char01";
CM_ SG_ 1300 FC_serialChar02 "FC ECU: serial char02";
CM_ SG_ 1300 FC_serialChar03 "FC ECU: serial char03";
CM_ SG_ 1300 FC_serialChar04 "FC ECU: serial char04";
CM_ SG_ 1300 FC_serialChar05 "FC ECU: serial char05";
CM_ SG_ 1300 FC_serialChar06 "FC ECU: serial char06";
CM_ SG_ 1300 FC_serialChar07 "FC ECU: serial char07";
CM_ SG_ 1300 FC_serialChar08 "FC ECU: serial char08";
CM_ SG_ 1300 FC_serialChar09 "FC ECU: serial char09";
CM_ SG_ 1300 FC_serialChar10 "FC ECU: serial char10";
CM_ SG_ 1300 FC_serialChar11 "FC ECU: serial char11";
CM_ SG_ 1300 FC_serialChar12 "FC ECU: serial char12";
CM_ SG_ 1300 FC_serialChar13 "FC ECU: serial char13";
CM_ SG_ 1300 FC_serialChar14 "FC ECU: serial char14";
CM_ SG_ 1300 FC_serialChar15 "FC ECU: serial char15";
CM_ SG_ 1300 FC_serialChar16 "FC ECU: serial char16";
CM_ SG_ 1300 FC_serialChar17 "FC ECU: serial char17";
CM_ BO_ 532 "FC ECU message: status";
CM_ SG_ 532 FC_protocolVersion "FC ECU: protocol version";
CM_ SG_ 532 FC_statusCode "Fast charger status code; raw 0 = signal not available (SNA)";
CM_ SG_ 532 FC_deprecated1 "FC ECU: deprecated1";
CM_ SG_ 532 FC_deprecated2 "FC ECU: deprecated2";
CM_ SG_ 532 FC_deprecated3 "FC ECU: deprecated3";
CM_ SG_ 532 FC_adapterLocked "Indicates if the DC adapter is secure or not";
CM_ SG_ 532 FC_minCurrentLimit "Fast charger min current limit";
CM_ SG_ 532 FC_type "Type of EVSE connected that supports digital communication; raw 7 = signal not available (SNA)";
CM_ SG_ 532 FC_dcCurrent "Fast charger DC output current";
CM_ SG_ 532 FC_postID "Fast charger charging post ID; raw 3 = signal not available (SNA)";
CM_ SG_ 532 FC_dcVoltage "Fast charger DC voltage";
CM_ SG_ 532 FC_leakageTestNotSupported "Indicates if the S/X leakage test can be run on this supercharger";
CM_ SG_ 532 FC_dischargeSupported "FC ECU: discharge supported";
CM_ BO_ 533 "FC ECU message: status2";
CM_ SG_ 533 FC_externalIsolationResistance "Fast charger external isolation resistance; raw 255 = signal not available (SNA)";
CM_ BO_ 535 "FC ECU message: status3";
CM_ SG_ 535 FC_status3DataSelect "FC ECU: status3 data select";
CM_ SG_ 535 FC_status3DummySig "FC ECU: status3 dummy sig";
CM_ SG_ 535 FC_class "FC ECU: class; raw 0 = signal not available (SNA)";
CM_ SG_ 535 FC_brand "Fast charger brand; raw 0 = signal not available (SNA)";
CM_ SG_ 535 FC_coolingType "Type of cooling used for the supercharger; raw 0 = signal not available (SNA)";
CM_ SG_ 535 FC_uiStopType "Type of stop type supported from the UI; raw 0 = signal not available (SNA)";
CM_ SG_ 535 FC_emergencyShutdownSupported "Indicates if the supercharger supports fast emergency shutdown requests from vehicle";
CM_ SG_ 535 FC_generation "Hardware generation of the Tesla EVSE; raw 0 = signal not available (SNA)";
CM_ SG_ 535 FC_billingEnergy "Total billable charge energy (integrated by EVSE). Position from firmware; message assignment inferred.";
CM_ BO_ 888 "Gateway message: e call";
CM_ SG_ 888 GTW_GTW_SOS_ECALL_RQST "State of the GTW-SOS-ECALL-RQST pin";
CM_ SG_ 888 GTW_LTE_ECALL_LOCK "State of the LTE-ECALL-LOCK pin";
CM_ BO_ 282 "Gateway message: adc4";
CM_ SG_ 282 GTW_BKP_BATT_MON "Gateway: BKP BATT MON; raw 4095 = signal not available (SNA)";
CM_ SG_ 282 GTW_BKP_BATT_NTC_P "BKP_BATT_NTC_P pni voltage; raw 4095 = signal not available (SNA)";
CM_ SG_ 282 GTW_ECALL_GPS_ANT_BIAS "Gateway: ECALL GPS ANT BIAS; raw 4095 = signal not available (SNA)";
CM_ SG_ 282 GTW_ECALL_MIC_DIAG "ECALL_MIC_DIAG voltage; raw 4095 = signal not available (SNA)";
CM_ SG_ 282 GTW_SOS_ECALL_nRQST_BUF "SOS_ECALL_nRQST_BUF voltage; raw 4095 = signal not available (SNA)";
CM_ BO_ 1384 "Gateway message: alert log";
CM_ SG_ 1384 GTW_alertID "Gateway: alert ID";
CM_ SG_ 1384 GTW_alertState "Gateway: alert state";
CM_ SG_ 1384 GTW_a014_crcVersion "Gateway: a014 crc version";
CM_ SG_ 1384 GTW_a015_crcVersion "Gateway: a015 crc version";
CM_ SG_ 1384 GTW_a016_crcVersion "Gateway: a016 crc version";
CM_ SG_ 1384 GTW_a017_crcVersion "Gateway: a017 crc version";
CM_ SG_ 1384 GTW_a018_crcVersion "Gateway: a018 crc version";
CM_ SG_ 1384 GTW_a019_crcVersion "Gateway: a019 crc version";
CM_ SG_ 1384 GTW_a020_crcVersion "Gateway: a020 crc version";
CM_ SG_ 1384 GTW_a021_crcVersion "Gateway: a021 crc version";
CM_ SG_ 1384 GTW_a022_crcVersion "Gateway: a022 crc version";
CM_ SG_ 1384 GTW_a023_crcVersion "Gateway: a023 crc version";
CM_ SG_ 1384 GTW_a024_crcVersion "Gateway: a024 crc version";
CM_ SG_ 1384 GTW_a025_crcVersion "Gateway: a025 crc version";
CM_ SG_ 1384 GTW_a026_crcVersion "Gateway: a026 crc version";
CM_ SG_ 1384 GTW_a027_crcVersion "Gateway: a027 crc version";
CM_ SG_ 1384 GTW_a028_crcVersion "Gateway: a028 crc version";
CM_ SG_ 1384 GTW_a029_crcVersion "Gateway: a029 crc version";
CM_ SG_ 1384 GTW_a030_crcVersion "Gateway: a030 crc version";
CM_ SG_ 1384 GTW_a031_crcVersion "Gateway: a031 crc version";
CM_ SG_ 1384 GTW_a032_crcVersion "Gateway: a032 crc version";
CM_ SG_ 1384 GTW_a033_crcVersion "Gateway: a033 crc version";
CM_ SG_ 1384 GTW_a034_crcVersion "Gateway: a034 crc version";
CM_ SG_ 1384 GTW_a035_crcVersion "Gateway: a035 crc version";
CM_ SG_ 1384 GTW_a036_crcVersion "Gateway: a036 crc version";
CM_ SG_ 1384 GTW_a037_crcVersion "Gateway: a037 crc version";
CM_ SG_ 1384 GTW_a038_crcVersion "Gateway: a038 crc version";
CM_ SG_ 1384 GTW_a039_crcVersion "Gateway: a039 crc version";
CM_ SG_ 1384 GTW_a040_crcVersion "Gateway: a040 crc version";
CM_ SG_ 1384 GTW_a041_crcVersion "Gateway: a041 crc version";
CM_ SG_ 1384 GTW_a042_crcVersion "Gateway: a042 crc version";
CM_ SG_ 1384 GTW_a043_crcVersion "Gateway: a043 crc version";
CM_ SG_ 1384 GTW_a045_crcVersion "Gateway: a045 crc version";
CM_ SG_ 1384 GTW_a046_crcVersion "Gateway: a046 crc version";
CM_ SG_ 1384 GTW_a047_crcVersion "Gateway: a047 crc version";
CM_ SG_ 1384 GTW_a048_crcVersion "Gateway: a048 crc version";
CM_ SG_ 1384 GTW_a049_headerError "Gateway: a049 header error";
CM_ SG_ 1384 GTW_a054_crcVersion "Gateway: a054 crc version";
CM_ SG_ 1384 GTW_a055_crcVersion "Gateway: a055 crc version";
CM_ SG_ 1384 GTW_a062_bmpWatchdogReason "Gateway: a062 bmp watchdog reason";
CM_ SG_ 1384 GTW_a063_VEH_faultConfinement "Gateway: a063 VEH fault confinement";
CM_ SG_ 1384 GTW_a064_CH_faultConfinement "Gateway: a064 CH fault confinement";
CM_ SG_ 1384 GTW_a065_PARTY_faultConfinement "Gateway: a065 PARTY fault confinement";
CM_ SG_ 1384 GTW_a066_type "Gateway: a066 type";
CM_ SG_ 1384 GTW_a066_exceptionCfgId "Gateway: a066 exception cfg id";
CM_ SG_ 1384 GTW_a066_uptime "Gateway: a066 uptime";
CM_ SG_ 1384 GTW_a066_core "Gateway: a066 core";
CM_ SG_ 1384 GTW_a068_codeKeyMissing "Gateway: a068 code key missing";
CM_ SG_ 1384 GTW_a068_cmdKeyMissing "Gateway: a068 cmd key missing";
CM_ SG_ 1384 GTW_a069_sdIntStatusErrs "Gateway: a069 sd int status errs";
CM_ SG_ 1384 GTW_a069_sdTimeout "Gateway: a069 sd timeout";
CM_ SG_ 1384 GTW_a069_sdCmdErr "Gateway: a069 sd cmd err";
CM_ SG_ 1384 GTW_a069_sdWriteErr "Gateway: a069 sd write err";
CM_ SG_ 1384 GTW_a069_sdReadErr "Gateway: a069 sd read err";
CM_ SG_ 1384 GTW_a069_autoCmd12Err "Gateway: a069 auto cmd12 err";
CM_ SG_ 1384 GTW_a072_updtFailureMask "Gateway: a072 updt failure mask";
CM_ SG_ 1384 GTW_a073_SOCResetRequestor "Gateway: a073 SOC reset requestor";
CM_ SG_ 1384 GTW_a077_bmpPmicErrorType "Gateway: a077 bmp pmic error type";
CM_ SG_ 1384 GTW_a097_crcVersion "Gateway: a097 crc version";
CM_ SG_ 1384 GTW_a098_crcVersion "Gateway: a098 crc version";
CM_ SG_ 1384 GTW_a099_crcVersion "Gateway: a099 crc version";
CM_ SG_ 1384 GTW_a100_crcVersion "Gateway: a100 crc version";
CM_ SG_ 1384 GTW_a101_switchStuck "Gateway: a101 switch stuck";
CM_ SG_ 1384 GTW_a101_ETH_SW_nINT "Gateway: a101 ETH SW n INT";
CM_ SG_ 1384 GTW_a106_crcVersion "Gateway: a106 crc version";
CM_ SG_ 1384 GTW_a107_crcVersion "Gateway: a107 crc version";
CM_ SG_ 1384 GTW_a108_crcVersion "Gateway: a108 crc version";
CM_ SG_ 1384 GTW_a117_MC_RGM_DES "Gateway: a117 MC RGM DES";
CM_ SG_ 1384 GTW_a118_MC_RGM_FES "Gateway: a118 MC RGM FES";
CM_ SG_ 1384 GTW_a122_BDY_faultConfinement "Gateway: a122 BDY fault confinement";
CM_ SG_ 1384 GTW_a129_crcVersion "Gateway: a129 crc version";
CM_ SG_ 1384 GTW_a138_sdLifetimeUsed "Gateway: a138 sd lifetime used";
CM_ SG_ 1384 GTW_a139_crcVersion "Gateway: a139 crc version";
CM_ SG_ 1384 GTW_a150_crcVersion "Gateway: a150 crc version";
CM_ SG_ 1384 GTW_a151_crcVersion "Gateway: a151 crc version";
CM_ SG_ 1384 GTW_a155_crcVersion "Gateway: a155 crc version";
CM_ SG_ 1384 GTW_a164_crcVersion "Gateway: a164 crc version";
CM_ SG_ 1384 GTW_a165_crcVersion "Gateway: a165 crc version";
CM_ SG_ 1384 GTW_a169_TPMS_pressureFL "Gateway: a169 TPMS pressure FL";
CM_ SG_ 1384 GTW_a170_TPMS_pressureFR "Gateway: a170 TPMS pressure FR";
CM_ SG_ 1384 GTW_a171_TPMS_pressureRL "Gateway: a171 TPMS pressure RL";
CM_ SG_ 1384 GTW_a172_TPMS_pressureRR "Gateway: a172 TPMS pressure RR";
CM_ SG_ 1384 GTW_a173_TPMS_pressureFL "Gateway: a173 TPMS pressure FL";
CM_ SG_ 1384 GTW_a174_TPMS_pressureFR "Gateway: a174 TPMS pressure FR";
CM_ SG_ 1384 GTW_a175_TPMS_pressureRL "Gateway: a175 TPMS pressure RL";
CM_ SG_ 1384 GTW_a176_TPMS_pressureRR "Gateway: a176 TPMS pressure RR";
CM_ SG_ 1384 GTW_a219_crcVersion "Gateway: a219 crc version";
CM_ SG_ 1384 GTW_a223_crcVersion "Gateway: a223 crc version";
CM_ SG_ 1384 GTW_a226_crcVersion "Gateway: a226 crc version";
CM_ SG_ 1384 GTW_a227_crcVersion "Gateway: a227 crc version";
CM_ SG_ 1384 GTW_a228_crcVersion "Gateway: a228 crc version";
CM_ SG_ 1384 GTW_a244_crcVersion "Gateway: a244 crc version";
CM_ SG_ 1384 GTW_a245_page0ControlValue "Gateway: a245 page0 control value";
CM_ SG_ 1384 GTW_a245_page1ControlValue "Gateway: a245 page1 control value";
CM_ SG_ 1384 GTW_a261_failureReason "Gateway: a261 failure reason";
CM_ SG_ 1384 GTW_a261_failureData1 "Gateway: a261 failure data1";
CM_ SG_ 1384 GTW_a261_failureData2 "Gateway: a261 failure data2";
CM_ SG_ 1384 GTW_a273_crcVersion "Gateway: a273 crc version";
CM_ SG_ 1384 GTW_a274_crcVersion "Gateway: a274 crc version";
CM_ SG_ 1384 GTW_a277_mitigationFailureReason "Gateway: a277 mitigation failure reason";
CM_ SG_ 1384 GTW_a279_repeatCount "Gateway: a279 repeat count";
CM_ SG_ 1384 GTW_a279_failureReason "Gateway: a279 failure reason";
CM_ SG_ 1384 GTW_a279_failureData1 "Gateway: a279 failure data1";
CM_ SG_ 1384 GTW_a279_failureData2 "Gateway: a279 failure data2";
CM_ SG_ 1384 GTW_a309_crcVersion "Gateway: a309 crc version";
CM_ SG_ 1384 GTW_a317_status "Gateway: a317 status";
CM_ SG_ 1384 GTW_a317_errorCode "Gateway: a317 error code";
CM_ SG_ 1384 GTW_a329_crcVersion "Gateway: a329 crc version";
CM_ SG_ 1384 GTW_a330_crcVersion "Gateway: a330 crc version";
CM_ SG_ 1384 GTW_a331_crcVersion "Gateway: a331 crc version";
CM_ SG_ 1384 GTW_a342_crcVersion "Gateway: a342 crc version";
CM_ SG_ 1384 GTW_a348_crcVersion "Gateway: a348 crc version";
CM_ SG_ 1384 GTW_a349_crcVersion "Gateway: a349 crc version";
CM_ SG_ 1384 GTW_a354_crcVersion "Gateway: a354 crc version";
CM_ SG_ 1384 GTW_a355_crcVersion "Gateway: a355 crc version";
CM_ SG_ 1384 GTW_a358_crcVersion "Gateway: a358 crc version";
CM_ SG_ 1384 GTW_a359_crcVersion "Gateway: a359 crc version";
CM_ SG_ 1384 GTW_a360_crcVersion "Gateway: a360 crc version";
CM_ SG_ 1384 GTW_a361_crcVersion "Gateway: a361 crc version";
CM_ SG_ 1384 GTW_a362_crcVersion "Gateway: a362 crc version";
CM_ SG_ 1384 GTW_a363_crcVersion "Gateway: a363 crc version";
CM_ SG_ 1384 GTW_a364_crcVersion "Gateway: a364 crc version";
CM_ SG_ 1384 GTW_a380_crcVersion "Gateway: a380 crc version";
CM_ SG_ 1384 GTW_a381_crcVersion "Gateway: a381 crc version";
CM_ SG_ 1384 GTW_a382_crcVersion "Gateway: a382 crc version";
CM_ SG_ 1384 GTW_a383_crcVersion "Gateway: a383 crc version";
CM_ SG_ 1384 GTW_a384_crcVersion "Gateway: a384 crc version";
CM_ SG_ 1384 GTW_a385_crcVersion "Gateway: a385 crc version";
CM_ SG_ 1384 GTW_a386_crcVersion "Gateway: a386 crc version";
CM_ SG_ 1384 GTW_a394_crcVersion "Gateway: a394 crc version";
CM_ SG_ 1384 GTW_a401_crcVersion "Gateway: a401 crc version";
CM_ SG_ 1384 GTW_a402_crcVersion "Gateway: a402 crc version";
CM_ SG_ 1384 GTW_a409_RES_CAUSE "Gateway: a409 RES CAUSE";
CM_ SG_ 1384 GTW_a410_RES_CAUSE2 "Gateway: a410 RES CAUSE2";
CM_ SG_ 1384 GTW_a418_crcVersion "Gateway: a418 crc version";
CM_ SG_ 1384 GTW_a427_crcVersion "Gateway: a427 crc version";
CM_ SG_ 1384 GTW_a428_crcVersion "Gateway: a428 crc version";
CM_ SG_ 1384 GTW_a429_crcVersion "Gateway: a429 crc version";
CM_ SG_ 1384 GTW_a439_crcVersion "Gateway: a439 crc version";
CM_ BO_ 62 "Gateway message: alert matrix";
CM_ SG_ 62 GTW_matrixIndex "Gateway: matrix index";
CM_ SG_ 62 GTW_w001_canEthTxQueue "Gateway: w001 can eth tx queue";
CM_ SG_ 62 GTW_w002_taskError "Gateway: w002 task error";
CM_ SG_ 62 GTW_w003_logWriteRecord "Gateway: w003 log write record";
CM_ SG_ 62 GTW_w004_mallocHook "Gateway: w004 malloc hook";
CM_ SG_ 62 GTW_w005_stackOverflowHook "Gateway: w005 stack overflow hook";
CM_ SG_ 62 GTW_w006_ifTxOutputFull "Gateway: w006 if tx output full";
CM_ SG_ 62 GTW_w007_ifRxBufError "Gateway: w007 if rx buf error";
CM_ SG_ 62 GTW_w008_ifPbufAllocError "Gateway: w008 if pbuf alloc error";
CM_ SG_ 62 GTW_w009_lateTask "Gateway: w009 late task";
CM_ SG_ 62 GTW_w010_wdTaskCount "Gateway: w010 wd task count";
CM_ SG_ 62 GTW_w011_cancoreWatchdog "Gateway: w011 cancore watchdog";
CM_ SG_ 62 GTW_w012_maincoreWatchdog "Gateway: w012 maincore watchdog";
CM_ SG_ 62 GTW_w014_APSversionMismatch "Gateway: w014 AP sversion mismatch";
CM_ SG_ 62 GTW_w015_DIFversionMismatch "Gateway: w015 DI fversion mismatch";
CM_ SG_ 62 GTW_w016_BLEEPCENTERversionMisma "Gateway: w016 BLEEPCENTE rversion mismatch";
CM_ SG_ 62 GTW_w017_BMSversionMismatch "Gateway: w017 BM sversion mismatch";
CM_ SG_ 62 GTW_w018_CMPversionMismatch "Gateway: w018 CM pversion mismatch";
CM_ SG_ 62 GTW_w019_CPversionMismatch "Gateway: w019 c pversion mismatch";
CM_ SG_ 62 GTW_w020_DIRversionMismatch "Gateway: w020 DI rversion mismatch";
CM_ SG_ 62 GTW_w021_EPAS3PversionMismatch "Gateway: w021 EPAS3 pversion mismatch";
CM_ SG_ 62 GTW_w022_EPBLversionMismatch "Gateway: w022 EPB lversion mismatch";
CM_ SG_ 62 GTW_w023_EPBRversionMismatch "Gateway: w023 EPB rversion mismatch";
CM_ SG_ 62 GTW_w024_ESPversionMismatch "Gateway: w024 ES pversion mismatch";
CM_ SG_ 62 GTW_w025_ESPCALversionMismatch "Gateway: w025 ESPCA lversion mismatch";
CM_ SG_ 62 GTW_w026_GTWversionMismatch "Gateway: w026 GT wversion mismatch";
CM_ SG_ 62 GTW_w027_HVPversionMismatch "Gateway: w027 HV pversion mismatch";
CM_ SG_ 62 GTW_w028_IBSTversionMismatch "Gateway: w028 IBS tversion mismatch";
CM_ SG_ 62 GTW_w029_IBSTCALversionMismatch "Gateway: w029 IBSTCA lversion mismatch";
CM_ SG_ 62 GTW_w030_OCS1PversionMismatch "Gateway: w030 OCS1 pversion mismatch";
CM_ SG_ 62 GTW_w031_PARKversionMismatch "Gateway: w031 PAR kversion mismatch";
CM_ SG_ 62 GTW_w032_PCSversionMismatch "Gateway: w032 PC sversion mismatch";
CM_ SG_ 62 GTW_w033_PCSCPU2versionMismatch "Gateway: w033 pcscpu2version mismatch";
CM_ SG_ 62 GTW_w034_PMRversionMismatch "Gateway: w034 PM rversion mismatch";
CM_ SG_ 62 GTW_w035_PMFversionMismatch "Gateway: w035 PM fversion mismatch";
CM_ SG_ 62 GTW_w036_PTCversionMismatch "Gateway: w036 PT cversion mismatch";
CM_ SG_ 62 GTW_w037_RADCversionMismatch "Gateway: w037 RAD cversion mismatch";
CM_ SG_ 62 GTW_w038_RCMversionMismatch "Gateway: w038 RC mversion mismatch";
CM_ SG_ 62 GTW_w039_RCMCALversionMismatch "Gateway: w039 RCMCA lversion mismatch";
CM_ SG_ 62 GTW_w040_SCCMversionMismatch "Gateway: w040 SCC mversion mismatch";
CM_ SG_ 62 GTW_w041_VCSECversionMismatch "Gateway: w041 VCSE cversion mismatch";
CM_ SG_ 62 GTW_w042_TASversionMismatch "Gateway: w042 TA sversion mismatch";
CM_ SG_ 62 GTW_w043_THSversionMismatch "Gateway: w043 TH sversion mismatch";
CM_ SG_ 62 GTW_w045_VCFRONTversionMismatch "Gateway: w045 VCFRON tversion mismatch";
CM_ SG_ 62 GTW_w046_VCLEFTversionMismatch "Gateway: w046 VCLEF tversion mismatch";
CM_ SG_ 62 GTW_w047_VCRIGHTversionMismatch "Gateway: w047 VCRIGH tversion mismatch";
CM_ SG_ 62 GTW_w048_EPAS3SversionMismatch "Gateway: w048 EPAS3 sversion mismatch";
CM_ SG_ 62 GTW_w049_corruptedManifest "Gateway: w049 corrupted manifest";
CM_ SG_ 62 GTW_w050_sdCardInitFailure "Gateway: w050 sd card init failure";
CM_ SG_ 62 GTW_w051_sdCardFileSystemFailure "Gateway: w051 sd card file system failure";
CM_ SG_ 62 GTW_w052_ifTxSpans "Gateway: w052 if tx spans";
CM_ SG_ 62 GTW_w053_busSleepFailure "Gateway: w053 bus sleep failure";
CM_ SG_ 62 GTW_w054_OPCRversionMismatch "Gateway: w054 OPC rversion mismatch";
CM_ SG_ 62 GTW_w055_OPCFversionMismatch "Gateway: w055 OPC fversion mismatch";
CM_ SG_ 62 GTW_w057_i2cFailure "Gateway: w057 i2c failure";
CM_ SG_ 62 GTW_w058_rtcAlarmFailure "Gateway: w058 rtc alarm failure";
CM_ SG_ 62 GTW_w059_inFactoryMode "Gateway: w059 in factory mode";
CM_ SG_ 62 GTW_w060_unFused "Gateway: w060 un fused";
CM_ SG_ 62 GTW_w061_bmpSleepFailure "Gateway: w061 bmp sleep failure";
CM_ SG_ 62 GTW_w062_bmpWatchdog "Gateway: w062 bmp watchdog";
CM_ SG_ 62 GTW_w063_VEH_canFault "Gateway: w063 VEH can fault";
CM_ SG_ 62 GTW_w064_CH_canFault "Gateway: w064 CH can fault";
CM_ SG_ 62 GTW_w065_PARTY_canFault "Gateway: w065 PARTY can fault";
CM_ SG_ 62 GTW_w066_exception "Gateway: w066 exception";
CM_ SG_ 62 GTW_w067_tcpDebug "Gateway: w067 tcp debug";
CM_ SG_ 62 GTW_w068_prodKeyMissing "Gateway: w068 prod key missing";
CM_ SG_ 62 GTW_w069_diskioErr "Gateway: w069 diskio err";
CM_ SG_ 62 GTW_w070_hrlDump "Gateway: w070 hrl dump";
CM_ SG_ 62 GTW_w071_hrlTrigger "Gateway: w071 hrl trigger";
CM_ SG_ 62 GTW_w072_updateFailure "Gateway: w072 update failure";
CM_ SG_ 62 GTW_w073_steeringWheelReset "Gateway: w073 steering wheel reset";
CM_ SG_ 62 GTW_w074_epas3pMIA "Gateway: w074 epas3p MIA";
CM_ SG_ 62 GTW_w075_epas3sMIA "Gateway: w075 epas3s MIA";
CM_ SG_ 62 GTW_w076_ethInterfaceReset "Gateway: w076 eth interface reset";
CM_ SG_ 62 GTW_w077_bmpPmicError "Gateway: w077 bmp pmic error";
CM_ SG_ 62 GTW_w078_VEHbusOverloaded "Gateway: w078 VE hbus overloaded";
CM_ SG_ 62 GTW_w079_PARTYbusOverloaded "Gateway: w079 PART ybus overloaded";
CM_ SG_ 62 GTW_w080_CHbusOverloaded "Gateway: w080 c hbus overloaded";
CM_ SG_ 62 GTW_w081_udsMessageRejected "Gateway: w081 uds message rejected";
CM_ SG_ 62 GTW_w082_sdCardBSCorrupted "Gateway: w082 sd card BS corrupted";
CM_ SG_ 62 GTW_w083_udsMsgDroppedByTcpStack "Gateway: w083 uds msg dropped by tcp stack";
CM_ SG_ 62 GTW_w084_canFrameDropped "Gateway: w084 can frame dropped";
CM_ SG_ 62 GTW_w085_fuseStateUnknown "Gateway: w085 fuse state unknown";
CM_ SG_ 62 GTW_w086_ocu "Gateway: w086 ocu";
CM_ SG_ 62 GTW_w087_ocuInProgress "Gateway: w087 ocu in progress";
CM_ SG_ 62 GTW_w088_sdCardInvReqParallel "Gateway: w088 sd card inv req parallel";
CM_ SG_ 62 GTW_w089_sdCardWatchdog "Gateway: w089 sd card watchdog";
CM_ SG_ 62 GTW_w090_ocuFailed "Gateway: w090 ocu failed";
CM_ SG_ 62 GTW_w091_lowStack "Gateway: w091 low stack";
CM_ SG_ 62 GTW_w092_sdCardInvReqZero "Gateway: w092 sd card inv req zero";
CM_ SG_ 62 GTW_w093_sdCardInvReqOverflowBas "Gateway: w093 sd card inv req overflow base";
CM_ SG_ 62 GTW_w094_sdCardInvReqOverflowCou "Gateway: w094 sd card inv req overflow count";
CM_ SG_ 62 GTW_w095_sdCardFull "Gateway: w095 sd card full";
CM_ SG_ 62 GTW_w096_sdCardFatCorrupted "Gateway: w096 sd card fat corrupted";
CM_ SG_ 62 GTW_w097_HCMLversionMismatch "Gateway: w097 HCM lversion mismatch";
CM_ SG_ 62 GTW_w098_HCMRversionMismatch "Gateway: w098 HCM rversion mismatch";
CM_ SG_ 62 GTW_w099_SWCversionMismatch "Gateway: w099 SW cversion mismatch";
CM_ SG_ 62 GTW_w100_CBCversionMismatch "Gateway: w100 CB cversion mismatch";
CM_ SG_ 62 GTW_w101_switchWatchdog "Gateway: w101 switch watchdog";
CM_ SG_ 62 GTW_w103_sdCardFormatted "Gateway: w103 sd card formatted";
CM_ SG_ 62 GTW_w104_sdCardDriverArgCorrupte "Gateway: w104 sd card driver arg corrupted";
CM_ SG_ 62 GTW_w105_eBuckConfigured "Gateway: w105 e buck configured";
CM_ SG_ 62 GTW_w106_BLEEPLEFTversionMismatc "Gateway: w106 BLEEPLEF tversion mismatch";
CM_ SG_ 62 GTW_w107_BLEEPRIGHTversionMismat "Gateway: w107 BLEEPRIGH tversion mismatch";
CM_ SG_ 62 GTW_w108_BLEEPREARversionMismatc "Gateway: w108 BLEEPREA rversion mismatch";
CM_ SG_ 62 GTW_w109_failedToStartUpdater "Gateway: w109 failed to start updater";
CM_ SG_ 62 GTW_w110_readMdioFailed "Gateway: w110 read mdio failed";
CM_ SG_ 62 GTW_w111_writeMdioFailed "Gateway: w111 write mdio failed";
CM_ SG_ 62 GTW_w112_z4bDisabled "Gateway: w112 z4b disabled";
CM_ SG_ 62 GTW_w113_unrecognizedCanMessage "Gateway: w113 unrecognized can message";
CM_ SG_ 62 GTW_w114_updtRetried "Gateway: w114 updt retried";
CM_ SG_ 62 GTW_w115_hrlEventFileAvail "Gateway: w115 hrl event file avail";
CM_ SG_ 62 GTW_w116_switchInitFailed "Gateway: w116 switch init failed";
CM_ SG_ 62 GTW_w117_unexpectedDestructiveRe "Gateway: w117 unexpected destructive reset status";
CM_ SG_ 62 GTW_w118_unexpectedFunctionalRes "Gateway: w118 unexpected functional reset status";
CM_ SG_ 62 GTW_w120_switchUnlocked "Gateway: w120 switch unlocked";
CM_ SG_ 62 GTW_w122_BDY_canFault "Gateway: w122 BDY can fault";
CM_ SG_ 62 GTW_w123_BDYbusOverloaded "Gateway: w123 BD ybus overloaded";
CM_ SG_ 62 GTW_w125_switchReplayUnlocked "Gateway: w125 switch replay unlocked";
CM_ SG_ 62 GTW_w127_noFilePointersAvailable "Gateway: w127 no file pointers available";
CM_ SG_ 62 GTW_w129_ICRversionMismatch "Gateway: w129 IC rversion mismatch";
CM_ SG_ 62 GTW_w133_adspFaultDetected "Gateway: w133 adsp fault detected";
CM_ SG_ 62 GTW_w134_disableFeatureFailed "Gateway: w134 disable feature failed";
CM_ SG_ 62 GTW_w135_canLogQueueFull "Gateway: w135 can log queue full";
CM_ SG_ 62 GTW_w136_hrlGameModeFileAvail "Gateway: w136 hrl game mode file avail";
CM_ SG_ 62 GTW_w137_lowHeap "Gateway: w137 low heap";
CM_ SG_ 62 GTW_w138_sdCardEndOfLife "Gateway: w138 sd card end of life";
CM_ SG_ 62 GTW_w139_CMPDversionMismatch "Gateway: w139 CMP dversion mismatch";
CM_ SG_ 62 GTW_w140_cancoreHeartbeat "Gateway: w140 cancore heartbeat";
CM_ SG_ 62 GTW_w141_teleCANETHis "Gateway: w141 tele CANET his";
CM_ SG_ 62 GTW_w143_possibleCanWakeIssue "Gateway: w143 possible can wake issue";
CM_ SG_ 62 GTW_w144_hrlStateMachine "Gateway: w144 hrl state machine";
CM_ SG_ 62 GTW_w145_carConfigsNotWritten "Gateway: w145 car configs not written";
CM_ SG_ 62 GTW_w146_performancePackageMisma "Gateway: w146 performance package mismatch";
CM_ SG_ 62 GTW_w147_updateAbortFor12v "Gateway: w147 update abort for12v";
CM_ SG_ 62 GTW_w149_rtcTimeSetInPast "Gateway: w149 rtc time set in past";
CM_ SG_ 62 GTW_w150_HCM3LversionMismatch "Gateway: w150 HCM3 lversion mismatch";
CM_ SG_ 62 GTW_w151_HCM3RversionMismatch "Gateway: w151 HCM3 rversion mismatch";
CM_ SG_ 62 GTW_w153_externalRtcAlarmFailure "Gateway: w153 external rtc alarm failure";
CM_ SG_ 62 GTW_w155_PMversionMismatch "Gateway: w155 p mversion mismatch";
CM_ SG_ 62 GTW_w164_VCBATTversionMismatch "Gateway: w164 VCBAT tversion mismatch";
CM_ SG_ 62 GTW_w165_USMversionMismatch "Gateway: w165 US mversion mismatch";
CM_ SG_ 62 GTW_w166_nErrCanFaultVeh "Gateway: w166 n err can fault veh";
CM_ SG_ 62 GTW_w167_nErrCanFaultCh "Gateway: w167 n err can fault ch";
CM_ SG_ 62 GTW_w168_nErrCanFaultParty "Gateway: w168 n err can fault party";
CM_ SG_ 62 GTW_w169_TPMSsoftWarnFrontLeft "Gateway: w169 TPM ssoft warn front left";
CM_ SG_ 62 GTW_w170_TPMSsoftWarnFrontRight "Gateway: w170 TPM ssoft warn front right";
CM_ SG_ 62 GTW_w171_TPMSsoftWarnRearLeft "Gateway: w171 TPM ssoft warn rear left";
CM_ SG_ 62 GTW_w172_TPMSsoftWarnRearRight "Gateway: w172 TPM ssoft warn rear right";
CM_ SG_ 62 GTW_w173_TPMShardWarnFrontLeft "Gateway: w173 TPM shard warn front left";
CM_ SG_ 62 GTW_w174_TPMShardWarnFrontRight "Gateway: w174 TPM shard warn front right";
CM_ SG_ 62 GTW_w175_TPMShardWarnRearLeft "Gateway: w175 TPM shard warn rear left";
CM_ SG_ 62 GTW_w176_TPMShardWarnRearRight "Gateway: w176 TPM shard warn rear right";
CM_ SG_ 62 GTW_w186_swrPrecaution "Gateway: w186 swr precaution";
CM_ SG_ 62 GTW_w218_switchOTPIncorrect "Gateway: w218 switch OTP incorrect";
CM_ SG_ 62 GTW_w219_CMPSversionMismatch "Gateway: w219 CMP sversion mismatch";
CM_ SG_ 62 GTW_w223_LVBMSversionMismatch "Gateway: w223 LVBM sversion mismatch";
CM_ SG_ 62 GTW_w224_sdCardUpgradeNeeded "Gateway: w224 sd card upgrade needed";
CM_ SG_ 62 GTW_w225_resetOnSleepWake "Gateway: w225 reset on sleep wake";
CM_ SG_ 62 GTW_w226_DISPversionMismatch "Gateway: w226 DIS pversion mismatch";
CM_ SG_ 62 GTW_w227_DISPTOUCHversionMismatc "Gateway: w227 DISPTOUC hversion mismatch";
CM_ SG_ 62 GTW_w228_DISPOSDversionMismatch "Gateway: w228 DISPOS dversion mismatch";
CM_ SG_ 62 GTW_w229_displaySoftsetConnectio "Gateway: w229 display softset connection";
CM_ SG_ 62 GTW_w230_touchInterruptStorm "Gateway: w230 touch interrupt storm";
CM_ SG_ 62 GTW_w244_SDCRversionMismatch "Gateway: w244 SDC rversion mismatch";
CM_ SG_ 62 GTW_w245_apsNotDisabled "Gateway: w245 aps not disabled";
CM_ SG_ 62 GTW_w246_touchcoreHeartbeat "Gateway: w246 touchcore heartbeat";
CM_ SG_ 62 GTW_w255_rtc32KHzWatchdog "Gateway: w255 rtc32 k hz watchdog";
CM_ SG_ 62 GTW_w260_unknownPN "Gateway: w260 unknown PN";
CM_ SG_ 62 GTW_w261_adspWatchdog "Gateway: w261 adsp watchdog";
CM_ SG_ 62 GTW_w262_canLogBlockDropped "Gateway: w262 can log block dropped";
CM_ SG_ 62 GTW_w263_hrlUdpFileAvail "Gateway: w263 hrl udp file avail";
CM_ SG_ 62 GTW_w264_hrlPseudoFileAvail "Gateway: w264 hrl pseudo file avail";
CM_ SG_ 62 GTW_w265_optionFlagsError "Gateway: w265 option flags error";
CM_ SG_ 62 GTW_w266_dpp1MIA "Gateway: w266 dpp1 MIA";
CM_ SG_ 62 GTW_w267_dpp2MIA "Gateway: w267 dpp2 MIA";
CM_ SG_ 62 GTW_w268_stoMIA "Gateway: w268 sto MIA";
CM_ SG_ 62 GTW_w273_BLEEPREARLEFTversionMis "Gateway: w273 BLEEPREARLEF tversion mismatch";
CM_ SG_ 62 GTW_w274_BLEEPREARRIGHTversionMi "Gateway: w274 BLEEPREARRIGH tversion mismatch";
CM_ SG_ 62 GTW_w275_VDDCORE_DrMOS_Fault "Gateway: w275 VDDCORE dr MOS fault";
CM_ SG_ 62 GTW_w276_VDDSOC_DrMOS_Fault "Gateway: w276 VDDSOC dr MOS fault";
CM_ SG_ 62 GTW_w277_NonRevCDrMOSMitigationF "Gateway: w277 non rev c dr MOS mitigation failed";
CM_ SG_ 62 GTW_w278_ethSwitchCongested "Gateway: w278 eth switch congested";
CM_ SG_ 62 GTW_w279_adspRepeatedWatchdog "Gateway: w279 adsp repeated watchdog";
CM_ SG_ 62 GTW_w280_hrlFrameDropped "Gateway: w280 hrl frame dropped";
CM_ SG_ 62 GTW_w281_likelyMissedPoke "Gateway: w281 likely missed poke";
CM_ SG_ 62 GTW_w282_tcuPhyConfigurationFail "Gateway: w282 tcu phy configuration failed";
CM_ SG_ 62 GTW_w309_VCUSBversionMismatch "Gateway: w309 VCUS bversion mismatch";
CM_ SG_ 62 GTW_w311_canLogQueueFullBeforeFs "Gateway: w311 can log queue full before fs init";
CM_ SG_ 62 GTW_w312_hrlFileIncomplete "Gateway: w312 hrl file incomplete";
CM_ SG_ 62 GTW_w313_OSDActive "Gateway: w313 OSD active";
CM_ SG_ 62 GTW_w314_canLogBlockWriteErr "Gateway: w314 can log block write err";
CM_ SG_ 62 GTW_w316_sdCardChkdskRepair "Gateway: w316 sd card chkdsk repair";
CM_ SG_ 62 GTW_w317_sdCardChkdskRepairFaile "Gateway: w317 sd card chkdsk repair failed";
CM_ SG_ 62 GTW_w322_gestureUnrecognizedFrom "Gateway: w322 gesture unrecognized from moving";
CM_ SG_ 62 GTW_w323_gestureStartOutOfStrip "Gateway: w323 gesture start out of strip";
CM_ SG_ 62 GTW_w328_smartShiftDisabled "Gateway: w328 smart shift disabled";
CM_ SG_ 62 GTW_w329_FOHMversionMismatch "Gateway: w329 FOH mversion mismatch";
CM_ SG_ 62 GTW_w330_SWSLversionMismatch "Gateway: w330 SWS lversion mismatch";
CM_ SG_ 62 GTW_w331_SWSRversionMismatch "Gateway: w331 SWS rversion mismatch";
CM_ SG_ 62 GTW_w332_unknownDisplayPN "Gateway: w332 unknown display PN";
CM_ SG_ 62 GTW_w334_hrlFolderSpaceLow "Gateway: w334 hrl folder space low";
CM_ SG_ 62 GTW_w336_possibleCanTxIssue "Gateway: w336 possible can tx issue";
CM_ SG_ 62 GTW_w342_VCBLDCPPversionMismatch "Gateway: w342 VCBLDCP pversion mismatch";
CM_ SG_ 62 GTW_w348_VCBLDCFversionMismatch "Gateway: w348 VCBLDC fversion mismatch";
CM_ SG_ 62 GTW_w349_VCBLDCPBversionMismatch "Gateway: w349 VCBLDCP bversion mismatch";
CM_ SG_ 62 GTW_w350_mOSDCrcCheck "Gateway: w350 m OSD crc check";
CM_ SG_ 62 GTW_w351_sOSDCrcCheck "Gateway: w351 s OSD crc check";
CM_ SG_ 62 GTW_w352_mASILStatusCheck "Gateway: w352 m ASIL status check";
CM_ SG_ 62 GTW_w353_sASILStatusCheck "Gateway: w353 s ASIL status check";
CM_ SG_ 62 GTW_w354_EPASTPversionMismatch "Gateway: w354 EPAST pversion mismatch";
CM_ SG_ 62 GTW_w355_EPASTSversionMismatch "Gateway: w355 EPAST sversion mismatch";
CM_ SG_ 62 GTW_w356_touchGPIOStatusCheck "Gateway: w356 touch GPIO status check";
CM_ SG_ 62 GTW_w358_RGBIPFLversionMismatch "Gateway: w358 RGBIPF lversion mismatch";
CM_ SG_ 62 GTW_w359_RGBIPFRversionMismatch "Gateway: w359 RGBIPF rversion mismatch";
CM_ SG_ 62 GTW_w360_RGBDOORFLversionMismatc "Gateway: w360 RGBDOORF lversion mismatch";
CM_ SG_ 62 GTW_w361_RGBDOORRLversionMismatc "Gateway: w361 RGBDOORR lversion mismatch";
CM_ SG_ 62 GTW_w362_RGBDOORFRversionMismatc "Gateway: w362 RGBDOORF rversion mismatch";
CM_ SG_ 62 GTW_w363_RGBDOORRRversionMismatc "Gateway: w363 RGBDOORR rversion mismatch";
CM_ SG_ 62 GTW_w364_BLEEPCRADLEversionMisma "Gateway: w364 BLEEPCRADL eversion mismatch";
CM_ SG_ 62 GTW_w366_uiGearRequestMismatch "Gateway: w366 ui gear request mismatch";
CM_ SG_ 62 GTW_w376_blFailedToExecBootImg "Gateway: w376 bl failed to exec boot img";
CM_ SG_ 62 GTW_w380_DPBversionMismatch "Gateway: w380 DP bversion mismatch";
CM_ SG_ 62 GTW_w381_DPBCALversionMismatch "Gateway: w381 DPBCA lversion mismatch";
CM_ SG_ 62 GTW_w382_IDBversionMismatch "Gateway: w382 ID bversion mismatch";
CM_ SG_ 62 GTW_w383_IDB1versionMismatch "Gateway: w383 idb1version mismatch";
CM_ SG_ 62 GTW_w384_IDBCALversionMismatch "Gateway: w384 IDBCA lversion mismatch";
CM_ SG_ 62 GTW_w385_RCUversionMismatch "Gateway: w385 RC uversion mismatch";
CM_ SG_ 62 GTW_w386_RCUCALversionMismatch "Gateway: w386 RCUCA lversion mismatch";
CM_ SG_ 62 GTW_w387_externalRtcReadFailure "Gateway: w387 external rtc read failure";
CM_ SG_ 62 GTW_w388_adspWatchdogSkipped "Gateway: w388 adsp watchdog skipped";
CM_ SG_ 62 GTW_w389_rcmEventDetected "Gateway: w389 rcm event detected";
CM_ SG_ 62 GTW_w390_displayFwQueryFailed "Gateway: w390 display fw query failed";
CM_ SG_ 62 GTW_w391_adspMacAddrCheckFailed "Gateway: w391 adsp mac addr check failed";
CM_ SG_ 62 GTW_w393_osdSramCrcMismatch "Gateway: w393 osd sram crc mismatch";
CM_ SG_ 62 GTW_w394_WIPERversionMismatch "Gateway: w394 WIPE rversion mismatch";
CM_ SG_ 62 GTW_w395_lwipIcmpError "Gateway: w395 lwip icmp error";
CM_ SG_ 62 GTW_w396_alreadyInReverse "Gateway: w396 already in reverse";
CM_ SG_ 62 GTW_w397_alreadyInDrive "Gateway: w397 already in drive";
CM_ SG_ 62 GTW_w398_awakeForExtendedTime "Gateway: w398 awake for extended time";
CM_ SG_ 62 GTW_w399_ethIfRxTcpipQueueDrop "Gateway: w399 eth if rx tcpip queue drop";
CM_ SG_ 62 GTW_w400_ethlSwitchOTPIncorrect "Gateway: w400 ethl switch OTP incorrect";
CM_ SG_ 62 GTW_w401_VCSEAT2LversionMismatch "Gateway: w401 VCSEAT2 lversion mismatch";
CM_ SG_ 62 GTW_w402_VCSEAT2RversionMismatch "Gateway: w402 VCSEAT2 rversion mismatch";
CM_ SG_ 62 GTW_w409_unexpectedResetCause "Gateway: w409 unexpected reset cause";
CM_ SG_ 62 GTW_w410_unexpectedResetCause2 "Gateway: w410 unexpected reset cause2";
CM_ SG_ 62 GTW_w411_tASILStatusCheck "Gateway: w411 t ASIL status check";
CM_ SG_ 62 GTW_w414_socHeldInReset "Gateway: w414 soc held in reset";
CM_ SG_ 62 GTW_w418_TRCMversionMismatch "Gateway: w418 TRC mversion mismatch";
CM_ SG_ 62 GTW_w420_unexpectedCanMessageLen "Gateway: w420 unexpected can message length";
CM_ SG_ 62 GTW_w421_ModemEthLinkDown "Gateway: w421 modem eth link down";
CM_ SG_ 62 GTW_w422_ethSwitchSevereCongesti "Gateway: w422 eth switch severe congestion watchdog";
CM_ SG_ 62 GTW_w427_DISPBRIDGEversionMismat "Gateway: w427 DISPBRIDG eversion mismatch";
CM_ SG_ 62 GTW_w428_LUMBAR32LversionMismatc "Gateway: w428 LUMBAR32 lversion mismatch";
CM_ SG_ 62 GTW_w429_LUMBAR32RversionMismatc "Gateway: w429 LUMBAR32 rversion mismatch";
CM_ SG_ 62 GTW_w436_possibleCanRxIssue "Gateway: w436 possible can rx issue";
CM_ SG_ 62 GTW_w437_softFlowControlNotRunni "Gateway: w437 soft flow control not running";
CM_ SG_ 62 GTW_w438_wakeSourceUnknown "Gateway: w438 wake source unknown";
CM_ SG_ 62 GTW_w439_VCCCversionMismatch "Gateway: w439 VCC cversion mismatch";
CM_ SG_ 62 GTW_w450_unexpectedAutopilotCont "Gateway: w450 unexpected autopilot control can message";
CM_ SG_ 62 GTW_w451_diagCanBufferExhausted "Gateway: w451 diag can buffer exhausted";
CM_ SG_ 62 GTW_w452_diagCanStaleSocket "Gateway: w452 diag can stale socket";
CM_ SG_ 62 GTW_w453_diagCanFdSetDesync "Gateway: w453 diag can fd set desync";
CM_ SG_ 62 GTW_w454_diagCanFrameOverread "Gateway: w454 diag can frame overread";
CM_ SG_ 62 GTW_w455_hrlDumpPageOwnershipErr "Gateway: w455 hrl dump page ownership error";
CM_ SG_ 62 GTW_w456_hrlStateMachinePageOwne "Gateway: w456 hrl state machine page ownership error";
CM_ SG_ 62 GTW_w463_displayEdidReadFailed "Gateway: w463 display edid read failed";
CM_ SG_ 62 GTW_w469_backlightFsmUnhealthy "Gateway: w469 backlight fsm unhealthy";
CM_ BO_ 838 "Gateway message: autopilot override";
CM_ SG_ 838 GTW_autopilotOverrideState "Signals whether an autopilot trial or subscription is active";
CM_ SG_ 838 GTW_autopilotConfig "Current level of permanent Autopilot firmware";
CM_ SG_ 838 GTW_autopilotOverrideConfig "Current level of trial or subscription Autopilot firmware";
CM_ SG_ 838 GTW_autopilotConfigSource "Source of Autopilot configuration broadcast by Gateway";
CM_ SG_ 838 GTW_autopilotOverrideExpireTime "Expiration time for the currently active autopilot trial or subscription";
CM_ BO_ 904 "Gateway message: can status";
CM_ SG_ 904 GTW_VEH_canBusActivity "Active if any frame detected on the bus";
CM_ SG_ 904 GTW_PARTY_canBusActivity "Active if any frame detected on the bus";
CM_ SG_ 904 GTW_CH_canBusActivity "Active if any frame detected on the bus";
CM_ SG_ 904 GTW_VEH_txWarning "Gateway: VEH tx warning";
CM_ SG_ 904 GTW_PARTY_txWarning "Gateway: PARTY tx warning";
CM_ SG_ 904 GTW_CH_txWarning "Gateway: CH tx warning";
CM_ SG_ 904 GTW_VEH_rxWarning "Gateway: VEH rx warning";
CM_ SG_ 904 GTW_PARTY_rxWarning "Gateway: PARTY rx warning";
CM_ SG_ 904 GTW_CH_rxWarning "Gateway: CH rx warning";
CM_ SG_ 904 GTW_VEH_faultConfinement "Fault confinement as per CAN spec";
CM_ SG_ 904 GTW_PARTY_faultConfinement "Fault confinement as per CAN spec";
CM_ SG_ 904 GTW_CH_faultConfinement "Fault confinement as per CAN spec";
CM_ SG_ 904 GTW_BDY_canBusActivity "Active if any frame detected on the bus";
CM_ SG_ 904 GTW_BDY_txWarning "Gateway: BDY tx warning";
CM_ SG_ 904 GTW_BDY_rxWarning "Gateway: BDY rx warning";
CM_ SG_ 904 GTW_BDY_faultConfinement "Fault confinement as per CAN spec";
CM_ BO_ 2047 "Gateway message: car config";
CM_ SG_ 2047 GTW_carConfigMultiplexer "Gateway: car config multiplexer";
CM_ SG_ 2047 GTW_deliveryStatus "Indicates whether the vehicle has been marked delivered to the customer in Tesla backend systems.";
CM_ SG_ 2047 GTW_cabinPTCHeaterType "Gateway: cabin PTC heater type";
CM_ SG_ 2047 GTW_rightHandDrive "Gateway: right hand drive";
CM_ SG_ 2047 GTW_rearLightType "Gateway: rear light type";
CM_ SG_ 2047 GTW_headlamps "Gateway: headlamps";
CM_ SG_ 2047 GTW_country "Gateway: country";
CM_ SG_ 2047 GTW_tireType "Gateway: tire type";
CM_ SG_ 2047 GTW_dasHw "Indicates the Driver Assistance System (DAS) hardware installed.";
CM_ SG_ 2047 GTW_brakeHWType "Gateway: brake HW type";
CM_ SG_ 2047 GTW_restraintsHardwareType "Gateway: restraints hardware type";
CM_ SG_ 2047 GTW_drivetrainType "Gateway: drivetrain type";
CM_ SG_ 2047 GTW_radarHeaterType "Gateway: radar heater type";
CM_ SG_ 2047 GTW_exteriorTrimType "Gateway: exterior trim type";
CM_ SG_ 2047 GTW_frontSeatHeaters "Gateway: front seat heaters";
CM_ SG_ 2047 GTW_rearSeatHeaters "Gateway: rear seat heaters";
CM_ SG_ 2047 GTW_eCallAntennaHW "Gateway: e call antenna HW";
CM_ SG_ 2047 GTW_homelinkType "Gateway: homelink type";
CM_ SG_ 2047 GTW_vdcType "Gateway: vdc type";
CM_ SG_ 2047 GTW_memoryMirrors "Gateway: memory mirrors";
CM_ SG_ 2047 GTW_powerLiftgateType "Gateway: power liftgate type";
CM_ SG_ 2047 GTW_lumbarECUType "Gateway: lumbar ECU type";
CM_ SG_ 2047 GTW_rearSeatHeaterType "Gateway: rear seat heater type";
CM_ SG_ 2047 GTW_auxParkLamps "Gateway: aux park lamps";
CM_ SG_ 2047 GTW_interiorCabinRadarType "Gateway: interior cabin radar type";
CM_ SG_ 2047 GTW_hvacPanelVaneType "Gateway: hvac panel vane type";
CM_ SG_ 2047 GTW_intakeAirFilterType "Gateway: intake air filter type";
CM_ SG_ 2047 GTW_eBuckConfig "Gateway: e buck config";
CM_ SG_ 2047 GTW_steeringHeaterEnabled "Gateway: steering heater enabled";
CM_ SG_ 2047 GTW_activeHighBeam "Gateway: active high beam";
CM_ SG_ 2047 GTW_airbagCutoffSwitch "Gateway: airbag cutoff switch";
CM_ SG_ 2047 GTW_intrusionSensorType "Gateway: intrusion sensor type";
CM_ SG_ 2047 GTW_spoilerType "Gateway: spoiler type";
CM_ SG_ 2047 GTW_backupCameraType "Gateway: backup camera type";
CM_ SG_ 2047 GTW_rearFogLamps "Gateway: rear fog lamps";
CM_ SG_ 2047 GTW_roofType "Gateway: roof type";
CM_ SG_ 2047 GTW_thirdRowSeatType "Gateway: third row seat type";
CM_ SG_ 2047 GTW_autopilot "Gateway: autopilot";
CM_ SG_ 2047 GTW_superchargingAccess "Gateway: supercharging access";
CM_ SG_ 2047 GTW_exteriorColor "Gateway: exterior color";
CM_ SG_ 2047 GTW_pedestrianWarningSound "Gateway: pedestrian warning sound";
CM_ SG_ 2047 GTW_steeringColumnUJointType "Gateway: steering column u joint type";
CM_ SG_ 2047 GTW_bPillarNFCParam "Gateway: b pillar NFC param";
CM_ SG_ 2047 GTW_interiorLighting "Gateway: interior lighting";
CM_ SG_ 2047 GTW_headlightLevelerType "Gateway: headlight leveler type";
CM_ SG_ 2047 GTW_numberHVILNodes "Gateway: number HVIL nodes";
CM_ SG_ 2047 GTW_mapRegion "Gateway: map region";
CM_ SG_ 2047 GTW_performancePackage "Gateway: performance package";
CM_ SG_ 2047 GTW_chassisType "Indicates the chassis type, which determines physical aspects such as suspension geometry, track width, wheel base, baseline tire size, and trailer capability.";
CM_ SG_ 2047 GTW_airSuspension "Gateway: air suspension";
CM_ SG_ 2047 GTW_centerConsoleControllerType "Gateway: center console controller type";
CM_ SG_ 2047 GTW_autopilotCameraType "Gateway: autopilot camera type";
CM_ SG_ 2047 GTW_connectivityPackage "Gateway: connectivity package";
CM_ SG_ 2047 GTW_plcSupportType "Gateway: plc support type";
CM_ SG_ 2047 GTW_badgingVersion "Gateway: badging version";
CM_ SG_ 2047 GTW_packEnergy "Gateway: pack energy";
CM_ SG_ 2047 GTW_frontSeatReclinerHardware "Gateway: front seat recliner hardware";
CM_ SG_ 2047 GTW_brakeLineSwitchType "Gateway: brake line switch type";
CM_ SG_ 2047 GTW_espValveType "Gateway: esp valve type";
CM_ SG_ 2047 GTW_softRange "Gateway: soft range";
CM_ SG_ 2047 GTW_refrigerantType "Gateway: refrigerant type";
CM_ SG_ 2047 GTW_wheelType "Gateway: wheel type";
CM_ SG_ 2047 GTW_ptcControlMode "Gateway: ptc control mode";
CM_ SG_ 2047 GTW_brakeActuationType "Gateway: brake actuation type";
CM_ SG_ 2047 GTW_secondRowSeatType "Gateway: second row seat type";
CM_ SG_ 2047 GTW_secondRowSeatMotorType "Gateway: second row seat motor type";
CM_ SG_ 2047 GTW_birthday "Gateway: birthday";
CM_ SG_ 2047 GTW_eCallEnabled "Gateway: e call enabled";
CM_ SG_ 2047 GTW_parkAssistECUType "Gateway: park assist ECU type";
CM_ SG_ 2047 GTW_passengerAirbagType "Gateway: passenger airbag type";
CM_ SG_ 2047 GTW_forwardRadarHw "Gateway: forward radar hw";
CM_ SG_ 2047 GTW_frontSeatType "Gateway: front seat type";
CM_ SG_ 2047 GTW_secondRowDisplayType "Gateway: second row display type";
CM_ SG_ 2047 GTW_wirelessPhoneChargerType "Gateway: wireless phone charger type";
CM_ SG_ 2047 GTW_ethernetTunerType "Gateway: ethernet tuner type";
CM_ SG_ 2047 GTW_interiorTrimType "Gateway: interior trim type";
CM_ SG_ 2047 GTW_gloveboxUSBType "Gateway: glovebox USB type";
CM_ SG_ 2047 GTW_coolantPumpType "Gateway: coolant pump type";
CM_ SG_ 2047 GTW_epblHwType "Gateway: epbl hw type";
CM_ SG_ 2047 GTW_epbrHwType "Gateway: epbr hw type";
CM_ SG_ 2047 GTW_blowerMotorType "Gateway: blower motor type";
CM_ SG_ 2047 GTW_rearLeftBLEEndpointParameter "Gateway: rear left BLE endpoint parameter type";
CM_ SG_ 2047 GTW_powerMirrorFoldType "Gateway: power mirror fold type";
CM_ SG_ 2047 GTW_frontUsbHubType "Gateway: front usb hub type";
CM_ SG_ 2047 GTW_superManifoldType "Type of HVAC super manifold installed";
CM_ SG_ 2047 GTW_rcmLocation "Gateway: rcm location";
CM_ SG_ 2047 GTW_autopilotExteriorCameraType "Gateway: autopilot exterior camera type";
CM_ SG_ 2047 GTW_interiorCamBeautyCoverType "Gateway: interior cam beauty cover type";
CM_ SG_ 2047 GTW_sirenType "Gateway: siren type";
CM_ SG_ 2047 GTW_hornType "Gateway: horn type";
CM_ SG_ 2047 GTW_passengerTrackMotorType "Gateway: passenger track motor type";
CM_ SG_ 2047 GTW_steeringColumnMotorType "Gateway: steering column motor type";
CM_ SG_ 2047 GTW_refrigACLineType "Gateway: refrig AC line type";
CM_ SG_ 2047 GTW_refrigFilterType "Gateway: refrig filter type";
CM_ SG_ 2047 GTW_diBurnInType "Gateway: di burn in type";
CM_ SG_ 2047 GTW_specialBadgingType "Gateway: special badging type";
CM_ SG_ 2047 GTW_chassisSubType "Reports chassis sub-variant type.";
CM_ SG_ 2047 GTW_towPackage "Gateway: tow package";
CM_ SG_ 2047 GTW_refrigLccType "Gateway: refrig lcc type";
CM_ SG_ 2047 GTW_restraintControlsType "Gateway: restraint controls type";
CM_ SG_ 2047 GTW_caliperColorType "Gateway: caliper color type";
CM_ SG_ 2047 GTW_wiperMotorType "Gateway: wiper motor type";
CM_ SG_ 2047 GTW_frontOverheadConsoleType "Gateway: front overhead console type";
CM_ SG_ 2047 GTW_shifterType "Gateway: shifter type";
CM_ SG_ 2047 GTW_compressorType "Gateway: compressor type";
CM_ SG_ 2047 GTW_twelveVBatteryType "Gateway: twelve v battery type";
CM_ SG_ 2047 GTW_efuseSWConfig "Gateway: efuse SW config";
CM_ SG_ 2047 GTW_tollCollectionModuleType "Gateway: toll collection module type";
CM_ SG_ 2047 GTW_bleEndpointUpdateMethod "Gateway: ble endpoint update method";
CM_ SG_ 2047 GTW_steeringWheelControllerType "Gateway: steering wheel controller type";
CM_ SG_ 2047 GTW_frontSeatVentilationEnabled "Gateway: front seat ventilation enabled";
CM_ SG_ 2047 GTW_gloveboxActuatorType "Gateway: glovebox actuator type";
CM_ SG_ 2047 GTW_epasType "Gateway: epas type";
CM_ SG_ 2047 GTW_homologationRegionOverride "Gateway: homologation region override";
CM_ SG_ 2047 GTW_windowCommandsPermissionType "Gateway: window commands permission type";
CM_ SG_ 2047 GTW_headlightStepperStallDetectM "Gateway: headlight stepper stall detect mode";
CM_ SG_ 2047 GTW_rgbInteriorLightingEnabled "Gateway: rgb interior lighting enabled";
CM_ SG_ 2047 GTW_windshieldWiperHeaterType "Gateway: windshield wiper heater type";
CM_ SG_ 2047 GTW_thirdRowSeatReclinerType "Gateway: third row seat recliner type";
CM_ SG_ 2047 GTW_driveInterfaceType "Gateway: drive interface type";
CM_ SG_ 2047 GTW_efficiencyPackage "Gateway: efficiency package";
CM_ SG_ 2047 GTW_visorLightType "Gateway: visor light type";
CM_ SG_ 2047 GTW_gnssAntennaType "Gateway: gnss antenna type";
CM_ SG_ 2047 GTW_airDistributionBoxType "Gateway: air distribution box type";
CM_ SG_ 2047 GTW_frontSeatHeatersEnabled "Gateway: front seat heaters enabled";
CM_ SG_ 2047 GTW_windshieldWiperHeaterEnabled "Gateway: windshield wiper heater enabled";
CM_ SG_ 2047 GTW_alcoholInterlockType "Gateway: alcohol interlock type";
CM_ SG_ 2047 GTW_fasciaType "Gateway: fascia type";
CM_ SG_ 2047 GTW_powerSteeringColumn "Gateway: power steering column";
CM_ SG_ 2047 GTW_frontSeatHeaterType "Gateway: front seat heater type";
CM_ SG_ 2047 GTW_softPerformanceLimit "Gateway: soft performance limit";
CM_ SG_ 2047 GTW_gsrFeatureType "Gateway: gsr feature type";
CM_ SG_ 2047 GTW_immersiveAudio "Gateway: immersive audio";
CM_ SG_ 2047 GTW_frontSeatVentilationType "Gateway: front seat ventilation type";
CM_ SG_ 2047 GTW_passengerOccupancySensorType "Gateway: passenger occupancy sensor type";
CM_ SG_ 2047 GTW_packPerformanceDeviation "Measures deviation from standard pack mass or power output capability associated with the vehicle packEnergy configuration.";
CM_ SG_ 2047 GTW_pressurePadType "Gateway: pressure pad type";
CM_ SG_ 2047 GTW_frontFogLamps "Gateway: front fog lamps";
CM_ SG_ 2047 GTW_driverOccupancySensorType "Gateway: driver occupancy sensor type";
CM_ SG_ 2047 GTW_audioType "Gateway: audio type";
CM_ SG_ 2047 GTW_thighExtenderType "Gateway: thigh extender type";
CM_ SG_ 2047 GTW_occupancyClassificationFeatu "Gateway: occupancy classification feature type";
CM_ SG_ 2047 GTW_frontControllerArchitectureT "Reports internal microcontroller architecture of the Front Controller assembly, which contains the Front Vehicle Controller (VCFRONT) and may contain a Vehicle Battery Controller (VCBATT).";
CM_ SG_ 2047 GTW_domeLightType "Gateway: dome light type";
CM_ SG_ 2047 GTW_tpmsType "Gateway: tpms type";
CM_ SG_ 2047 GTW_authenticationEndpointLayout "Gateway: authentication endpoint layout";
CM_ SG_ 2047 GTW_socSleepOverride "Gateway: soc sleep override";
CM_ SG_ 2047 GTW_r79BehaviorOverride "Gateway: r79 behavior override";
CM_ SG_ 2047 GTW_steeringHeaterType "Gateway: steering heater type";
CM_ SG_ 2047 GTW_narrowWipingSupported "Gateway: narrow wiping supported";
CM_ SG_ 2047 GTW_frontSeatHeaterGridType "Gateway: front seat heater grid type";
CM_ SG_ 2047 GTW_frontSeatSideSwitchType "Gateway: front seat side switch type";
CM_ SG_ 2047 GTW_sohRegulatoryStatus "Gateway: soh regulatory status";
CM_ SG_ 2047 GTW_passengerTiltMotorType "Gateway: passenger tilt motor type";
CM_ SG_ 2047 GTW_frunkInteriorReleaseType "Gateway: frunk interior release type";
CM_ SG_ 2047 GTW_m3yBusArchitecture "Reports notable features of vehicle communication bus architecture. Used for firmware artifact selection during update installation process.";
CM_ SG_ 2047 GTW_passengerLiftMotorType "Gateway: passenger lift motor type";
CM_ SG_ 2047 GTW_interiorUpperTrimType "Gateway: interior upper trim type";
CM_ SG_ 2047 GTW_blindSpotIndicatorLightType "Gateway: blind spot indicator light type";
CM_ SG_ 2047 GTW_wiperMotorAsicType "Gateway: wiper motor asic type";
CM_ SG_ 2047 GTW_hvacCaseDoorType "Gateway: hvac case door type";
CM_ SG_ 2047 GTW_occupancyDetectionSourceRequ "Gateway: occupancy detection source request";
CM_ SG_ 2047 GTW_rduCableType "Indicates type of rear drive unit cable installed on vehicle.";
CM_ SG_ 2047 GTW_parkTelltaleBehaviorType "Gateway: park telltale behavior type";
CM_ SG_ 2047 GTW_numberKeyCardsPairedInFactor "Gateway: number key cards paired in factory";
CM_ SG_ 2047 GTW_secondRowSeatVentilationType "Gateway: second row seat ventilation type";
CM_ SG_ 2047 GTW_thirdRowSeatHeaterType "Gateway: third row seat heater type";
CM_ SG_ 2047 GTW_interiorCameraType "Gateway: interior camera type";
CM_ SG_ 2047 GTW_frontFasciaCameraType "Reports type of forward facing fascia camera installed.";
CM_ SG_ 2047 GTW_interiorCamFanType "Gateway: interior cam fan type";
CM_ SG_ 2047 GTW_puddleLampType "Gateway: puddle lamp type";
CM_ SG_ 2047 GTW_solarLensType "Gateway: solar lens type";
CM_ SG_ 2047 GTW_liftgateGeometryType "Gateway: liftgate geometry type";
CM_ SG_ 2047 GTW_repeaterAeroRibType "Gateway: repeater aero rib type";
CM_ SG_ 2047 GTW_highTipForceWiperArmsType "Gateway: high tip force wiper arms type";
CM_ SG_ 2047 GTW_rcmUndersideAbuseZThreshold "Gateway: rcm underside abuse z threshold";
CM_ SG_ 2047 GTW_rcmUndersideAbuseYThreshold "Gateway: rcm underside abuse y threshold";
CM_ SG_ 2047 GTW_rcmUndersideAbuseWindow "Gateway: rcm underside abuse window";
CM_ SG_ 2047 GTW_uhfChargePortEnabled "Gateway: uhf charge port enabled";
CM_ SG_ 2047 GTW_automaticFeatureResetPackage "Gateway: automatic feature reset package";
CM_ SG_ 2047 GTW_autopilotFeaturePackage "Gateway: autopilot feature package";
CM_ SG_ 2047 GTW_doorLatchType "Gateway: door latch type";
CM_ SG_ 2047 GTW_headlinerMaterialType "Gateway: headliner material type";
CM_ SG_ 2047 GTW_glareShieldHeaterType "Gateway: glare shield heater type";
CM_ SG_ 2047 GTW_rearLightHardwareVariant "Gateway: rear light hardware variant";
CM_ SG_ 2047 GTW_fasciaHarnessCleanPointType "Gateway: fascia harness clean point type";
CM_ SG_ 2047 GTW_epasSubType "Gateway: epas sub type";
CM_ SG_ 2047 GTW_wiperSupplyChainOrigin "Gateway: wiper supply chain origin; raw 0 = signal not available (SNA)";
CM_ SG_ 2047 GTW_windowPinchParameterType "Gateway: window pinch parameter type";
CM_ SG_ 2047 GTW_badgingMaterialType "Gateway: badging material type";
CM_ SG_ 2047 GTW_mRecordVersion "Gateway: m record version";
CM_ SG_ 2047 GTW_tcuType "Gateway: tcu type";
CM_ SG_ 2047 GTW_carbComplianceBehaviorType "Gateway: carb compliance behavior type";
CM_ SG_ 2047 GTW_indirectTPMSCalibrationType "Indirect TPMS calibration type.";
CM_ SG_ 2047 GTW_v2xEnabled "Gateway: v2x enabled";
CM_ SG_ 2047 GTW_liftgateStrutType "Gateway: liftgate strut type";
CM_ SG_ 2047 GTW_exteriorMicrophoneType "Gateway: exterior microphone type";
CM_ SG_ 2047 GTW_contactorPowerSource "Gateway: contactor power source";
CM_ SG_ 2047 GTW_roofGlassType "Gateway: roof glass type";
CM_ SG_ 2047 GTW_pedalMapNameOverride "Gateway: pedal map name override";
CM_ BO_ 792 "Gateway message: car state";
CM_ SG_ 792 GTW_factoryGated "Gateway: factory gated";
CM_ BO_ 1638 "Gateway message: diag session";
CM_ SG_ 1638 GTW_diagRemainingSeconds "Seconds remaining for the diagnostics session";
CM_ SG_ 1638 GTW_diagSessionActive "UDS Session Active";
CM_ SG_ 1638 GTW_diagLevel "Current diagnostics level";
CM_ SG_ 1638 GTW_diagUnlockProcedureActive "GTW diag unlock procedure active";
CM_ SG_ 1638 GTW_diagOverrideActive "GTW diag level override active";
CM_ SG_ 1638 GTW_diagPhysicalLinkEstablished "Physical diag cable connected to the switch and link established";
CM_ BO_ 1080 "Gateway message: eth nm";
CM_ SG_ 1080 GTW_ethGotoSleep "ETH bus sleep commanded";
CM_ SG_ 1080 GTW_ethWakeUpBus "Gateway: eth wake up bus";
CM_ SG_ 1080 GTW_vehBusAsleep "VEH bus sleep state";
CM_ SG_ 1080 GTW_ethHeartBeatCounter "Gateway: eth heart beat counter";
CM_ SG_ 1080 GTW_ethWakeUpReason "Tracks the cause of why the gateway wakes up the ethernet bus";
CM_ BO_ 1376 "Gateway message: factory ecu present";
CM_ SG_ 1376 GTW_OCS1Ppresent "Gateway: OCS1 ppresent";
CM_ SG_ 1376 GTW_PCSpresent "Gateway: PC spresent";
CM_ SG_ 1376 GTW_HVPpresent "Gateway: HV ppresent";
CM_ SG_ 1376 GTW_BMSpresent "Gateway: BM spresent";
CM_ SG_ 1376 GTW_CPpresent "Gateway: c ppresent";
CM_ SG_ 1376 GTW_RCMpresent "Gateway: RC mpresent";
CM_ SG_ 1376 GTW_SCCMpresent "Gateway: SCC mpresent";
CM_ SG_ 1376 GTW_VCSECpresent "Gateway: VCSE cpresent";
CM_ SG_ 1376 GTW_EPAS3Ppresent "Gateway: EPAS3 ppresent";
CM_ SG_ 1376 GTW_EPBLpresent "Gateway: EPB lpresent";
CM_ SG_ 1376 GTW_EPBRpresent "Gateway: EPB rpresent";
CM_ SG_ 1376 GTW_ESPpresent "Gateway: ES ppresent";
CM_ SG_ 1376 GTW_IBSTpresent "Gateway: IBS tpresent";
CM_ SG_ 1376 GTW_PARKpresent "Gateway: PAR kpresent";
CM_ SG_ 1376 GTW_RADCpresent "Gateway: RAD cpresent";
CM_ SG_ 1376 GTW_TPMSpresent "Gateway: TPM spresent";
CM_ SG_ 1376 GTW_VCFRONTpresent "Gateway: VCFRON tpresent";
CM_ SG_ 1376 GTW_VCLEFTpresent "Gateway: VCLEF tpresent";
CM_ SG_ 1376 GTW_VCRIGHTpresent "Gateway: VCRIGH tpresent";
CM_ SG_ 1376 GTW_EPAS3Spresent "Gateway: EPAS3 spresent";
CM_ SG_ 1376 GTW_CMPpresent "Gateway: CM ppresent";
CM_ SG_ 1376 GTW_DASpresent "Gateway: DA spresent";
CM_ SG_ 1376 GTW_PTCpresent "Gateway: PT cpresent";
CM_ SG_ 1376 GTW_SWCpresent "Gateway: SW cpresent";
CM_ SG_ 1376 GTW_PMRpresent "Gateway: PM rpresent";
CM_ SG_ 1376 GTW_PMFpresent "Gateway: PM fpresent";
CM_ SG_ 1376 GTW_DIRpresent "Gateway: DI rpresent";
CM_ SG_ 1376 GTW_DIFpresent "Gateway: DI fpresent";
CM_ BO_ 1656 "Gateway message: gear control";
CM_ SG_ 1656 GTW_gearControlChecksum "Gateway: gear control checksum";
CM_ SG_ 1656 GTW_gearControlCounter "Gateway: gear control counter";
CM_ SG_ 1656 GTW_gearShiftRequest "Request to change gear state from center display UI control; raw 0 = signal not available (SNA)";
CM_ SG_ 1656 GTW_osdActive "Whether OSD is active";
CM_ SG_ 1656 GTW_primaryGearControlStatus "Status of the center display UI control";
CM_ SG_ 1656 GTW_gearStripEnable "UI control for showing and or activating the primary gear strip interface";
CM_ SG_ 1656 GTW_showNeutralButton "Tell UI that it is time to animate the N button to be shown";
CM_ SG_ 1656 GTW_showAutoParkButton "Tell UI that it is time to animate the autopark button to be shown";
CM_ SG_ 1656 GTW_autoParkRequest "Request to auto park from center display UI control";
CM_ SG_ 1656 GTW_smartShiftStatus "Based on the status of the infotainment system smart shift feature should be disabled; raw 0 = signal not available (SNA)";
CM_ SG_ 1656 GTW_processingRDgestures "Is GTW processing R and D swipe gestures";
CM_ SG_ 1656 GTW_processingTapPgestures "Is GTW processing contextual tap-to-park gestures";
CM_ SG_ 1656 GTW_gearStripChangeReason "Gateway: gear strip change reason; raw 0 = signal not available (SNA)";
CM_ SG_ 1656 GTW_touchActive "User present as touch on display is active";
CM_ SG_ 1656 GTW_steamOff "Let UI know to turn Steam off";
CM_ SG_ 1656 GTW_screenPCBTemperature "Reading from display i2c temperature sensor; raw 2047 = signal not available (SNA)";
CM_ BO_ 2033 "Gateway message: hrl";
CM_ SG_ 2033 GTW_hrlIndex "Gateway: hrl index";
CM_ SG_ 2033 GTW_hrlPagesCount "Gateway: hrl pages count";
CM_ SG_ 2033 GTW_hrlSdCardSizeGB "Gateway: hrl sd card size GB; raw 0 = signal not available (SNA)";
CM_ SG_ 2033 GTW_hrlState "GTW hrl state";
CM_ SG_ 2033 GTW_hrlTriggerDuration "HRL duration";
CM_ SG_ 2033 GTW_hrlTriggerType "HRL trigger type";
CM_ SG_ 2033 GTW_hrlTriggerId "HRL trigger ID. A unique ID representing the signal conditions causing the HRL event to occur.";
CM_ SG_ 2033 GTW_hrlTriggerBus "Gateway: hrl trigger bus";
CM_ BO_ 2026 "Gateway message: hrl external event";
CM_ SG_ 2026 GTW_hrlEventStartEpoch "Gateway: hrl event start epoch";
CM_ SG_ 2026 GTW_hrlEventEndEpoch "Gateway: hrl event end epoch";
CM_ BO_ 60 "Gateway message: info";
CM_ SG_ 60 GTW_infoIndex "Gateway: info index";
CM_ SG_ 60 GTW_buildType "Gateway: build type";
CM_ SG_ 60 GTW_hardwareId "GTW hardware ID";
CM_ SG_ 60 GTW_platformType "Gateway: platform type";
CM_ SG_ 60 GTW_appCrc "Gateway: app crc";
CM_ SG_ 60 GTW_applicationGitHash "Gateway: application git hash";
CM_ SG_ 60 GTW_bootGitHash "Gateway: boot git hash";
CM_ BO_ 1370 "Gateway message: mismatch fault";
CM_ SG_ 1370 GTW_mismatchFaultIndex "Gateway: mismatch fault index";
CM_ SG_ 1370 GTW_mismatchFaultChecksum "Gateway: mismatch fault checksum";
CM_ SG_ 1370 GTW_mismatchFaultCounter "Gateway: mismatch fault counter";
CM_ SG_ 1370 GTW_GTWmismatchFault "Reports the Gateway (GTW) running a firmware version that does not match the rest of the vehicle";
CM_ SG_ 1370 GTW_BMSmismatchFault "Reports the high voltage Battery Management System (BMS) electronic control unit (ECU) running a firmware version that does not match the rest of the vehicle";
CM_ SG_ 1370 GTW_APSmismatchFault "Reports the Autopilot Processor Secondary (APS) electronic control unit (ECU) running a firmware version that does not match the rest of the vehicle";
CM_ SG_ 1370 GTW_BLEEPCENTERmismatchFault "Reports the Bluetooth Low Energy End Point Center (BLEEPCENTER) electronic control unit (ECU) running a firmware version that does not match the rest of the vehicle";
CM_ SG_ 1370 GTW_BLEEPLEFTmismatchFault "Reports the Bluetooth Low Energy End Point Left (BLEEPLEFT) electronic control unit (ECU) running a firmware version that does not match the rest of the vehicle";
CM_ SG_ 1370 GTW_BLEEPREARmismatchFault "Reports the Bluetooth Low Energy End Point Rear (BLEEPREAR) electronic control unit (ECU) running a firmware version that does not match the rest of the vehicle";
CM_ SG_ 1370 GTW_BLEEPRIGHTmismatchFault "Reports the Bluetooth Low Energy End Point Right (BLEEPRIGHT) electronic control unit (ECU) running a firmware version that does not match the rest of the vehicle";
CM_ SG_ 1370 GTW_CBCmismatchFault "Reports the Cabin Blower Controller (CBC) electronic control unit (ECU) running a firmware version that does not match the rest of the vehicle";
CM_ SG_ 1370 GTW_CMPmismatchFault "Reports the air conditioning compressor (CMP) electronic control unit (ECU) running a firmware version that does not match the rest of the vehicle";
CM_ SG_ 1370 GTW_CPmismatchFault "Reports the Charge Port (CP) electronic control unit (ECU) running a firmware version that does not match the rest of the vehicle";
CM_ SG_ 1370 GTW_DIFmismatchFault "Reports the front drive inverter (DIF) electronic control unit (ECU) running a firmware version that does not match the rest of the vehicle";
CM_ SG_ 1370 GTW_DIRmismatchFault "Reports the rear drive inverter (DIR) electronic control unit (ECU) running a firmware version that does not match the rest of the vehicle";
CM_ SG_ 1370 GTW_EPAS3PmismatchFault "Reports the primary Electronic Power Assisted Steering (EPAS3P) electronic control unit (ECU) running a firmware version that does not match the rest of the vehicle";
CM_ SG_ 1370 GTW_EPAS3SmismatchFault "Reports the secondary Electronic Power Assisted Steering (EPAS3S) electronic control unit (ECU) running a firmware version that does not match the rest of the vehicle";
CM_ SG_ 1370 GTW_EPBLmismatchFault "Reports the left Electronic Park Brake (EPBL) electronic control unit (ECU) running a firmware version that does not match the rest of the vehicle";
CM_ SG_ 1370 GTW_EPBRmismatchFault "Reports the right Electronic Park Brake (EPBR) electronic control unit (ECU) running a firmware version that does not match the rest of the vehicle";
CM_ SG_ 1370 GTW_ESPCALmismatchFault "Reports the Electronic Stability Program Calibration (ESPCAL) electronic control unit (ECU) running a firmware version that does not match the rest of the vehicle";
CM_ SG_ 1370 GTW_ESPmismatchFault "Reports the Electronic Stability Program (ESP) electronic control unit (ECU) running a firmware version that does not match the rest of the vehicle";
CM_ SG_ 1370 GTW_HCM3LmismatchFault "Reports the left LED matrix Headlamp Control Module (HCM3L) electronic control unit (ECU) running a firmware version that does not match the rest of the vehicle";
CM_ SG_ 1370 GTW_HCM3RmismatchFault "Reports the right LED matrix Headlamp Control Module (HCM3R) electronic control unit (ECU) running a firmware version that does not match the rest of the vehicle";
CM_ SG_ 1370 GTW_HCMLmismatchFault "Reports the left Headlamp Control Module (HCML) electronic control unit (ECU) running a firmware version that does not match the rest of the vehicle";
CM_ SG_ 1370 GTW_HCMRmismatchFault "Reports the right Headlamp Control Module (HCMR) electronic control unit (ECU) running a firmware version that does not match the rest of the vehicle";
CM_ SG_ 1370 GTW_HVPmismatchFault "Reports the High Voltage Processor (HVP) electronic control unit (ECU) running a firmware version that does not match the rest of the vehicle";
CM_ SG_ 1370 GTW_IBSTCALmismatchFault "Reports the electromechanical brake booster calibration, or iBooster Calibration (IBSTCAL), electronic control unit (ECU) running a firmware version that does not match the rest of the vehicle";
CM_ SG_ 1370 GTW_IBSTmismatchFault "Reports the electromechanical brake booster, or iBooster (IBST), electronic control unit (ECU) running a firmware version that does not match the rest of the vehicle";
CM_ SG_ 1370 GTW_LVBMSmismatchFault "Reports the Low Voltage Battery Management System (LVBMS) electronic control unit (ECU) running a firmware version that does not match the rest of the vehicle";
CM_ SG_ 1370 GTW_OCS1PmismatchFault "Reports the Occupancy Classification System - 1st Row Passenger (OCS1P) electronic control unit (ECU) running a firmware version that does not match the rest of the vehicle";
CM_ SG_ 1370 GTW_OPCFmismatchFault "Reports the front Oil Pump Controller (OPCF) electronic control unit (ECU) running a firmware version that does not match the rest of the vehicle";
CM_ SG_ 1370 GTW_OPCRmismatchFault "Reports the rear Oil Pump Controller (OPCR) electronic control unit (ECU) running a firmware version that does not match the rest of the vehicle";
CM_ SG_ 1370 GTW_PARKmismatchFault "Reports the Park Assist (PARK) electronic control unit (ECU) running a firmware version that does not match the rest of the vehicle";
CM_ SG_ 1370 GTW_PCSCPU2mismatchFault "Reports the Power Conversion System AC charging core (PCSCPU2) electronic control unit (ECU) running a firmware version that does not match the rest of the vehicle";
CM_ SG_ 1370 GTW_PCSmismatchFault "Reports the Power Conversion System (PCS) electronic control unit (ECU) running a firmware version that does not match the rest of the vehicle";
CM_ SG_ 1370 GTW_PMFmismatchFault "Reports the front Pedal Monitor (PMF) electronic control unit (ECU) running a firmware version that does not match the rest of the vehicle";
CM_ SG_ 1370 GTW_PMRmismatchFault "Reports the rear Pedal Monitor (PMR) electronic control unit (ECU) running a firmware version that does not match the rest of the vehicle";
CM_ SG_ 1370 GTW_PTCmismatchFault "Reports the Positive Temperature Coefficient (PTC) heater electronic control unit (ECU) running a firmware version that does not match the rest of the vehicle";
CM_ SG_ 1370 GTW_RCMCALmismatchFault "Reports the Restraint Control Module Calibration (RCMCAL) electronic control unit (ECU) running a firmware version that does not match the rest of the vehicle";
CM_ SG_ 1370 GTW_RCMmismatchFault "Reports the Restraint Control Module (RCM) electronic control unit (ECU) running a firmware version that does not match the rest of the vehicle";
CM_ SG_ 1370 GTW_SCCMmismatchFault "Reports the Steering Column Control Module (SCCM) electronic control unit (ECU) running a firmware version that does not match the rest of the vehicle";
CM_ SG_ 1370 GTW_SDCRmismatchFault "Reports the Secondary Disconnect Controller (SDCR) electronic control unit (ECU) running a firmware version that does not match the rest of the vehicle";
CM_ SG_ 1370 GTW_SWCmismatchFault "Reports the Steering Wheel Controller (SWC) electronic control unit (ECU) running a firmware version that does not match the rest of the vehicle";
CM_ SG_ 1370 GTW_THSmismatchFault "Reports the Temperature Humidity Sensor (THS) electronic control unit (ECU) running a firmware version that does not match the rest of the vehicle";
CM_ SG_ 1370 GTW_VCFRONTmismatchFault "Reports the front vehicle controller (VCFRONT) electronic control unit (ECU) running a firmware version that does not match the rest of the vehicle";
CM_ SG_ 1370 GTW_VCLEFTmismatchFault "Reports the left vehicle controller (VCLEFT) electronic control unit (ECU) running a firmware version that does not match the rest of the vehicle";
CM_ SG_ 1370 GTW_VCRIGHTmismatchFault "Reports the right vehicle controller (VCRIGHT) electronic control unit (ECU) running a firmware version that does not match the rest of the vehicle";
CM_ SG_ 1370 GTW_VCSECmismatchFault "Reports the vehicle security controller (VCSEC) electronic control unit (ECU) running a firmware version that does not match the rest of the vehicle";
CM_ SG_ 1370 GTW_PMmismatchFault "Reports the Pedal Monitor (PM) electronic control unit (ECU) running a firmware version that does not match the rest of the vehicle";
CM_ BO_ 840 "Gateway message: status";
CM_ SG_ 840 GTW_vehicleVersionMatchStatus "Signal to indicate if the vehicle ECUs are all on a matched production version";
CM_ SG_ 840 GTW_hwtype "Describes the chip GTW is running on; raw 0 = signal not available (SNA)";
CM_ SG_ 840 GTW_jcanProductName "Describes the JCAN reference (product) name; raw 0 = signal not available (SNA)";
CM_ SG_ 840 GTW_uptimeSeconds "GTW uptime in seconds";
CM_ SG_ 840 GTW_boardRevision "Board revision ID of the MCU PCBA";
CM_ SG_ 840 GTW_touchcoreOsType "Gateway: touchcore os type";
CM_ SG_ 840 GTW_sentryModeState "Sentry Mode state; raw 6 = signal not available (SNA)";
CM_ SG_ 840 GTW_secureBootEnabled "Gateway: secure boot enabled";
CM_ SG_ 840 GTW_socSleepType "Describes the sleep type GTW is expecting from the SoC; raw 0 = signal not available (SNA)";
CM_ SG_ 840 GTW_resetType "Describes the type of reset GTW experienced; raw 0 = signal not available (SNA)";
CM_ BO_ 1005 "Gateway message: update status";
CM_ SG_ 1005 GTW_i2cUpdateActive "Gateway: i2c update active";
CM_ SG_ 1005 GTW_peripheralConfirmedUpdateNee "Detects if peripheral has confirmed update is needed";
CM_ SG_ 1005 GTW_ocuFailed "Reports the offboard charger update was unsuccessful.";
CM_ SG_ 1005 GTW_ecuUpdateStarted "Reports whether Electronic Control Unit (ECU) update phase is active.";
CM_ SG_ 1005 GTW_updateStarted "Main update in progress bit";
CM_ BO_ 1112 "Gateway message: veh nm";
CM_ SG_ 1112 GTW_nmGoingToSleep "Network management - Going to sleep state";
CM_ SG_ 1112 GTW_nmWakeUpBus "Gateway: nm wake up bus";
CM_ SG_ 1112 GTW_chBusAsleep "Chassis bus sleep state";
CM_ SG_ 1112 GTW_ethBusAsleep "ETH bus sleep state";
CM_ SG_ 1112 GTW_nmKeepAwakeReason "Network management - Keep awake reason; raw 0 = signal not available (SNA)";
CM_ SG_ 1112 GTW_nmWakeUpReason "Network management - Wakeup reason";
CM_ SG_ 1112 GTW_ethKeepAwakeReason "Reason GTW is keeping ETH bus awake; raw 0 = signal not available (SNA)";
CM_ SG_ 1112 GTW_nmDebugWakeUp "Gateway: nm debug wake up";
CM_ SG_ 1112 GTW_OTAKeepAwake "Signals that the vehicle buses should remain awake for an ongoing OTA update";
CM_ SG_ 1112 GTW_smsPokeReceived "The modem indicated it received an SMS poke";
CM_ SG_ 1112 GTW_bdyBusAsleep "BDY bus sleep state";
CM_ BO_ 1650 "HCML ECU message: info";
CM_ SG_ 1650 VC_hcmlInfoIndex "HCML ECU: hcml info index";
CM_ SG_ 1650 VC_infoHCMLBuildConfigId "HCM Diagnostic Field.";
CM_ SG_ 1650 VC_leftHeadlampLMMVariant "Reports the detected left headlamp LED Matrix Manager (LMM) variant; raw 0 = signal not available (SNA)";
CM_ SG_ 1650 VC_infoHCMLAssemblyId "HCM Diagnostic Field.";
CM_ SG_ 1650 VC_infoHCMLPcbaId "HCM Diagnostic Field.";
CM_ SG_ 1650 VC_infoHCMLUsageId "HCM Diagnostic Field.";
CM_ BO_ 1980 "HCMR ECU message: info";
CM_ SG_ 1980 VC_hcmrInfoIndex "HCMR ECU: hcmr info index";
CM_ SG_ 1980 VC_infoHCMRBuildConfigId "HCM Diagnostic Field.";
CM_ SG_ 1980 VC_rightHeadlampLMMVariant "Reports the detected right headlamp LED Matrix Manager (LMM) variant; raw 0 = signal not available (SNA)";
CM_ SG_ 1980 VC_infoHCMRAssemblyId "HCM Diagnostic Field.";
CM_ SG_ 1980 VC_infoHCMRPcbaId "HCM Diagnostic Field.";
CM_ SG_ 1980 VC_infoHCMRUsageId "HCM Diagnostic Field.";
BA_DEF_ BO_ "GenMsgCycleTime" INT 0 3600000;
BA_DEF_ BO_ "GenMsgSendType" ENUM "Cyclic","NotUsed","NotUsed","NotUsed","NotUsed","NotUsed","NotUsed","IfActive","NoMsgSendType","NotUsed";
BA_DEF_ BO_ "VFrameFormat" ENUM "StandardCAN","ExtendedCAN","reserved","J1939PG","reserved","reserved","reserved","reserved","reserved","reserved","reserved","reserved","reserved","reserved","StandardCAN_FD","ExtendedCAN_FD";
BA_DEF_ BO_ "CANFD_BRS" ENUM "0","1";
BA_DEF_ SG_ "GenSigSNA" STRING;
BA_DEF_ SG_ "SystemSignalLongSymbol" STRING;
BA_DEF_ SG_ "Confidence" ENUM "validated","plausible","layout-only","contradicted";
BA_DEF_DEF_ "GenMsgCycleTime" 0;
BA_DEF_DEF_ "GenMsgSendType" "NoMsgSendType";
BA_DEF_DEF_ "VFrameFormat" "StandardCAN";
BA_DEF_DEF_ "CANFD_BRS" "1";
BA_DEF_DEF_ "GenSigSNA" "";
BA_DEF_DEF_ "SystemSignalLongSymbol" "";
BA_DEF_DEF_ "Confidence" "layout-only";
BA_ "GenMsgCycleTime" BO_ 1300 1000;
BA_ "GenMsgSendType" BO_ 1300 0;
BA_ "GenMsgCycleTime" BO_ 532 100;
BA_ "GenMsgSendType" BO_ 532 0;
BA_ "GenMsgCycleTime" BO_ 533 1000;
BA_ "GenMsgSendType" BO_ 533 0;
BA_ "GenMsgCycleTime" BO_ 535 1000;
BA_ "GenMsgSendType" BO_ 535 0;
BA_ "GenMsgCycleTime" BO_ 888 1000;
BA_ "GenMsgSendType" BO_ 888 0;
BA_ "GenMsgCycleTime" BO_ 282 1000;
BA_ "GenMsgSendType" BO_ 282 0;
BA_ "GenMsgCycleTime" BO_ 62 100;
BA_ "GenMsgSendType" BO_ 62 0;
BA_ "GenMsgCycleTime" BO_ 838 1000;
BA_ "GenMsgSendType" BO_ 838 0;
BA_ "GenMsgCycleTime" BO_ 904 1000;
BA_ "GenMsgSendType" BO_ 904 0;
BA_ "GenMsgCycleTime" BO_ 2047 100;
BA_ "GenMsgSendType" BO_ 2047 0;
BA_ "GenMsgCycleTime" BO_ 792 100;
BA_ "GenMsgSendType" BO_ 792 0;
BA_ "GenMsgCycleTime" BO_ 1638 250;
BA_ "GenMsgSendType" BO_ 1638 0;
BA_ "GenMsgCycleTime" BO_ 1080 100;
BA_ "GenMsgSendType" BO_ 1080 0;
BA_ "GenMsgCycleTime" BO_ 1376 1000;
BA_ "GenMsgSendType" BO_ 1376 0;
BA_ "GenMsgCycleTime" BO_ 1656 100;
BA_ "GenMsgSendType" BO_ 1656 0;
BA_ "GenMsgCycleTime" BO_ 2033 2000;
BA_ "GenMsgSendType" BO_ 2033 0;
BA_ "GenMsgCycleTime" BO_ 2026 1000;
BA_ "GenMsgSendType" BO_ 2026 0;
BA_ "GenMsgCycleTime" BO_ 60 2000;
BA_ "GenMsgSendType" BO_ 60 0;
BA_ "GenMsgCycleTime" BO_ 1370 250;
BA_ "GenMsgSendType" BO_ 1370 0;
BA_ "GenMsgCycleTime" BO_ 840 1000;
BA_ "GenMsgSendType" BO_ 840 0;
BA_ "GenMsgCycleTime" BO_ 1005 1000;
BA_ "GenMsgSendType" BO_ 1005 0;
BA_ "GenMsgCycleTime" BO_ 1112 100;
BA_ "GenMsgSendType" BO_ 1112 0;
BA_ "GenMsgCycleTime" BO_ 1650 10000;
BA_ "GenMsgSendType" BO_ 1650 0;
BA_ "GenMsgCycleTime" BO_ 1980 10000;
BA_ "GenMsgSendType" BO_ 1980 0;
BA_ "Confidence" SG_ 1300 FC_serialDataSelect 1;
BA_ "Confidence" SG_ 1300 FC_serialChar01 0;
BA_ "Confidence" SG_ 1300 FC_serialChar02 0;
BA_ "Confidence" SG_ 1300 FC_serialChar03 0;
BA_ "Confidence" SG_ 1300 FC_serialChar04 0;
BA_ "Confidence" SG_ 1300 FC_serialChar05 0;
BA_ "Confidence" SG_ 1300 FC_serialChar06 0;
BA_ "Confidence" SG_ 1300 FC_serialChar07 0;
BA_ "Confidence" SG_ 1300 FC_serialChar08 0;
BA_ "Confidence" SG_ 1300 FC_serialChar09 0;
BA_ "Confidence" SG_ 1300 FC_serialChar10 0;
BA_ "Confidence" SG_ 1300 FC_serialChar11 0;
BA_ "Confidence" SG_ 1300 FC_serialChar12 0;
BA_ "Confidence" SG_ 1300 FC_serialChar13 0;
BA_ "Confidence" SG_ 1300 FC_serialChar14 0;
BA_ "Confidence" SG_ 1300 FC_serialChar15 0;
BA_ "Confidence" SG_ 1300 FC_serialChar16 0;
BA_ "Confidence" SG_ 1300 FC_serialChar17 0;
BA_ "Confidence" SG_ 532 FC_protocolVersion 0;
BA_ "Confidence" SG_ 532 FC_statusCode 0;
BA_ "GenSigSNA" SG_ 532 FC_statusCode "0";
BA_ "Confidence" SG_ 532 FC_deprecated1 0;
BA_ "Confidence" SG_ 532 FC_deprecated2 0;
BA_ "Confidence" SG_ 532 FC_deprecated3 0;
BA_ "Confidence" SG_ 532 FC_adapterLocked 0;
BA_ "Confidence" SG_ 532 FC_minCurrentLimit 0;
BA_ "Confidence" SG_ 532 FC_type 0;
BA_ "GenSigSNA" SG_ 532 FC_type "7";
BA_ "Confidence" SG_ 532 FC_dcCurrent 0;
BA_ "Confidence" SG_ 532 FC_postID 0;
BA_ "GenSigSNA" SG_ 532 FC_postID "3";
BA_ "Confidence" SG_ 532 FC_dcVoltage 0;
BA_ "Confidence" SG_ 532 FC_leakageTestNotSupported 0;
BA_ "Confidence" SG_ 532 FC_dischargeSupported 0;
BA_ "Confidence" SG_ 533 FC_externalIsolationResistance 0;
BA_ "GenSigSNA" SG_ 533 FC_externalIsolationResistance "255";
BA_ "Confidence" SG_ 535 FC_status3DataSelect 1;
BA_ "Confidence" SG_ 535 FC_status3DummySig 0;
BA_ "Confidence" SG_ 535 FC_class 0;
BA_ "GenSigSNA" SG_ 535 FC_class "0";
BA_ "Confidence" SG_ 535 FC_brand 0;
BA_ "GenSigSNA" SG_ 535 FC_brand "0";
BA_ "Confidence" SG_ 535 FC_coolingType 0;
BA_ "GenSigSNA" SG_ 535 FC_coolingType "0";
BA_ "Confidence" SG_ 535 FC_uiStopType 0;
BA_ "GenSigSNA" SG_ 535 FC_uiStopType "0";
BA_ "Confidence" SG_ 535 FC_emergencyShutdownSupported 0;
BA_ "Confidence" SG_ 535 FC_generation 0;
BA_ "GenSigSNA" SG_ 535 FC_generation "0";
BA_ "Confidence" SG_ 535 FC_billingEnergy 1;
BA_ "Confidence" SG_ 888 GTW_GTW_SOS_ECALL_RQST 0;
BA_ "Confidence" SG_ 888 GTW_LTE_ECALL_LOCK 0;
BA_ "Confidence" SG_ 282 GTW_BKP_BATT_MON 1;
BA_ "GenSigSNA" SG_ 282 GTW_BKP_BATT_MON "4095";
BA_ "Confidence" SG_ 282 GTW_BKP_BATT_NTC_P 1;
BA_ "GenSigSNA" SG_ 282 GTW_BKP_BATT_NTC_P "4095";
BA_ "Confidence" SG_ 282 GTW_ECALL_GPS_ANT_BIAS 1;
BA_ "GenSigSNA" SG_ 282 GTW_ECALL_GPS_ANT_BIAS "4095";
BA_ "Confidence" SG_ 282 GTW_ECALL_MIC_DIAG 1;
BA_ "GenSigSNA" SG_ 282 GTW_ECALL_MIC_DIAG "4095";
BA_ "Confidence" SG_ 282 GTW_SOS_ECALL_nRQST_BUF 1;
BA_ "GenSigSNA" SG_ 282 GTW_SOS_ECALL_nRQST_BUF "4095";
BA_ "Confidence" SG_ 1384 GTW_alertID 1;
BA_ "Confidence" SG_ 1384 GTW_alertState 1;
BA_ "Confidence" SG_ 1384 GTW_a049_headerError 1;
BA_ "Confidence" SG_ 1384 GTW_a062_bmpWatchdogReason 1;
BA_ "Confidence" SG_ 1384 GTW_a063_VEH_faultConfinement 1;
BA_ "Confidence" SG_ 1384 GTW_a064_CH_faultConfinement 1;
BA_ "Confidence" SG_ 1384 GTW_a065_PARTY_faultConfinement 1;
BA_ "Confidence" SG_ 1384 GTW_a073_SOCResetRequestor 1;
BA_ "Confidence" SG_ 1384 GTW_a077_bmpPmicErrorType 1;
BA_ "Confidence" SG_ 1384 GTW_a122_BDY_faultConfinement 1;
BA_ "Confidence" SG_ 1384 GTW_a261_failureReason 1;
BA_ "Confidence" SG_ 1384 GTW_a277_mitigationFailureReason 1;
BA_ "Confidence" SG_ 1384 GTW_a279_failureReason 1;
BA_ "Confidence" SG_ 1384 GTW_a317_status 1;
BA_ "Confidence" SG_ 1384 GTW_a317_errorCode 1;
BA_ "Confidence" SG_ 62 GTW_matrixIndex 1;
BA_ "SystemSignalLongSymbol" SG_ 62 GTW_w016_BLEEPCENTERversionMisma "GTW_w016_BLEEPCENTERversionMismatch";
BA_ "SystemSignalLongSymbol" SG_ 62 GTW_w093_sdCardInvReqOverflowBas "GTW_w093_sdCardInvReqOverflowBase";
BA_ "SystemSignalLongSymbol" SG_ 62 GTW_w094_sdCardInvReqOverflowCou "GTW_w094_sdCardInvReqOverflowCount";
BA_ "SystemSignalLongSymbol" SG_ 62 GTW_w104_sdCardDriverArgCorrupte "GTW_w104_sdCardDriverArgCorrupted";
BA_ "SystemSignalLongSymbol" SG_ 62 GTW_w106_BLEEPLEFTversionMismatc "GTW_w106_BLEEPLEFTversionMismatch";
BA_ "SystemSignalLongSymbol" SG_ 62 GTW_w107_BLEEPRIGHTversionMismat "GTW_w107_BLEEPRIGHTversionMismatch";
BA_ "SystemSignalLongSymbol" SG_ 62 GTW_w108_BLEEPREARversionMismatc "GTW_w108_BLEEPREARversionMismatch";
BA_ "SystemSignalLongSymbol" SG_ 62 GTW_w117_unexpectedDestructiveRe "GTW_w117_unexpectedDestructiveResetStatus";
BA_ "SystemSignalLongSymbol" SG_ 62 GTW_w118_unexpectedFunctionalRes "GTW_w118_unexpectedFunctionalResetStatus";
BA_ "SystemSignalLongSymbol" SG_ 62 GTW_w146_performancePackageMisma "GTW_w146_performancePackageMismatch";
BA_ "SystemSignalLongSymbol" SG_ 62 GTW_w227_DISPTOUCHversionMismatc "GTW_w227_DISPTOUCHversionMismatch";
BA_ "SystemSignalLongSymbol" SG_ 62 GTW_w229_displaySoftsetConnectio "GTW_w229_displaySoftsetConnection";
BA_ "SystemSignalLongSymbol" SG_ 62 GTW_w273_BLEEPREARLEFTversionMis "GTW_w273_BLEEPREARLEFTversionMismatch";
BA_ "SystemSignalLongSymbol" SG_ 62 GTW_w274_BLEEPREARRIGHTversionMi "GTW_w274_BLEEPREARRIGHTversionMismatch";
BA_ "SystemSignalLongSymbol" SG_ 62 GTW_w277_NonRevCDrMOSMitigationF "GTW_w277_NonRevCDrMOSMitigationFailed";
BA_ "SystemSignalLongSymbol" SG_ 62 GTW_w282_tcuPhyConfigurationFail "GTW_w282_tcuPhyConfigurationFailed";
BA_ "SystemSignalLongSymbol" SG_ 62 GTW_w311_canLogQueueFullBeforeFs "GTW_w311_canLogQueueFullBeforeFsInit";
BA_ "SystemSignalLongSymbol" SG_ 62 GTW_w317_sdCardChkdskRepairFaile "GTW_w317_sdCardChkdskRepairFailed";
BA_ "SystemSignalLongSymbol" SG_ 62 GTW_w322_gestureUnrecognizedFrom "GTW_w322_gestureUnrecognizedFromMoving";
BA_ "SystemSignalLongSymbol" SG_ 62 GTW_w360_RGBDOORFLversionMismatc "GTW_w360_RGBDOORFLversionMismatch";
BA_ "SystemSignalLongSymbol" SG_ 62 GTW_w361_RGBDOORRLversionMismatc "GTW_w361_RGBDOORRLversionMismatch";
BA_ "SystemSignalLongSymbol" SG_ 62 GTW_w362_RGBDOORFRversionMismatc "GTW_w362_RGBDOORFRversionMismatch";
BA_ "SystemSignalLongSymbol" SG_ 62 GTW_w363_RGBDOORRRversionMismatc "GTW_w363_RGBDOORRRversionMismatch";
BA_ "SystemSignalLongSymbol" SG_ 62 GTW_w364_BLEEPCRADLEversionMisma "GTW_w364_BLEEPCRADLEversionMismatch";
BA_ "SystemSignalLongSymbol" SG_ 62 GTW_w420_unexpectedCanMessageLen "GTW_w420_unexpectedCanMessageLength";
BA_ "SystemSignalLongSymbol" SG_ 62 GTW_w422_ethSwitchSevereCongesti "GTW_w422_ethSwitchSevereCongestionWatchdog";
BA_ "SystemSignalLongSymbol" SG_ 62 GTW_w427_DISPBRIDGEversionMismat "GTW_w427_DISPBRIDGEversionMismatch";
BA_ "SystemSignalLongSymbol" SG_ 62 GTW_w428_LUMBAR32LversionMismatc "GTW_w428_LUMBAR32LversionMismatch";
BA_ "SystemSignalLongSymbol" SG_ 62 GTW_w429_LUMBAR32RversionMismatc "GTW_w429_LUMBAR32RversionMismatch";
BA_ "SystemSignalLongSymbol" SG_ 62 GTW_w437_softFlowControlNotRunni "GTW_w437_softFlowControlNotRunning";
BA_ "SystemSignalLongSymbol" SG_ 62 GTW_w450_unexpectedAutopilotCont "GTW_w450_unexpectedAutopilotControlCanMessage";
BA_ "SystemSignalLongSymbol" SG_ 62 GTW_w455_hrlDumpPageOwnershipErr "GTW_w455_hrlDumpPageOwnershipError";
BA_ "SystemSignalLongSymbol" SG_ 62 GTW_w456_hrlStateMachinePageOwne "GTW_w456_hrlStateMachinePageOwnershipError";
BA_ "Confidence" SG_ 838 GTW_autopilotOverrideState 0;
BA_ "Confidence" SG_ 838 GTW_autopilotConfig 0;
BA_ "Confidence" SG_ 838 GTW_autopilotOverrideConfig 0;
BA_ "Confidence" SG_ 838 GTW_autopilotConfigSource 0;
BA_ "Confidence" SG_ 838 GTW_autopilotOverrideExpireTime 0;
BA_ "Confidence" SG_ 904 GTW_VEH_canBusActivity 0;
BA_ "Confidence" SG_ 904 GTW_PARTY_canBusActivity 0;
BA_ "Confidence" SG_ 904 GTW_CH_canBusActivity 0;
BA_ "Confidence" SG_ 904 GTW_VEH_txWarning 0;
BA_ "Confidence" SG_ 904 GTW_PARTY_txWarning 0;
BA_ "Confidence" SG_ 904 GTW_CH_txWarning 0;
BA_ "Confidence" SG_ 904 GTW_VEH_rxWarning 0;
BA_ "Confidence" SG_ 904 GTW_PARTY_rxWarning 0;
BA_ "Confidence" SG_ 904 GTW_CH_rxWarning 0;
BA_ "Confidence" SG_ 904 GTW_VEH_faultConfinement 0;
BA_ "Confidence" SG_ 904 GTW_PARTY_faultConfinement 0;
BA_ "Confidence" SG_ 904 GTW_CH_faultConfinement 0;
BA_ "Confidence" SG_ 904 GTW_BDY_canBusActivity 0;
BA_ "Confidence" SG_ 904 GTW_BDY_txWarning 0;
BA_ "Confidence" SG_ 904 GTW_BDY_rxWarning 0;
BA_ "Confidence" SG_ 904 GTW_BDY_faultConfinement 0;
BA_ "Confidence" SG_ 2047 GTW_carConfigMultiplexer 0;
BA_ "Confidence" SG_ 2047 GTW_deliveryStatus 0;
BA_ "Confidence" SG_ 2047 GTW_cabinPTCHeaterType 0;
BA_ "Confidence" SG_ 2047 GTW_rightHandDrive 0;
BA_ "Confidence" SG_ 2047 GTW_rearLightType 0;
BA_ "Confidence" SG_ 2047 GTW_headlamps 0;
BA_ "Confidence" SG_ 2047 GTW_country 0;
BA_ "Confidence" SG_ 2047 GTW_tireType 0;
BA_ "Confidence" SG_ 2047 GTW_dasHw 0;
BA_ "Confidence" SG_ 2047 GTW_brakeHWType 0;
BA_ "Confidence" SG_ 2047 GTW_restraintsHardwareType 3;
BA_ "Confidence" SG_ 2047 GTW_drivetrainType 0;
BA_ "Confidence" SG_ 2047 GTW_radarHeaterType 0;
BA_ "Confidence" SG_ 2047 GTW_exteriorTrimType 0;
BA_ "Confidence" SG_ 2047 GTW_frontSeatHeaters 0;
BA_ "Confidence" SG_ 2047 GTW_rearSeatHeaters 0;
BA_ "Confidence" SG_ 2047 GTW_eCallAntennaHW 0;
BA_ "Confidence" SG_ 2047 GTW_homelinkType 0;
BA_ "Confidence" SG_ 2047 GTW_vdcType 0;
BA_ "Confidence" SG_ 2047 GTW_memoryMirrors 0;
BA_ "Confidence" SG_ 2047 GTW_powerLiftgateType 0;
BA_ "Confidence" SG_ 2047 GTW_lumbarECUType 0;
BA_ "Confidence" SG_ 2047 GTW_rearSeatHeaterType 3;
BA_ "Confidence" SG_ 2047 GTW_auxParkLamps 0;
BA_ "Confidence" SG_ 2047 GTW_interiorCabinRadarType 0;
BA_ "Confidence" SG_ 2047 GTW_hvacPanelVaneType 0;
BA_ "Confidence" SG_ 2047 GTW_intakeAirFilterType 0;
BA_ "Confidence" SG_ 2047 GTW_eBuckConfig 0;
BA_ "Confidence" SG_ 2047 GTW_steeringHeaterEnabled 0;
BA_ "Confidence" SG_ 2047 GTW_activeHighBeam 0;
BA_ "Confidence" SG_ 2047 GTW_airbagCutoffSwitch 0;
BA_ "Confidence" SG_ 2047 GTW_intrusionSensorType 0;
BA_ "Confidence" SG_ 2047 GTW_spoilerType 0;
BA_ "Confidence" SG_ 2047 GTW_backupCameraType 0;
BA_ "Confidence" SG_ 2047 GTW_rearFogLamps 0;
BA_ "Confidence" SG_ 2047 GTW_roofType 0;
BA_ "Confidence" SG_ 2047 GTW_thirdRowSeatType 0;
BA_ "Confidence" SG_ 2047 GTW_autopilot 0;
BA_ "Confidence" SG_ 2047 GTW_superchargingAccess 0;
BA_ "Confidence" SG_ 2047 GTW_exteriorColor 0;
BA_ "Confidence" SG_ 2047 GTW_pedestrianWarningSound 0;
BA_ "Confidence" SG_ 2047 GTW_steeringColumnUJointType 0;
BA_ "Confidence" SG_ 2047 GTW_bPillarNFCParam 0;
BA_ "Confidence" SG_ 2047 GTW_interiorLighting 0;
BA_ "Confidence" SG_ 2047 GTW_headlightLevelerType 0;
BA_ "Confidence" SG_ 2047 GTW_numberHVILNodes 0;
BA_ "Confidence" SG_ 2047 GTW_mapRegion 0;
BA_ "Confidence" SG_ 2047 GTW_performancePackage 0;
BA_ "Confidence" SG_ 2047 GTW_chassisType 0;
BA_ "Confidence" SG_ 2047 GTW_airSuspension 0;
BA_ "Confidence" SG_ 2047 GTW_centerConsoleControllerType 0;
BA_ "Confidence" SG_ 2047 GTW_autopilotCameraType 0;
BA_ "Confidence" SG_ 2047 GTW_connectivityPackage 0;
BA_ "Confidence" SG_ 2047 GTW_plcSupportType 0;
BA_ "Confidence" SG_ 2047 GTW_badgingVersion 0;
BA_ "Confidence" SG_ 2047 GTW_packEnergy 0;
BA_ "Confidence" SG_ 2047 GTW_frontSeatReclinerHardware 0;
BA_ "Confidence" SG_ 2047 GTW_brakeLineSwitchType 0;
BA_ "Confidence" SG_ 2047 GTW_espValveType 0;
BA_ "Confidence" SG_ 2047 GTW_softRange 0;
BA_ "Confidence" SG_ 2047 GTW_refrigerantType 0;
BA_ "Confidence" SG_ 2047 GTW_wheelType 0;
BA_ "Confidence" SG_ 2047 GTW_ptcControlMode 0;
BA_ "Confidence" SG_ 2047 GTW_brakeActuationType 0;
BA_ "Confidence" SG_ 2047 GTW_secondRowSeatType 3;
BA_ "Confidence" SG_ 2047 GTW_secondRowSeatMotorType 0;
BA_ "Confidence" SG_ 2047 GTW_birthday 0;
BA_ "Confidence" SG_ 2047 GTW_eCallEnabled 0;
BA_ "Confidence" SG_ 2047 GTW_parkAssistECUType 0;
BA_ "Confidence" SG_ 2047 GTW_passengerAirbagType 0;
BA_ "Confidence" SG_ 2047 GTW_forwardRadarHw 0;
BA_ "Confidence" SG_ 2047 GTW_frontSeatType 0;
BA_ "Confidence" SG_ 2047 GTW_secondRowDisplayType 0;
BA_ "Confidence" SG_ 2047 GTW_wirelessPhoneChargerType 0;
BA_ "Confidence" SG_ 2047 GTW_ethernetTunerType 0;
BA_ "Confidence" SG_ 2047 GTW_interiorTrimType 0;
BA_ "Confidence" SG_ 2047 GTW_gloveboxUSBType 0;
BA_ "Confidence" SG_ 2047 GTW_coolantPumpType 0;
BA_ "Confidence" SG_ 2047 GTW_epblHwType 0;
BA_ "Confidence" SG_ 2047 GTW_epbrHwType 0;
BA_ "Confidence" SG_ 2047 GTW_blowerMotorType 0;
BA_ "Confidence" SG_ 2047 GTW_rearLeftBLEEndpointParameter 0;
BA_ "SystemSignalLongSymbol" SG_ 2047 GTW_rearLeftBLEEndpointParameter "GTW_rearLeftBLEEndpointParameterType";
BA_ "Confidence" SG_ 2047 GTW_powerMirrorFoldType 0;
BA_ "Confidence" SG_ 2047 GTW_frontUsbHubType 0;
BA_ "Confidence" SG_ 2047 GTW_superManifoldType 0;
BA_ "Confidence" SG_ 2047 GTW_rcmLocation 0;
BA_ "Confidence" SG_ 2047 GTW_autopilotExteriorCameraType 0;
BA_ "Confidence" SG_ 2047 GTW_interiorCamBeautyCoverType 0;
BA_ "Confidence" SG_ 2047 GTW_sirenType 0;
BA_ "Confidence" SG_ 2047 GTW_hornType 0;
BA_ "Confidence" SG_ 2047 GTW_passengerTrackMotorType 0;
BA_ "Confidence" SG_ 2047 GTW_steeringColumnMotorType 0;
BA_ "Confidence" SG_ 2047 GTW_refrigACLineType 0;
BA_ "Confidence" SG_ 2047 GTW_refrigFilterType 0;
BA_ "Confidence" SG_ 2047 GTW_diBurnInType 0;
BA_ "Confidence" SG_ 2047 GTW_specialBadgingType 0;
BA_ "Confidence" SG_ 2047 GTW_chassisSubType 0;
BA_ "Confidence" SG_ 2047 GTW_towPackage 0;
BA_ "Confidence" SG_ 2047 GTW_refrigLccType 0;
BA_ "Confidence" SG_ 2047 GTW_restraintControlsType 0;
BA_ "Confidence" SG_ 2047 GTW_caliperColorType 0;
BA_ "Confidence" SG_ 2047 GTW_wiperMotorType 0;
BA_ "Confidence" SG_ 2047 GTW_frontOverheadConsoleType 0;
BA_ "Confidence" SG_ 2047 GTW_shifterType 0;
BA_ "Confidence" SG_ 2047 GTW_compressorType 0;
BA_ "Confidence" SG_ 2047 GTW_twelveVBatteryType 0;
BA_ "Confidence" SG_ 2047 GTW_efuseSWConfig 0;
BA_ "Confidence" SG_ 2047 GTW_tollCollectionModuleType 0;
BA_ "Confidence" SG_ 2047 GTW_bleEndpointUpdateMethod 0;
BA_ "Confidence" SG_ 2047 GTW_steeringWheelControllerType 3;
BA_ "Confidence" SG_ 2047 GTW_frontSeatVentilationEnabled 0;
BA_ "Confidence" SG_ 2047 GTW_gloveboxActuatorType 0;
BA_ "Confidence" SG_ 2047 GTW_epasType 0;
BA_ "Confidence" SG_ 2047 GTW_homologationRegionOverride 0;
BA_ "Confidence" SG_ 2047 GTW_windowCommandsPermissionType 0;
BA_ "Confidence" SG_ 2047 GTW_headlightStepperStallDetectM 0;
BA_ "SystemSignalLongSymbol" SG_ 2047 GTW_headlightStepperStallDetectM "GTW_headlightStepperStallDetectMode";
BA_ "Confidence" SG_ 2047 GTW_rgbInteriorLightingEnabled 0;
BA_ "Confidence" SG_ 2047 GTW_windshieldWiperHeaterType 0;
BA_ "Confidence" SG_ 2047 GTW_thirdRowSeatReclinerType 0;
BA_ "Confidence" SG_ 2047 GTW_driveInterfaceType 0;
BA_ "Confidence" SG_ 2047 GTW_efficiencyPackage 3;
BA_ "Confidence" SG_ 2047 GTW_visorLightType 0;
BA_ "Confidence" SG_ 2047 GTW_gnssAntennaType 0;
BA_ "Confidence" SG_ 2047 GTW_airDistributionBoxType 0;
BA_ "Confidence" SG_ 2047 GTW_frontSeatHeatersEnabled 0;
BA_ "Confidence" SG_ 2047 GTW_windshieldWiperHeaterEnabled 0;
BA_ "Confidence" SG_ 2047 GTW_alcoholInterlockType 0;
BA_ "Confidence" SG_ 2047 GTW_fasciaType 0;
BA_ "Confidence" SG_ 2047 GTW_powerSteeringColumn 0;
BA_ "Confidence" SG_ 2047 GTW_frontSeatHeaterType 0;
BA_ "Confidence" SG_ 2047 GTW_softPerformanceLimit 0;
BA_ "Confidence" SG_ 2047 GTW_gsrFeatureType 0;
BA_ "Confidence" SG_ 2047 GTW_immersiveAudio 0;
BA_ "Confidence" SG_ 2047 GTW_frontSeatVentilationType 0;
BA_ "Confidence" SG_ 2047 GTW_passengerOccupancySensorType 0;
BA_ "Confidence" SG_ 2047 GTW_packPerformanceDeviation 0;
BA_ "Confidence" SG_ 2047 GTW_pressurePadType 1;
BA_ "Confidence" SG_ 2047 GTW_frontFogLamps 0;
BA_ "Confidence" SG_ 2047 GTW_driverOccupancySensorType 0;
BA_ "Confidence" SG_ 2047 GTW_audioType 0;
BA_ "Confidence" SG_ 2047 GTW_thighExtenderType 0;
BA_ "Confidence" SG_ 2047 GTW_occupancyClassificationFeatu 0;
BA_ "SystemSignalLongSymbol" SG_ 2047 GTW_occupancyClassificationFeatu "GTW_occupancyClassificationFeatureType";
BA_ "Confidence" SG_ 2047 GTW_frontControllerArchitectureT 0;
BA_ "SystemSignalLongSymbol" SG_ 2047 GTW_frontControllerArchitectureT "GTW_frontControllerArchitectureType";
BA_ "Confidence" SG_ 2047 GTW_domeLightType 0;
BA_ "Confidence" SG_ 2047 GTW_tpmsType 0;
BA_ "Confidence" SG_ 2047 GTW_authenticationEndpointLayout 0;
BA_ "Confidence" SG_ 2047 GTW_socSleepOverride 0;
BA_ "Confidence" SG_ 2047 GTW_r79BehaviorOverride 0;
BA_ "Confidence" SG_ 2047 GTW_steeringHeaterType 0;
BA_ "Confidence" SG_ 2047 GTW_narrowWipingSupported 0;
BA_ "Confidence" SG_ 2047 GTW_frontSeatHeaterGridType 0;
BA_ "Confidence" SG_ 2047 GTW_frontSeatSideSwitchType 0;
BA_ "Confidence" SG_ 2047 GTW_sohRegulatoryStatus 0;
BA_ "Confidence" SG_ 2047 GTW_passengerTiltMotorType 0;
BA_ "Confidence" SG_ 2047 GTW_frunkInteriorReleaseType 0;
BA_ "Confidence" SG_ 2047 GTW_m3yBusArchitecture 0;
BA_ "Confidence" SG_ 2047 GTW_passengerLiftMotorType 0;
BA_ "Confidence" SG_ 2047 GTW_interiorUpperTrimType 0;
BA_ "Confidence" SG_ 2047 GTW_blindSpotIndicatorLightType 0;
BA_ "Confidence" SG_ 2047 GTW_wiperMotorAsicType 0;
BA_ "Confidence" SG_ 2047 GTW_hvacCaseDoorType 0;
BA_ "Confidence" SG_ 2047 GTW_occupancyDetectionSourceRequ 0;
BA_ "SystemSignalLongSymbol" SG_ 2047 GTW_occupancyDetectionSourceRequ "GTW_occupancyDetectionSourceRequest";
BA_ "Confidence" SG_ 2047 GTW_rduCableType 0;
BA_ "Confidence" SG_ 2047 GTW_parkTelltaleBehaviorType 0;
BA_ "Confidence" SG_ 2047 GTW_numberKeyCardsPairedInFactor 0;
BA_ "SystemSignalLongSymbol" SG_ 2047 GTW_numberKeyCardsPairedInFactor "GTW_numberKeyCardsPairedInFactory";
BA_ "Confidence" SG_ 2047 GTW_secondRowSeatVentilationType 0;
BA_ "Confidence" SG_ 2047 GTW_thirdRowSeatHeaterType 0;
BA_ "Confidence" SG_ 2047 GTW_interiorCameraType 0;
BA_ "Confidence" SG_ 2047 GTW_frontFasciaCameraType 0;
BA_ "Confidence" SG_ 2047 GTW_interiorCamFanType 0;
BA_ "Confidence" SG_ 2047 GTW_puddleLampType 0;
BA_ "Confidence" SG_ 2047 GTW_solarLensType 0;
BA_ "Confidence" SG_ 2047 GTW_liftgateGeometryType 0;
BA_ "Confidence" SG_ 2047 GTW_repeaterAeroRibType 0;
BA_ "Confidence" SG_ 2047 GTW_highTipForceWiperArmsType 0;
BA_ "Confidence" SG_ 2047 GTW_rcmUndersideAbuseZThreshold 0;
BA_ "Confidence" SG_ 2047 GTW_rcmUndersideAbuseYThreshold 0;
BA_ "Confidence" SG_ 2047 GTW_rcmUndersideAbuseWindow 0;
BA_ "Confidence" SG_ 2047 GTW_uhfChargePortEnabled 0;
BA_ "Confidence" SG_ 2047 GTW_automaticFeatureResetPackage 0;
BA_ "Confidence" SG_ 2047 GTW_autopilotFeaturePackage 0;
BA_ "Confidence" SG_ 2047 GTW_doorLatchType 0;
BA_ "Confidence" SG_ 2047 GTW_headlinerMaterialType 0;
BA_ "Confidence" SG_ 2047 GTW_glareShieldHeaterType 0;
BA_ "Confidence" SG_ 2047 GTW_rearLightHardwareVariant 0;
BA_ "Confidence" SG_ 2047 GTW_fasciaHarnessCleanPointType 0;
BA_ "Confidence" SG_ 2047 GTW_epasSubType 0;
BA_ "Confidence" SG_ 2047 GTW_wiperSupplyChainOrigin 0;
BA_ "GenSigSNA" SG_ 2047 GTW_wiperSupplyChainOrigin "0";
BA_ "Confidence" SG_ 2047 GTW_windowPinchParameterType 0;
BA_ "Confidence" SG_ 2047 GTW_badgingMaterialType 0;
BA_ "Confidence" SG_ 2047 GTW_mRecordVersion 0;
BA_ "Confidence" SG_ 2047 GTW_tcuType 0;
BA_ "Confidence" SG_ 2047 GTW_carbComplianceBehaviorType 0;
BA_ "Confidence" SG_ 2047 GTW_indirectTPMSCalibrationType 0;
BA_ "Confidence" SG_ 2047 GTW_v2xEnabled 0;
BA_ "Confidence" SG_ 2047 GTW_liftgateStrutType 0;
BA_ "Confidence" SG_ 2047 GTW_exteriorMicrophoneType 0;
BA_ "Confidence" SG_ 2047 GTW_contactorPowerSource 0;
BA_ "Confidence" SG_ 2047 GTW_roofGlassType 0;
BA_ "Confidence" SG_ 2047 GTW_pedalMapNameOverride 0;
BA_ "Confidence" SG_ 792 GTW_factoryGated 1;
BA_ "Confidence" SG_ 1638 GTW_diagRemainingSeconds 0;
BA_ "Confidence" SG_ 1638 GTW_diagSessionActive 0;
BA_ "Confidence" SG_ 1638 GTW_diagLevel 0;
BA_ "Confidence" SG_ 1638 GTW_diagUnlockProcedureActive 0;
BA_ "Confidence" SG_ 1638 GTW_diagOverrideActive 0;
BA_ "Confidence" SG_ 1638 GTW_diagPhysicalLinkEstablished 0;
BA_ "Confidence" SG_ 1080 GTW_ethGotoSleep 0;
BA_ "Confidence" SG_ 1080 GTW_ethWakeUpBus 0;
BA_ "Confidence" SG_ 1080 GTW_vehBusAsleep 0;
BA_ "Confidence" SG_ 1080 GTW_ethHeartBeatCounter 0;
BA_ "Confidence" SG_ 1080 GTW_ethWakeUpReason 0;
BA_ "Confidence" SG_ 1376 GTW_OCS1Ppresent 1;
BA_ "Confidence" SG_ 1376 GTW_PCSpresent 1;
BA_ "Confidence" SG_ 1376 GTW_HVPpresent 1;
BA_ "Confidence" SG_ 1376 GTW_BMSpresent 1;
BA_ "Confidence" SG_ 1376 GTW_CPpresent 1;
BA_ "Confidence" SG_ 1376 GTW_RCMpresent 1;
BA_ "Confidence" SG_ 1376 GTW_SCCMpresent 1;
BA_ "Confidence" SG_ 1376 GTW_VCSECpresent 1;
BA_ "Confidence" SG_ 1376 GTW_EPAS3Ppresent 1;
BA_ "Confidence" SG_ 1376 GTW_EPBLpresent 1;
BA_ "Confidence" SG_ 1376 GTW_EPBRpresent 1;
BA_ "Confidence" SG_ 1376 GTW_ESPpresent 1;
BA_ "Confidence" SG_ 1376 GTW_IBSTpresent 1;
BA_ "Confidence" SG_ 1376 GTW_PARKpresent 1;
BA_ "Confidence" SG_ 1376 GTW_RADCpresent 1;
BA_ "Confidence" SG_ 1376 GTW_TPMSpresent 1;
BA_ "Confidence" SG_ 1376 GTW_VCFRONTpresent 1;
BA_ "Confidence" SG_ 1376 GTW_VCLEFTpresent 1;
BA_ "Confidence" SG_ 1376 GTW_VCRIGHTpresent 1;
BA_ "Confidence" SG_ 1376 GTW_EPAS3Spresent 1;
BA_ "Confidence" SG_ 1376 GTW_CMPpresent 1;
BA_ "Confidence" SG_ 1376 GTW_DASpresent 1;
BA_ "Confidence" SG_ 1376 GTW_PTCpresent 1;
BA_ "Confidence" SG_ 1376 GTW_SWCpresent 1;
BA_ "Confidence" SG_ 1376 GTW_PMRpresent 1;
BA_ "Confidence" SG_ 1376 GTW_PMFpresent 1;
BA_ "Confidence" SG_ 1376 GTW_DIRpresent 1;
BA_ "Confidence" SG_ 1376 GTW_DIFpresent 1;
BA_ "Confidence" SG_ 1656 GTW_gearControlChecksum 0;
BA_ "Confidence" SG_ 1656 GTW_gearControlCounter 0;
BA_ "Confidence" SG_ 1656 GTW_gearShiftRequest 0;
BA_ "GenSigSNA" SG_ 1656 GTW_gearShiftRequest "0";
BA_ "Confidence" SG_ 1656 GTW_osdActive 0;
BA_ "Confidence" SG_ 1656 GTW_primaryGearControlStatus 0;
BA_ "Confidence" SG_ 1656 GTW_gearStripEnable 0;
BA_ "Confidence" SG_ 1656 GTW_showNeutralButton 0;
BA_ "Confidence" SG_ 1656 GTW_showAutoParkButton 0;
BA_ "Confidence" SG_ 1656 GTW_autoParkRequest 0;
BA_ "Confidence" SG_ 1656 GTW_smartShiftStatus 0;
BA_ "GenSigSNA" SG_ 1656 GTW_smartShiftStatus "0";
BA_ "Confidence" SG_ 1656 GTW_processingRDgestures 0;
BA_ "Confidence" SG_ 1656 GTW_processingTapPgestures 0;
BA_ "Confidence" SG_ 1656 GTW_gearStripChangeReason 0;
BA_ "GenSigSNA" SG_ 1656 GTW_gearStripChangeReason "0";
BA_ "Confidence" SG_ 1656 GTW_touchActive 0;
BA_ "Confidence" SG_ 1656 GTW_steamOff 0;
BA_ "Confidence" SG_ 1656 GTW_screenPCBTemperature 1;
BA_ "GenSigSNA" SG_ 1656 GTW_screenPCBTemperature "2047";
BA_ "Confidence" SG_ 2033 GTW_hrlIndex 1;
BA_ "Confidence" SG_ 2033 GTW_hrlSdCardSizeGB 0;
BA_ "GenSigSNA" SG_ 2033 GTW_hrlSdCardSizeGB "0";
BA_ "Confidence" SG_ 2033 GTW_hrlState 0;
BA_ "Confidence" SG_ 2033 GTW_hrlTriggerDuration 1;
BA_ "Confidence" SG_ 2033 GTW_hrlTriggerType 0;
BA_ "Confidence" SG_ 2033 GTW_hrlTriggerId 1;
BA_ "Confidence" SG_ 2026 GTW_hrlEventStartEpoch 1;
BA_ "Confidence" SG_ 2026 GTW_hrlEventEndEpoch 1;
BA_ "Confidence" SG_ 60 GTW_infoIndex 1;
BA_ "Confidence" SG_ 60 GTW_buildType 0;
BA_ "Confidence" SG_ 60 GTW_hardwareId 0;
BA_ "Confidence" SG_ 60 GTW_platformType 0;
BA_ "Confidence" SG_ 60 GTW_appCrc 0;
BA_ "Confidence" SG_ 60 GTW_applicationGitHash 0;
BA_ "Confidence" SG_ 60 GTW_bootGitHash 0;
BA_ "Confidence" SG_ 1370 GTW_mismatchFaultIndex 1;
BA_ "Confidence" SG_ 1370 GTW_mismatchFaultChecksum 0;
BA_ "Confidence" SG_ 1370 GTW_mismatchFaultCounter 0;
BA_ "Confidence" SG_ 1370 GTW_GTWmismatchFault 0;
BA_ "Confidence" SG_ 1370 GTW_BMSmismatchFault 0;
BA_ "Confidence" SG_ 1370 GTW_APSmismatchFault 0;
BA_ "Confidence" SG_ 1370 GTW_BLEEPCENTERmismatchFault 0;
BA_ "Confidence" SG_ 1370 GTW_BLEEPLEFTmismatchFault 0;
BA_ "Confidence" SG_ 1370 GTW_BLEEPREARmismatchFault 0;
BA_ "Confidence" SG_ 1370 GTW_BLEEPRIGHTmismatchFault 0;
BA_ "Confidence" SG_ 1370 GTW_CBCmismatchFault 0;
BA_ "Confidence" SG_ 1370 GTW_CMPmismatchFault 0;
BA_ "Confidence" SG_ 1370 GTW_CPmismatchFault 0;
BA_ "Confidence" SG_ 1370 GTW_DIFmismatchFault 0;
BA_ "Confidence" SG_ 1370 GTW_DIRmismatchFault 0;
BA_ "Confidence" SG_ 1370 GTW_EPAS3PmismatchFault 0;
BA_ "Confidence" SG_ 1370 GTW_EPAS3SmismatchFault 0;
BA_ "Confidence" SG_ 1370 GTW_EPBLmismatchFault 0;
BA_ "Confidence" SG_ 1370 GTW_EPBRmismatchFault 0;
BA_ "Confidence" SG_ 1370 GTW_ESPCALmismatchFault 0;
BA_ "Confidence" SG_ 1370 GTW_ESPmismatchFault 0;
BA_ "Confidence" SG_ 1370 GTW_HCM3LmismatchFault 0;
BA_ "Confidence" SG_ 1370 GTW_HCM3RmismatchFault 0;
BA_ "Confidence" SG_ 1370 GTW_HCMLmismatchFault 0;
BA_ "Confidence" SG_ 1370 GTW_HCMRmismatchFault 0;
BA_ "Confidence" SG_ 1370 GTW_HVPmismatchFault 0;
BA_ "Confidence" SG_ 1370 GTW_IBSTCALmismatchFault 0;
BA_ "Confidence" SG_ 1370 GTW_IBSTmismatchFault 0;
BA_ "Confidence" SG_ 1370 GTW_LVBMSmismatchFault 0;
BA_ "Confidence" SG_ 1370 GTW_OCS1PmismatchFault 0;
BA_ "Confidence" SG_ 1370 GTW_OPCFmismatchFault 0;
BA_ "Confidence" SG_ 1370 GTW_OPCRmismatchFault 0;
BA_ "Confidence" SG_ 1370 GTW_PARKmismatchFault 0;
BA_ "Confidence" SG_ 1370 GTW_PCSCPU2mismatchFault 0;
BA_ "Confidence" SG_ 1370 GTW_PCSmismatchFault 0;
BA_ "Confidence" SG_ 1370 GTW_PMFmismatchFault 0;
BA_ "Confidence" SG_ 1370 GTW_PMRmismatchFault 0;
BA_ "Confidence" SG_ 1370 GTW_PTCmismatchFault 0;
BA_ "Confidence" SG_ 1370 GTW_RCMCALmismatchFault 0;
BA_ "Confidence" SG_ 1370 GTW_RCMmismatchFault 0;
BA_ "Confidence" SG_ 1370 GTW_SCCMmismatchFault 0;
BA_ "Confidence" SG_ 1370 GTW_SDCRmismatchFault 0;
BA_ "Confidence" SG_ 1370 GTW_SWCmismatchFault 0;
BA_ "Confidence" SG_ 1370 GTW_THSmismatchFault 0;
BA_ "Confidence" SG_ 1370 GTW_VCFRONTmismatchFault 0;
BA_ "Confidence" SG_ 1370 GTW_VCLEFTmismatchFault 0;
BA_ "Confidence" SG_ 1370 GTW_VCRIGHTmismatchFault 0;
BA_ "Confidence" SG_ 1370 GTW_VCSECmismatchFault 0;
BA_ "Confidence" SG_ 1370 GTW_PMmismatchFault 0;
BA_ "Confidence" SG_ 840 GTW_vehicleVersionMatchStatus 0;
BA_ "Confidence" SG_ 840 GTW_hwtype 0;
BA_ "GenSigSNA" SG_ 840 GTW_hwtype "0";
BA_ "Confidence" SG_ 840 GTW_jcanProductName 0;
BA_ "GenSigSNA" SG_ 840 GTW_jcanProductName "0";
BA_ "Confidence" SG_ 840 GTW_uptimeSeconds 1;
BA_ "Confidence" SG_ 840 GTW_boardRevision 0;
BA_ "Confidence" SG_ 840 GTW_touchcoreOsType 0;
BA_ "Confidence" SG_ 840 GTW_sentryModeState 0;
BA_ "GenSigSNA" SG_ 840 GTW_sentryModeState "6";
BA_ "Confidence" SG_ 840 GTW_secureBootEnabled 0;
BA_ "Confidence" SG_ 840 GTW_socSleepType 0;
BA_ "GenSigSNA" SG_ 840 GTW_socSleepType "0";
BA_ "Confidence" SG_ 840 GTW_resetType 0;
BA_ "GenSigSNA" SG_ 840 GTW_resetType "0";
BA_ "Confidence" SG_ 1005 GTW_peripheralConfirmedUpdateNee 1;
BA_ "SystemSignalLongSymbol" SG_ 1005 GTW_peripheralConfirmedUpdateNee "GTW_peripheralConfirmedUpdateNeeded";
BA_ "Confidence" SG_ 1005 GTW_ocuFailed 0;
BA_ "Confidence" SG_ 1005 GTW_ecuUpdateStarted 0;
BA_ "Confidence" SG_ 1005 GTW_updateStarted 1;
BA_ "Confidence" SG_ 1112 GTW_nmGoingToSleep 0;
BA_ "Confidence" SG_ 1112 GTW_nmWakeUpBus 0;
BA_ "Confidence" SG_ 1112 GTW_chBusAsleep 0;
BA_ "Confidence" SG_ 1112 GTW_ethBusAsleep 0;
BA_ "Confidence" SG_ 1112 GTW_nmKeepAwakeReason 0;
BA_ "GenSigSNA" SG_ 1112 GTW_nmKeepAwakeReason "0";
BA_ "Confidence" SG_ 1112 GTW_nmWakeUpReason 0;
BA_ "Confidence" SG_ 1112 GTW_ethKeepAwakeReason 0;
BA_ "GenSigSNA" SG_ 1112 GTW_ethKeepAwakeReason "0";
BA_ "Confidence" SG_ 1112 GTW_nmDebugWakeUp 0;
BA_ "Confidence" SG_ 1112 GTW_OTAKeepAwake 0;
BA_ "Confidence" SG_ 1112 GTW_smsPokeReceived 0;
BA_ "Confidence" SG_ 1112 GTW_bdyBusAsleep 0;
BA_ "Confidence" SG_ 1650 VC_hcmlInfoIndex 1;
BA_ "Confidence" SG_ 1650 VC_infoHCMLBuildConfigId 0;
BA_ "Confidence" SG_ 1650 VC_leftHeadlampLMMVariant 0;
BA_ "GenSigSNA" SG_ 1650 VC_leftHeadlampLMMVariant "0";
BA_ "Confidence" SG_ 1650 VC_infoHCMLAssemblyId 0;
BA_ "Confidence" SG_ 1650 VC_infoHCMLPcbaId 0;
BA_ "Confidence" SG_ 1650 VC_infoHCMLUsageId 0;
BA_ "Confidence" SG_ 1980 VC_hcmrInfoIndex 1;
BA_ "Confidence" SG_ 1980 VC_infoHCMRBuildConfigId 0;
BA_ "Confidence" SG_ 1980 VC_rightHeadlampLMMVariant 0;
BA_ "GenSigSNA" SG_ 1980 VC_rightHeadlampLMMVariant "0";
BA_ "Confidence" SG_ 1980 VC_infoHCMRAssemblyId 0;
BA_ "Confidence" SG_ 1980 VC_infoHCMRPcbaId 0;
BA_ "Confidence" SG_ 1980 VC_infoHCMRUsageId 0;
VAL_ 1300 FC_serialDataSelect 2 "Mux2" 1 "Mux1" 0 "Mux0" ;
VAL_ 532 FC_statusCode 15 "FC_STATUS_NODATA" 14 "FC_STATUS_MALFUNCTION" 13 "FC_STATUS_NOTCOMPATIBLE" 7 "FC_STATUS_POST_OUT_OF_SERVICE" 6 "FC_STATUS_EXT_ISOACTIVE" 5 "FC_STATUS_INT_ISOACTIVE" 4 "FC_STATUS_DEPRECATED_4" 3 "FC_STATUS_DEPRECATED_3" 2 "FC_STATUS_UPDATE_IN_PROGRESS" 1 "FC_STATUS_READY" 0 "FC_STATUS_NOTREADY_SNA" ;
VAL_ 532 FC_type 7 "FC_TYPE_SNA" 6 "FC_TYPE_OTHER" 5 "FC_TYPE_MC_EVSE" 4 "FC_TYPE_COMBO" 3 "FC_TYPE_CC_EVSE" 2 "FC_TYPE_GB" 1 "FC_TYPE_CHADEMO" 0 "FC_TYPE_SUPERCHARGER" ;
VAL_ 532 FC_postID 3 "FC_POST_ID_SNA" 2 "FC_POST_ID_2" 1 "FC_POST_SLAVE" 0 "FC_POST_MASTER" ;
VAL_ 533 FC_externalIsolationResistance 255 "SNA" ;
VAL_ 535 FC_status3DataSelect 1 "Mux1" 0 "Mux0" ;
VAL_ 535 FC_class 2 "FC_CLASS_URBANCHARGER" 1 "FC_CLASS_SUPERCHARGER" 0 "FC_CLASS_SNA" ;
VAL_ 535 FC_brand 1 "TESLA" 0 "SNA" ;
VAL_ 535 FC_coolingType 3 "FC_COOLING_TYPE_IMMERSION" 2 "FC_COOLING_TYPE_CONVECTION" 1 "FC_COOLING_TYPE_LIQUID" 0 "FC_COOLING_TYPE_SNA" ;
VAL_ 535 FC_uiStopType 2 "FC_UI_STOP_TYPE_MOMENTARY" 1 "FC_UI_STOP_TYPE_TOGGLE" 0 "FC_UI_STOP_TYPE_SNA" ;
VAL_ 535 FC_generation 0 "GENERATION_SNA" ;
VAL_ 282 GTW_BKP_BATT_MON 4095 "SNA" ;
VAL_ 282 GTW_BKP_BATT_NTC_P 4095 "SNA" ;
VAL_ 282 GTW_ECALL_GPS_ANT_BIAS 4095 "SNA" ;
VAL_ 282 GTW_ECALL_MIC_DIAG 4095 "SNA" ;
VAL_ 282 GTW_SOS_ECALL_nRQST_BUF 4095 "SNA" ;
VAL_ 1384 GTW_alertID 469 "a469_backlightFsmUnhealthy" 463 "a463_displayEdidReadFailed" 456 "a456_hrlStateMachinePageOwnershipError" 455 "a455_hrlDumpPageOwnershipError" 454 "a454_diagCanFrameOverread" 453 "a453_diagCanFdSetDesync" 452 "a452_diagCanStaleSocket" 451 "a451_diagCanBufferExhausted" 450 "a450_unexpectedAutopilotControlCanMessage" 439 "a439_VCCCversionMismatch" 438 "a438_wakeSourceUnknown" 437 "a437_softFlowControlNotRunning" 436 "a436_possibleCanRxIssue" 429 "a429_LUMBAR32RversionMismatch" 428 "a428_LUMBAR32LversionMismatch" 427 "a427_DISPBRIDGEversionMismatch" 422 "a422_ethSwitchSevereCongestionWatchdog" 421 "a421_ModemEthLinkDown" 420 "a420_unexpectedCanMessageLength" 418 "a418_TRCMversionMismatch" 414 "a414_socHeldInReset" 411 "a411_tASILStatusCheck" 410 "a410_unexpectedResetCause2" 409 "a409_unexpectedResetCause" 402 "a402_VCSEAT2RversionMismatch" 401 "a401_VCSEAT2LversionMismatch" 400 "a400_ethlSwitchOTPIncorrect" 399 "a399_ethIfRxTcpipQueueDrop" 398 "a398_awakeForExtendedTime" 397 "a397_alreadyInDrive" 396 "a396_alreadyInReverse" 395 "a395_lwipIcmpError" 394 "a394_WIPERversionMismatch" 393 "a393_osdSramCrcMismatch" 391 "a391_adspMacAddrCheckFailed" 390 "a390_displayFwQueryFailed" 389 "a389_rcmEventDetected" 388 "a388_adspWatchdogSkipped" 387 "a387_externalRtcReadFailure" 386 "a386_RCUCALversionMismatch" 385 "a385_RCUversionMismatch" 384 "a384_IDBCALversionMismatch" 383 "a383_IDB1versionMismatch" 382 "a382_IDBversionMismatch" 381 "a381_DPBCALversionMismatch" 380 "a380_DPBversionMismatch" 376 "a376_blFailedToExecBootImg" 366 "a366_uiGearRequestMismatch" 364 "a364_BLEEPCRADLEversionMismatch" 363 "a363_RGBDOORRRversionMismatch" 362 "a362_RGBDOORFRversionMismatch" 361 "a361_RGBDOORRLversionMismatch" 360 "a360_RGBDOORFLversionMismatch" 359 "a359_RGBIPFRversionMismatch" 358 "a358_RGBIPFLversionMismatch" 356 "a356_touchGPIOStatusCheck" 355 "a355_EPASTSversionMismatch" 354 "a354_EPASTPversionMismatch" 353 "a353_sASILStatusCheck" 352 "a352_mASILStatusCheck" 351 "a351_sOSDCrcCheck" 350 "a350_mOSDCrcCheck" 349 "a349_VCBLDCPBversionMismatch" 348 "a348_VCBLDCFversionMismatch" 342 "a342_VCBLDCPPversionMismatch" 336 "a336_possibleCanTxIssue" 334 "a334_hrlFolderSpaceLow" 332 "a332_unknownDisplayPN" 331 "a331_SWSRversionMismatch" 330 "a330_SWSLversionMismatch" 329 "a329_FOHMversionMismatch" 328 "a328_smartShiftDisabled" 323 "a323_gestureStartOutOfStrip" 322 "a322_gestureUnrecognizedFromMoving" 317 "a317_sdCardChkdskRepairFailed" 316 "a316_sdCardChkdskRepair" 314 "a314_canLogBlockWriteErr" 313 "a313_OSDActive" 312 "a312_hrlFileIncomplete" 311 "a311_canLogQueueFullBeforeFsInit" 309 "a309_VCUSBversionMismatch" 282 "a282_tcuPhyConfigurationFailed" 281 "a281_likelyMissedPoke" 280 "a280_hrlFrameDropped" 279 "a279_adspRepeatedWatchdog" 278 "a278_ethSwitchCongested" 277 "a277_NonRevCDrMOSMitigationFailed" 276 "a276_VDDSOC_DrMOS_Fault" 275 "a275_VDDCORE_DrMOS_Fault" 274 "a274_BLEEPREARRIGHTversionMismatch" 273 "a273_BLEEPREARLEFTversionMismatch" 268 "a268_stoMIA" 267 "a267_dpp2MIA" 266 "a266_dpp1MIA" 265 "a265_optionFlagsError" 264 "a264_hrlPseudoFileAvail" 263 "a263_hrlUdpFileAvail" 262 "a262_canLogBlockDropped" 261 "a261_adspWatchdog" 260 "a260_unknownPN" 255 "a255_rtc32KHzWatchdog" 246 "a246_touchcoreHeartbeat" 245 "a245_apsNotDisabled" 244 "a244_SDCRversionMismatch" 230 "a230_touchInterruptStorm" 229 "a229_displaySoftsetConnection" 228 "a228_DISPOSDversionMismatch" 227 "a227_DISPTOUCHversionMismatch" 226 "a226_DISPversionMismatch" 225 "a225_resetOnSleepWake" 224 "a224_sdCardUpgradeNeeded" 223 "a223_LVBMSversionMismatch" 219 "a219_CMPSversionMismatch" 218 "a218_switchOTPIncorrect" 186 "a186_swrPrecaution" 176 "a176_TPMShardWarnRearRight" 175 "a175_TPMShardWarnRearLeft" 174 "a174_TPMShardWarnFrontRight" 173 "a173_TPMShardWarnFrontLeft" 172 "a172_TPMSsoftWarnRearRight" 171 "a171_TPMSsoftWarnRearLeft" 170 "a170_TPMSsoftWarnFrontRight" 169 "a169_TPMSsoftWarnFrontLeft" 168 "a168_nErrCanFaultParty" 167 "a167_nErrCanFaultCh" 166 "a166_nErrCanFaultVeh" 165 "a165_USMversionMismatch" 164 "a164_VCBATTversionMismatch" 155 "a155_PMversionMismatch" 153 "a153_externalRtcAlarmFailure" 151 "a151_HCM3RversionMismatch" 150 "a150_HCM3LversionMismatch" 149 "a149_rtcTimeSetInPast" 147 "a147_updateAbortFor12v" 146 "a146_performancePackageMismatch" 145 "a145_carConfigsNotWritten" 144 "a144_hrlStateMachine" 143 "a143_possibleCanWakeIssue" 141 "a141_teleCANETHis" 140 "a140_cancoreHeartbeat" 139 "a139_CMPDversionMismatch" 138 "a138_sdCardEndOfLife" 137 "a137_lowHeap" 136 "a136_hrlGameModeFileAvail" 135 "a135_canLogQueueFull" 134 "a134_disableFeatureFailed" 133 "a133_adspFaultDetected" 129 "a129_ICRversionMismatch" 127 "a127_noFilePointersAvailable" 125 "a125_switchReplayUnlocked" 123 "a123_BDYbusOverloaded" 122 "a122_BDY_canFault" 120 "a120_switchUnlocked" 118 "a118_unexpectedFunctionalResetStatus" 117 "a117_unexpectedDestructiveResetStatus" 116 "a116_switchInitFailed" 115 "a115_hrlEventFileAvail" 114 "a114_updtRetried" 113 "a113_unrecognizedCanMessage" 112 "a112_z4bDisabled" 111 "a111_writeMdioFailed" 110 "a110_readMdioFailed" 109 "a109_failedToStartUpdater" 108 "a108_BLEEPREARversionMismatch" 107 "a107_BLEEPRIGHTversionMismatch" 106 "a106_BLEEPLEFTversionMismatch" 105 "a105_eBuckConfigured" 104 "a104_sdCardDriverArgCorrupted" 103 "a103_sdCardFormatted" 101 "a101_switchWatchdog" 100 "a100_CBCversionMismatch" 99 "a099_SWCversionMismatch" 98 "a098_HCMRversionMismatch" 97 "a097_HCMLversionMismatch" 96 "a096_sdCardFatCorrupted" 95 "a095_sdCardFull" 94 "a094_sdCardInvReqOverflowCount" 93 "a093_sdCardInvReqOverflowBase" 92 "a092_sdCardInvReqZero" 91 "a091_lowStack" 90 "a090_ocuFailed" 89 "a089_sdCardWatchdog" 88 "a088_sdCardInvReqParallel" 87 "a087_ocuInProgress" 86 "a086_ocu" 85 "a085_fuseStateUnknown" 84 "a084_canFrameDropped" 83 "a083_udsMsgDroppedByTcpStack" 82 "a082_sdCardBSCorrupted" 81 "a081_udsMessageRejected" 80 "a080_CHbusOverloaded" 79 "a079_PARTYbusOverloaded" 78 "a078_VEHbusOverloaded" 77 "a077_bmpPmicError" 76 "a076_ethInterfaceReset" 75 "a075_epas3sMIA" 74 "a074_epas3pMIA" 73 "a073_steeringWheelReset" 72 "a072_updateFailure" 71 "a071_hrlTrigger" 70 "a070_hrlDump" 69 "a069_diskioErr" 68 "a068_prodKeyMissing" 67 "a067_tcpDebug" 66 "a066_exception" 65 "a065_PARTY_canFault" 64 "a064_CH_canFault" 63 "a063_VEH_canFault" 62 "a062_bmpWatchdog" 61 "a061_bmpSleepFailure" 60 "a060_unFused" 59 "a059_inFactoryMode" 58 "a058_rtcAlarmFailure" 57 "a057_i2cFailure" 55 "a055_OPCFversionMismatch" 54 "a054_OPCRversionMismatch" 53 "a053_busSleepFailure" 52 "a052_ifTxSpans" 51 "a051_sdCardFileSystemFailure" 50 "a050_sdCardInitFailure" 49 "a049_corruptedManifest" 48 "a048_EPAS3SversionMismatch" 47 "a047_VCRIGHTversionMismatch" 46 "a046_VCLEFTversionMismatch" 45 "a045_VCFRONTversionMismatch" 43 "a043_THSversionMismatch" 42 "a042_TASversionMismatch" 41 "a041_VCSECversionMismatch" 40 "a040_SCCMversionMismatch" 39 "a039_RCMCALversionMismatch" 38 "a038_RCMversionMismatch" 37 "a037_RADCversionMismatch" 36 "a036_PTCversionMismatch" 35 "a035_PMFversionMismatch" 34 "a034_PMRversionMismatch" 33 "a033_PCSCPU2versionMismatch" 32 "a032_PCSversionMismatch" 31 "a031_PARKversionMismatch" 30 "a030_OCS1PversionMismatch" 29 "a029_IBSTCALversionMismatch" 28 "a028_IBSTversionMismatch" 27 "a027_HVPversionMismatch" 26 "a026_GTWversionMismatch" 25 "a025_ESPCALversionMismatch" 24 "a024_ESPversionMismatch" 23 "a023_EPBRversionMismatch" 22 "a022_EPBLversionMismatch" 21 "a021_EPAS3PversionMismatch" 20 "a020_DIRversionMismatch" 19 "a019_CPversionMismatch" 18 "a018_CMPversionMismatch" 17 "a017_BMSversionMismatch" 16 "a016_BLEEPCENTERversionMismatch" 15 "a015_DIFversionMismatch" 14 "a014_APSversionMismatch" 12 "a012_maincoreWatchdog" 11 "a011_cancoreWatchdog" 10 "a010_wdTaskCount" 9 "a009_lateTask" 8 "a008_ifPbufAllocError" 7 "a007_ifRxBufError" 6 "a006_ifTxOutputFull" 5 "a005_stackOverflowHook" 4 "a004_mallocHook" 3 "a003_logWriteRecord" 2 "a002_taskError" 1 "a001_canEthTxQueue" 0 "ALERT_DO_NOT_USE_ZERO" ;
VAL_ 1384 GTW_alertState 1 "SET" 0 "CLEARED" ;
VAL_ 1384 GTW_a049_headerError 3 "HEADER_READ_FAIL" 2 "MUID_LIST_UNEXPECTED" 1 "HEADER_INFO_BAD" 0 "HEADER_OK" ;
VAL_ 1384 GTW_a062_bmpWatchdogReason 4 "THERMAL_TRIP" 3 "SLEEP_FAILURE" 2 "WAKE_FAILURE" 1 "RUNTIME_FAILURE" 0 "WATCHDOG_NONE" ;
VAL_ 1384 GTW_a063_VEH_faultConfinement 2 "BUS_OFF" 1 "ERROR_PASSIVE" 0 "ERROR_ACTIVE" ;
VAL_ 1384 GTW_a064_CH_faultConfinement 2 "BUS_OFF" 1 "ERROR_PASSIVE" 0 "ERROR_ACTIVE" ;
VAL_ 1384 GTW_a065_PARTY_faultConfinement 2 "BUS_OFF" 1 "ERROR_PASSIVE" 0 "ERROR_ACTIVE" ;
VAL_ 1384 GTW_a073_SOCResetRequestor 4 "DAS" 3 "VCSEC" 2 "FORCE" 1 "BUTTONS" 0 "UNKNOWN" ;
VAL_ 1384 GTW_a077_bmpPmicErrorType 4 "INTERNAL_SM" 3 "OT" 2 "MEM_CORRUPT" 1 "OC_OV_CC" 0 "NONE" ;
VAL_ 1384 GTW_a122_BDY_faultConfinement 2 "BUS_OFF" 1 "ERROR_PASSIVE" 0 "ERROR_ACTIVE" ;
VAL_ 1384 GTW_a261_failureReason 6 "INCORRECT_TYPE" 5 "INCORRECT_SEQ_NO" 4 "INCORRECT_ID" 3 "INCORRECT_ADDRESS" 2 "INCORRECT_LENGTH" 1 "RECEIVE_ERROR" 0 "NO_ERROR" ;
VAL_ 1384 GTW_a277_mitigationFailureReason 7 "FAILED_NVRAM_WRITE" 6 "FAILED_NVRAM_WRITE_PROTECTED" 5 "FAILED_REGISTERS_WRITE_PROTECTED" 4 "FAILED_REGISTER_WRITE" 3 "FAILED_REGISTER_READ" 2 "FAILED_ICE_NOT_AWAKE" 1 "NOT_NEEDED" 0 "APPLIED_SUCCESSFULLY" ;
VAL_ 1384 GTW_a279_failureReason 6 "INCORRECT_TYPE" 5 "INCORRECT_SEQ_NO" 4 "INCORRECT_ID" 3 "INCORRECT_ADDRESS" 2 "INCORRECT_LENGTH" 1 "RECEIVE_ERROR" 0 "NO_ERROR" ;
VAL_ 1384 GTW_a317_status 7 "MASK" 4 "PARTIAL" 3 "FAILED" 2 "SUCCESS" 1 "NOT_NEEDED" ;
VAL_ 1384 GTW_a317_errorCode 19 "FS_INFO_INVALID_SIG" 18 "FS_INFO_SECTOR_NOT_FOUND" 17 "FS_INFO_READ_FAILED" 16 "FS_INFO_WRITE_FAILED" 15 "INVALID_CLUSTER" 14 "DIR_TOO_DEEP" 13 "UNKNOWN_FS" 12 "CLUSTER_IN_USE" 11 "FAT_MISMATCHED" 10 "FAT_READ_FAILED" 9 "FAT_WRITE_FAILED" 8 "NOT_FAT32" 7 "BAD_SECTOR_SIZE" 6 "BR_READ_FAILED" 5 "MBR_READ_FAILED" 4 "DISK_INIT_FAILED" 3 "INSUFFICIENT_MEMORY" 2 "ERROR_FOUND_FIXED" 1 "ERROR_FOUND" 0 "NO_ERROR" ;
VAL_ 62 GTW_matrixIndex 7 "AlertMatrix7" 6 "AlertMatrix6" 5 "AlertMatrix5" 4 "AlertMatrix4" 3 "AlertMatrix3" 2 "AlertMatrix2" 1 "AlertMatrix1" 0 "AlertMatrix0" ;
VAL_ 838 GTW_autopilotOverrideState 8 "UNKNOWN" 7 "VEHICLE_MANAGED" 6 "OPTION_OVERRIDE" 5 "OPTION_CODE" 4 "TIMEBOUND_TRIAL" 3 "TIMEBOUND_SUBSCRIPTION" 2 "TRIAL" 1 "SUBSCRIPTION" 0 "BASE" ;
VAL_ 838 GTW_autopilotConfig 4 "BASIC" 3 "SELF_DRIVING" 2 "ENHANCED" 1 "HIGHWAY" 0 "NONE" ;
VAL_ 838 GTW_autopilotOverrideConfig 4 "BASIC" 3 "SELF_DRIVING" 2 "ENHANCED" 1 "HIGHWAY" 0 "NONE" ;
VAL_ 838 GTW_autopilotConfigSource 2 "AUTOPILOT_NOT_UPDATED" 1 "AUTOPILOT" 0 "GATEWAY" ;
VAL_ 904 GTW_VEH_faultConfinement 2 "BUS_OFF" 1 "ERROR_PASSIVE" 0 "ERROR_ACTIVE" ;
VAL_ 904 GTW_PARTY_faultConfinement 2 "BUS_OFF" 1 "ERROR_PASSIVE" 0 "ERROR_ACTIVE" ;
VAL_ 904 GTW_CH_faultConfinement 2 "BUS_OFF" 1 "ERROR_PASSIVE" 0 "ERROR_ACTIVE" ;
VAL_ 904 GTW_BDY_faultConfinement 2 "BUS_OFF" 1 "ERROR_PASSIVE" 0 "ERROR_ACTIVE" ;
VAL_ 2047 GTW_deliveryStatus 1 "DELIVERED" 0 "NOT_DELIVERED" ;
VAL_ 2047 GTW_cabinPTCHeaterType 1 "NONE" 0 "BORGWARNER" ;
VAL_ 2047 GTW_rightHandDrive 1 "RIGHT" 0 "LEFT" ;
VAL_ 2047 GTW_rearLightType 2 "GLOBAL" 1 "EU_CN" 0 "NA" ;
VAL_ 2047 GTW_headlamps 2 "GLOBAL" 1 "PREMIUM" 0 "BASE" ;
VAL_ 2047 GTW_tireType 38 "HANKOOK_SUMMER_18" 37 "GITI_SUMMER_18" 36 "KUMHO_ALL_SEASON_18" 35 "GOODYEAR_ALL_SEASON_18" 34 "CONTI_SUMMER_19" 33 "BRIDGESTONE_ALL_SEASON_20" 32 "HANKOOK_ALL_SEASON_20" 31 "GOODYEAR_SUMMER_19" 30 "KUMHO_ALL_SEASON_19" 29 "HANKOOK_ALL_SEASON_21" 28 "PIRELLI_ALL_SEASON_19" 27 "GOODYEAR_ALL_SEASON_21" 26 "HANKOOK_ALL_SEASON_18" 25 "PIRELLI_ALL_SEASON_22" 24 "CONTI_SUMMER_22" 23 "CONTI_ALL_SEASON_20" 22 "MICHELIN_SUMMER_21" 21 "PIRELLI_SUMMER_20" 20 "PIRELLI_SUMMER_19" 19 "MICHELIN_ALL_SEASON_21" 18 "PIRELLI_SUMMER_21" 17 "GOODYEAR_ALL_SEASON_20" 16 "BRIDGESTONE_SUMMER_18" 7 "GOODYEAR_ALL_TERRAIN_20" 6 "PIRELLI_ALL_SEASON_20" 5 "MICHELIN_SUMMER_20" 4 "CONTI_ALL_SEASON_19" 3 "HANKOOK_SUMMER_19" 2 "MICHELIN_SUMMER_18" 1 "MICHELIN_ALL_SEASON_18" 0 "UNKNOWN" ;
VAL_ 2047 GTW_dasHw 5 "TESLA_AP4" 4 "TESLA_AP3" 3 "PARKER_PASCAL_2_5" ;
VAL_ 2047 GTW_brakeHWType 21 "HITACHI_P42_V2_MANDO_43MOC_LOW_DRAG" 20 "BREMBO_LARGE_P42_V2_MANDO_43MOC_LOW_DRAG" 18 "BREMBO_LARGE_P42_V2_BREMBO_44MOC_GA" 17 "HITACHI_P42_V2_MANDO_43MOC" 16 "BREMBO_P42LD_V2_MANDO_43MOC" 15 "BREMBO_P42LD_ZF_43MOC" 13 "BREMBO_P42_ZF_43MOC" 9 "BREMBO_P42_V2_MANDO_43MOC" 8 "BREMBO_LARGE_P42_V2_MANDO_43MOC" 7 "BREMBO_LARGE_P42_V2_BREMBO_LARGE_44MOC" 6 "BREMBO_LARGE_P42_V2_BREMBO_44MOC" 3 "BREMBO_LARGE_P42_BREMBO_LARGE_44MOC" 2 "BREMBO_LARGE_P42_MANDO_43MOC" 1 "BREMBO_LARGE_P42_BREMBO_44MOC" 0 "BREMBO_P42_MANDO_43MOC" ;
VAL_ 2047 GTW_restraintsHardwareType 239 "NA_NO_KAB_MYB" 238 "ROW_ECALL_E41_MYB" 237 "EU_ECALL_E41_MYB" 236 "NA_E41_MYB" 233 "NA_MYL" 232 "ECE_ECALL_PEDPRO_MYL" 89 "ROW_ECALL_PEDPRO_MYL" 88 "ROW_PEDPRO_MYB" 87 "ROW_PERF_ECALL_PEDPRO_MYB" 86 "EU_PERF_ECALL_PEDPRO_MYB" 85 "EU_ECALL_PEDPRO_MYB" 84 "ROW_ECALL_PEDPRO_MYB" 83 "ROW_MYB" 82 "ROW_ECALL_MYB" 81 "NA_MYB" ;
VAL_ 2047 GTW_drivetrainType 1 "AWD" 0 "RWD" ;
VAL_ 2047 GTW_radarHeaterType 1 "MODELY_BACKER_THIN_3M" 0 "NONE" ;
VAL_ 2047 GTW_exteriorTrimType 1 "SATIN_BLACK" 0 "STANDARD_CHROME" ;
VAL_ 2047 GTW_frontSeatHeaters 1 "KONGSBERG_LOW_POWER" 0 "NONE" ;
VAL_ 2047 GTW_rearSeatHeaters 1 "KONGSBERG_LOW_POWER" 0 "NONE" ;
VAL_ 2047 GTW_eCallAntennaHW 1 "MAIN_ANT_ONLY" 0 "BACKUP_OR_MAIN_ANT" ;
VAL_ 2047 GTW_homelinkType 1 "HOMELINK_V_OPT_2" 0 "NONE" ;
VAL_ 2047 GTW_vdcType 1 "TESLA_VDC" 0 "BOSCH_VDC" ;
VAL_ 2047 GTW_memoryMirrors 1 "SMR" 0 "NOT_INSTALLED" ;
VAL_ 2047 GTW_powerLiftgateType 2 "HUADE_REV1" 1 "TESLA_REV1" 0 "NOT_INSTALLED" ;
VAL_ 2047 GTW_lumbarECUType 10 "AEW_SINGLE_AXIS_DRIVER_ONLY_RHD" 9 "AEW_SINGLE_AXIS_DRIVER_ONLY_LHD" 8 "ND_DRIVER_ONLY_RHD" 7 "ND_DRIVER_ONLY_LHD" 6 "AEW_DRIVER_ONLY_RHD" 5 "AEW_DRIVER_ONLY_LHD" 4 "AEW" 3 "ALFMEIER_DRIVER_ONLY_RHD" 2 "ALFMEIER_DRIVER_ONLY_LHD" 1 "ALFMEIER" 0 "NONE" ;
VAL_ 2047 GTW_rearSeatHeaterType 3 "LEFT_RIGHT_ONLY_GENTHERM" 2 "NONE" 1 "LEFT_RIGHT_ONLY_KONGSBERG" ;
VAL_ 2047 GTW_auxParkLamps 3 "NONE" 2 "EU" 1 "NA_PREMIUM" 0 "NA_BASE" ;
VAL_ 2047 GTW_interiorCabinRadarType 1 "TESLA" 0 "NONE" ;
VAL_ 2047 GTW_hvacPanelVaneType 1 "CONVERGENT_V1" 0 "PARALLEL_V1" ;
VAL_ 2047 GTW_intakeAirFilterType 1 "HEPA" 0 "STANDARD" ;
VAL_ 2047 GTW_eBuckConfig 1 "DEV_BUCK" 0 "NONE" ;
VAL_ 2047 GTW_steeringHeaterEnabled 1 "ENABLED" 0 "DISABLED" ;
VAL_ 2047 GTW_activeHighBeam 1 "ACTIVE" 0 "NOT_ACTIVE" ;
VAL_ 2047 GTW_airbagCutoffSwitch 1 "CUTOFF_SWITCH_ENABLED" 0 "CUTOFF_SWITCH_DISABLED" ;
VAL_ 2047 GTW_intrusionSensorType 1 "VODAFONE" 0 "NOT_INSTALLED" ;
VAL_ 2047 GTW_spoilerType 1 "PASSIVE" 0 "NOT_INSTALLED" ;
VAL_ 2047 GTW_backupCameraType 1 "INTEGRATED_HEATER_V1" 0 "NO_HEATER" ;
VAL_ 2047 GTW_rearFogLamps 1 "INSTALLED" 0 "NOT_INSTALLED" ;
VAL_ 2047 GTW_roofType 1 "FIXED_GLASS" ;
VAL_ 2047 GTW_thirdRowSeatType 1 "FLAT_FOLD" 0 "NONE" ;
VAL_ 2047 GTW_autopilot 4 "BASIC" 3 "SELF_DRIVING" 2 "ENHANCED" 1 "HIGHWAY" 0 "NONE" ;
VAL_ 2047 GTW_superchargingAccess 2 "PAY_AS_YOU_GO" 1 "ALLOWED" 0 "NOT_ALLOWED" ;
VAL_ 2047 GTW_exteriorColor 20 "COASTAL_BLUE" 17 "MARINE_BLUE" 16 "SILKROAD_SILVER" 15 "DIAMOND_BLACK" 14 "GLACIER_BLUE" 13 "FROST_BLUE" 11 "STEALTH_GREY" 10 "ULTRA_RED" 9 "QUICKSILVER" 8 "ABYSS_BLUE" 7 "MIDNIGHT_CHERRY_RED" 6 "PEARL_WHITE" 5 "DEEP_BLUE" 3 "MIDNIGHT_SILVER" 2 "SILVER_METALLIC" 1 "SOLID_BLACK" 0 "RED_MULTICOAT" ;
VAL_ 2047 GTW_pedestrianWarningSound 2 "EXT_SPEAKER_V2" 1 "SPEAKER" 0 "NONE" ;
VAL_ 2047 GTW_steeringColumnUJointType 1 "C_SAMPLE_PHASING" ;
VAL_ 2047 GTW_bPillarNFCParam 1 "MODEL_Y" 0 "MODEL_3" ;
VAL_ 2047 GTW_interiorLighting 6 "FOOTWELL" 5 "FOOTWELL_RGB_IP" 4 "PREMIUM_WITH_RGB_IP_ONLY" 3 "PREMIUM_WITH_RGB" 2 "PREMIUM_NO_POCKET_LIGHT" 1 "PREMIUM" 0 "BASE" ;
VAL_ 2047 GTW_headlightLevelerType 2 "VIRTUAL_PITCH_SENSOR" 1 "GEN1" 0 "NONE" ;
VAL_ 2047 GTW_numberHVILNodes 3 "HVIL_NODES_3" 2 "HVIL_NODES_2" 0 "HVIL_NODES_0" ;
VAL_ 2047 GTW_mapRegion 13 "LA" 12 "IN" 11 "SE" 10 "MO" 9 "HK" 8 "ME" 7 "KR" 6 "TW" 5 "JP" 4 "AU" 3 "CN" 2 "NONE" 1 "EU" 0 "US" ;
VAL_ 2047 GTW_performancePackage 4 "BASE_2022" 3 "BASE_PLUS" 2 "BASE_2024" 1 "PERFORMANCE" 0 "BASE" ;
VAL_ 2047 GTW_chassisType 7 "MODEL_Y_LONG_WHEELBASE_CHASSIS_PATRONUS" 3 "MODEL_Y_CHASSIS" 2 "MODEL_3_CHASSIS" ;
VAL_ 2047 GTW_airSuspension 3 "COIL_ADAPTIVE_DAMPING" 0 "NONE" ;
VAL_ 2047 GTW_centerConsoleControllerType 2 "INSTALLED_NO_AIRWAVE" 1 "INSTALLED_V1" 0 "NONE" ;
VAL_ 2047 GTW_autopilotCameraType 1 "RGGB_CAMERAS" 0 "RCCB_CAMERAS" ;
VAL_ 2047 GTW_connectivityPackage 1 "PREMIUM" 0 "BASE" ;
VAL_ 2047 GTW_plcSupportType 2 "NATIVE_CHARGE_PORT" 1 "ONBOARD_ADAPTER" 0 "NONE" ;
VAL_ 2047 GTW_badgingVersion 2 "VERSION_2" 1 "VERSION_1" 0 "VERSION_0" ;
VAL_ 2047 GTW_packEnergy 2 "MR" 1 "LR" 0 "SR" ;
VAL_ 2047 GTW_frontSeatReclinerHardware 3 "LEFT_RIGHT_SEAT_REDUCED_RANGE" 2 "LEFT_SEAT_REDUCED_RANGE" 1 "RIGHT_SEAT_REDUCED_RANGE" 0 "STANDARD_RANGE" ;
VAL_ 2047 GTW_brakeLineSwitchType 1 "VC_ONLY" 0 "DI_VC_SHARED" ;
VAL_ 2047 GTW_espValveType 2 "VALVE_TYPE_2" 1 "VALVE_TYPE_1" 0 "UNKNOWN" ;
VAL_ 2047 GTW_softRange 4 "RANGE_260_MILES" 3 "RANGE_343_MILES" 2 "RANGE_93_MILES" 1 "RANGE_220_MILES" 0 "STANDARD" ;
VAL_ 2047 GTW_refrigerantType 2 "R1234YF" 1 "R134A" 0 "Default" ;
VAL_ 2047 GTW_wheelType 52 "UBERHELIX_20" 51 "GEMINI_19_DARK_STAGGERED" 50 "HELIX_V2_20_DARK" 48 "MACHINA_V2_19_STAGGERED" 47 "GLIDER_18_CAP_KIT" 46 "APERTURE_18" 41 "ARACHNID_V2_21" 40 "HELIX_V2_20" 39 "CROSSFLOW_19" 33 "WISHBONE_20_STAGGERED" 31 "HELIX_19" 30 "GLIDER_18" 27 "ZEROG_19_GUNPOWDER" 24 "PINWHEEL_REFRESH_18_CAP_KIT" 23 "UBERTURBINE_20_GUNPOWDER" 22 "PINWHEEL_REFRESH_18" 21 "STILETTO_REFRESH_19" 19 "ZEROG_20_GUNPOWDER" 18 "PINWHEEL_18_CAP_KIT" 14 "STILETTO_20_DARK_SQUARE" 5 "GEMINI_19_STAGGERED" 4 "GEMINI_19_SQUARE" 3 "STILETTO_20_DARK_STAGGERED" 2 "STILETTO_20" 1 "STILETTO_19" 0 "PINWHEEL_18" ;
VAL_ 2047 GTW_ptcControlMode 3 "SEQ_ROD_LIMITED" 2 "MESH_INSTALLED" 1 "SEQ_ROD" 0 "BASELINE" ;
VAL_ 2047 GTW_brakeActuationType 2 "ESP_DPB" 1 "IDB_RCU" 0 "ESP_IBST" ;
VAL_ 2047 GTW_secondRowSeatType 6 "TWO_SEATS_POWERED_RECLINE" 5 "FLAT_FOLD_V2" 4 "EASY_ENTRY_POWERED_RECLINE" 3 "POWERED_RECLINE" ;
VAL_ 2047 GTW_secondRowSeatMotorType 1 "KEIPER" 0 "SHB" ;
VAL_ 2047 GTW_eCallEnabled 2 "ENABLED_UI_SOS" 1 "ENABLED_OHC_SOS" 0 "DISABLED" ;
VAL_ 2047 GTW_parkAssistECUType 2 "NONE" 1 "TESLA" 0 "VALEO" ;
VAL_ 2047 GTW_passengerAirbagType 2 "EUROW" 1 "SAFETY_VENT" 0 "FULL_SUPPRESSION" ;
VAL_ 2047 GTW_forwardRadarHw 2 "NONE" 0 "CONTI_ARS410" ;
VAL_ 2047 GTW_frontSeatType 13 "PREMIUM_L_YANFENG_MINITILT_R_TESLA_MINITILT" 12 "PREMIUM_L_YANFENG_MINITILT_R_YANFENG_MINITILT" 11 "PREMIUM_L_YANFENG_MINITILT_R_YANFENG" 10 "PREMIUM_L_YANFENG_R_YANFENG_MINITILT" 9 "PREMIUM_L_TESLA_MINITILT_R_YANFENG_MINITILT" 8 "PREMIUM_L_TESLA_MINITILT_R_TESLA_MINITILT" 7 "PREMIUM_L_TESLA_MINITILT_R_TESLA" 6 "PREMIUM_L_TESLA_R_TESLA_MINITILT" 5 "PREMIUM_BROSE" 4 "PREMIUM_YANFENG" 3 "PREMIUM_L_TESLA_R_YANFENG" 2 "PREMIUM_L_YANFENG_R_TESLA" 1 "PREMIUM_TESLA" 0 "BASE_TESLA" ;
VAL_ 2047 GTW_secondRowDisplayType 1 "TYPE_1" 0 "NONE" ;
VAL_ 2047 GTW_wirelessPhoneChargerType 3 "FRONT_HIGH_POWER_UART" 1 "FRONT_LIN" 0 "NONE_OR_USB" ;
VAL_ 2047 GTW_ethernetTunerType 3 "HARMAN_GEN3" 2 "HIRSCHMANN" 1 "NONE" 0 "HARMAN" ;
VAL_ 2047 GTW_interiorTrimType 3 "WHITE_CONSOLE_2" 2 "BLACK_CONSOLE_2" 1 "WHITE" 0 "BLACK" ;
VAL_ 2047 GTW_gloveboxUSBType 2 "TSC_USB3_A_PLUS_BT" 1 "TSC_USB3_A" 0 "NOT_INSTALLED" ;
VAL_ 2047 GTW_coolantPumpType 5 "DUAL_MIX" 4 "DUAL_SAN_P4_LUB" 2 "DUAL_SAN_P4" 1 "SINGLE_PUMP_BATT" 0 "DUAL" ;
VAL_ 2047 GTW_epblHwType 8 "ZF" 5 "BREMBO_V2" 4 "BREMBO_V1" 2 "MANDO_V2" 1 "MANDO_V1" 0 "NOT_SET" ;
VAL_ 2047 GTW_epbrHwType 8 "ZF" 5 "BREMBO_V2" 4 "BREMBO_V1" 2 "MANDO_V2" 1 "MANDO_V1" 0 "NOT_SET" ;
VAL_ 2047 GTW_blowerMotorType 1 "DELTA" 0 "SHINANO" ;
VAL_ 2047 GTW_rearLeftBLEEndpointParameter 1 "VIVALDI_ANTENNA" 0 "NONE" ;
VAL_ 2047 GTW_powerMirrorFoldType 1 "TYPE_1" 0 "NOT_INSTALLED" ;
VAL_ 2047 GTW_frontUsbHubType 4 "NO_DATA" 0 "2" ;
VAL_ 2047 GTW_superManifoldType 2 "TYPE2" 1 "TYPE1" 0 "TYPE0" ;
VAL_ 2047 GTW_rcmLocation 0 "CENTER_CONSOLE" ;
VAL_ 2047 GTW_autopilotExteriorCameraType 1 "IMX00N" 0 "DEFAULT_FOR_APHW" ;
VAL_ 2047 GTW_interiorCamBeautyCoverType 2 "PITCHED_DOWN" 1 "PITCHED_UP" 0 "STANDARD" ;
VAL_ 2047 GTW_sirenType 1 "VODAPHONE_IF_INTRUSION" 0 "NONE" ;
VAL_ 2047 GTW_hornType 1 "EXT_SPEAKER_V2" 0 "TRUMPET" ;
VAL_ 2047 GTW_passengerTrackMotorType 1 "L_AND_V" 0 "INSTALLED_DEFAULT" ;
VAL_ 2047 GTW_steeringColumnMotorType 3 "NEXTEER" 2 "BOSCH_COMMON_TO_JE" 1 "JE" 0 "BOSCH" ;
VAL_ 2047 GTW_refrigACLineType 2 "CONTI_LIMITED" 1 "SAAA_LIMITED" 0 "UNLIMITED" ;
VAL_ 2047 GTW_refrigFilterType 2 "BLOCKED_V2" 1 "BLOCKED_V1" 0 "UNBLOCKED" ;
VAL_ 2047 GTW_diBurnInType 1 "ENABLED_V1" 0 "NONE" ;
VAL_ 2047 GTW_specialBadgingType 2 "LAUNCH_SERIES" 0 "NONE" ;
VAL_ 2047 GTW_chassisSubType 4 "MARKET_VARIANT_2" 3 "TRIM_DEVIATION_1" 2 "PERFORMANCE" 1 "BASE" 0 "UNKNOWN" ;
VAL_ 2047 GTW_towPackage 2 "TESLA_REV2" 1 "TESLA_REV1" 0 "NONE" ;
VAL_ 2047 GTW_refrigLccType 1 "LCCR" 0 "LCC" ;
VAL_ 2047 GTW_restraintControlsType 1 "TESLA" 0 "BOSCH" ;
VAL_ 2047 GTW_caliperColorType 2 "RED" 1 "GREY" 0 "UNKNOWN" ;
VAL_ 2047 GTW_wiperMotorType 1 "SHB" 0 "NOT_UPDATEABLE" ;
VAL_ 2047 GTW_frontOverheadConsoleType 3 "KOSTAL" 2 "PREH" 1 "BITRON" 0 "VALEO" ;
VAL_ 2047 GTW_shifterType 1 "DISPLAY" 0 "STALK" ;
VAL_ 2047 GTW_compressorType 10 "SANDEN_V4_1" 8 "SANDEN_V4" 7 "SANDEN_V3" 6 "SANDEN_V1_1" 5 "SANDEN_V2" 4 "DENSO_11K_COP1_ENABLED" 3 "SANDEN" 2 "DENSO_41CC_11K" 1 "DENSO_41CC_8K" 0 "HANON_33CC" ;
VAL_ 2047 GTW_twelveVBatteryType 3 "TESLA_16V_LI_ION" 2 "CATL_LI_ION" 1 "CLARIOS_B24_FLOODED" 0 "ATLASBX_B24_FLOODED" ;
VAL_ 2047 GTW_efuseSWConfig 3 "ALL_ENABLED" 2 "SQUARE_ENABLED" 1 "ROUND_ENABLED" 0 "DISABLED" ;
VAL_ 2047 GTW_tollCollectionModuleType 1 "WANJI_V1" 0 "NONE" ;
VAL_ 2047 GTW_bleEndpointUpdateMethod 1 "BOOTLOADER_UPDATE" ;
VAL_ 2047 GTW_steeringWheelControllerType 5 "DUAL_TESLA_GEN5" 2 "DUAL_KOSTAL" 1 "DUAL_PREH" ;
VAL_ 2047 GTW_frontSeatVentilationEnabled 1 "ENABLED" 0 "DISABLED" ;
VAL_ 2047 GTW_gloveboxActuatorType 2 "ELECTROMAGNET" 1 "SMA" 0 "SOLENOID" ;
VAL_ 2047 GTW_epasType 8 "THYSSENKRUPP_CGR65" 7 "MANDO_CGR65" 6 "THYSSENKRUPP_VGR69" 5 "MANDO_CGR69_SINGLE_ECU" 4 "MANDO_CGR69" 3 "MANDO_VGR69_GEN3_SINGLE_ECU" 0 "MANDO_VGR69_GEN3" ;
VAL_ 2047 GTW_homologationRegionOverride 2 "MX_UNECE" 1 "KR_UNECE" 0 "DEFAULT_FOR_COUNTRY_CODE" ;
VAL_ 2047 GTW_windowCommandsPermissionType 2 "US_FMVSS_S6" 1 "US_FMVSS_S4" 0 "ROW_OR_US_FMVSS_S5" ;
VAL_ 2047 GTW_headlightStepperStallDetectM 1 "ENABLED" 0 "DISABLED" ;
VAL_ 2047 GTW_rgbInteriorLightingEnabled 2 "ALL_COLORS" 1 "WHITE_ONLY" 0 "DISABLED_OR_NA" ;
VAL_ 2047 GTW_windshieldWiperHeaterType 1 "TYPE_1" 0 "NOT_INSTALLED" ;
VAL_ 2047 GTW_thirdRowSeatReclinerType 1 "POWERED_SHB" 0 "MANUAL_OR_NA" ;
VAL_ 2047 GTW_driveInterfaceType 1 "EXTERNAL" 0 "COMBINED" ;
VAL_ 2047 GTW_efficiencyPackage 42 "MY_2026_US" 39 "MY_2025_CN_PLUS" 38 "MY_2026_M53" 34 "MY_STANDARD_2026" 33 "MY_REFRESH_2025_CN_ALL_US_LR_RWD" 32 "MY_REFRESH_2025_ROW" 24 "MY_2024_GFSH_EXPORT_NA_SR_RWD" 23 "MY_2024C" 20 "MY_2023_SR_RWD" 16 "MY_2024" 15 "MY_2023_GFSH_EXPORT_NA" 12 "MY_RWD_EU_2022" 11 "MY_SR_PLUS_2022_Q1_TX" 9 "MY_SR_PLUS_2021_Q3_GFSH" 7 "MY_2021" 5 "MY_2020" 0 "DEFAULT" ;
VAL_ 2047 GTW_visorLightType 1 "DIMMABLE_TYPE_1" 0 "NON_DIMMABLE" ;
VAL_ 2047 GTW_gnssAntennaType 2 "GEN2_WITH_METAL_INSERT" 1 "GEN2_NO_METAL_INSERT" 0 "NA_OR_GEN1" ;
VAL_ 2047 GTW_airDistributionBoxType 1 "TYPE_1" 0 "NONE" ;
VAL_ 2047 GTW_frontSeatHeatersEnabled 1 "ENABLED" 0 "DISABLED" ;
VAL_ 2047 GTW_windshieldWiperHeaterEnabled 1 "ENABLED_OR_NA" 0 "DISABLED" ;
VAL_ 2047 GTW_alcoholInterlockType 1 "TYPE_1" 0 "NONE" ;
VAL_ 2047 GTW_fasciaType 8 "E41_BAYBERRY" 4 "PERFORMANCE_BAYBERRY" 3 "BASE_BAYBERRY" 0 "ORIGINAL" ;
VAL_ 2047 GTW_powerSteeringColumn 1 "TK" 0 "NOT_INSTALLED" ;
VAL_ 2047 GTW_frontSeatHeaterType 1 "GENTHERM" 0 "KONGSBERG" ;
VAL_ 2047 GTW_softPerformanceLimit 6 "LIMIT_230_KW" 4 "LIMIT_110_MPH" 2 "LIMIT_110_KW" 1 "LIMIT_160_KW" 0 "NONE" ;
VAL_ 2047 GTW_gsrFeatureType 2 "TYPE_2_GSR" 0 "NONE" ;
VAL_ 2047 GTW_immersiveAudio 2 "PREMIUM" 1 "BASE" 0 "DISABLED" ;
VAL_ 2047 GTW_frontSeatVentilationType 1 "TYPE_1" 0 "NONE" ;
VAL_ 2047 GTW_passengerOccupancySensorType 4 "NONE" 1 "RESISTIVE_PAD" 0 "OCS" ;
VAL_ 2047 GTW_packPerformanceDeviation 5 "PACK_POWER_DEVIATION_2" 4 "PACK_MASS_DEVIATION_2" 3 "PACK_STRUCTURAL_DEVIATION_1" 2 "PACK_POWER_DEVIATION_1" 1 "PACK_MASS_DEVIATION_1" 0 "NO_DEVIATION" ;
VAL_ 2047 GTW_pressurePadType 3 "BOSCH_LINDA_300N" 2 "BOSCH_B2_400N" 1 "BOSCH_B2_300N" 0 "NONE" ;
VAL_ 2047 GTW_frontFogLamps 1 "INSTALLED" 0 "NOT_INSTALLED" ;
VAL_ 2047 GTW_driverOccupancySensorType 1 "NONE" 0 "RESISTIVE_PAD" ;
VAL_ 2047 GTW_audioType 4 "ESSENTIAL_WITH_COMMODITY100" 3 "ESSENTIAL" 1 "PREMIUM" 0 "BASE" ;
VAL_ 2047 GTW_thighExtenderType 1 "YANFENG" 0 "NONE" ;
VAL_ 2047 GTW_occupancyClassificationFeatu 1 "TESLA_CABIN_RADAR" 0 "DISCRETE_SENSOR_OR_NA" ;
VAL_ 2047 GTW_frontControllerArchitectureT 1 "BETA_TYPE" 0 "ALPHA_TYPE" ;
VAL_ 2047 GTW_domeLightType 3 "2R_3R" 2 "2R" ;
VAL_ 2047 GTW_tpmsType 2 "INDIRECT" 1 "TESLA_BLE" 0 "CONTI_2" ;
VAL_ 2047 GTW_authenticationEndpointLayout 6 "M3_LAYOUT_3" 5 "MY_LAYOUT_3" 2 "MY_LAYOUT_2" 1 "M3_LAYOUT_2" 0 "LAYOUT_1" ;
VAL_ 2047 GTW_socSleepOverride 2 "FORCE_SHALLOW" 1 "FORCE_S3" 0 "PN_DERIVED" ;
VAL_ 2047 GTW_r79BehaviorOverride 1 "R79_ENABLED" 0 "NO_OVERRIDE" ;
VAL_ 2047 GTW_steeringHeaterType 7 "YF_V2" 4 "ZF_ROUND" 0 "NONE" ;
VAL_ 2047 GTW_narrowWipingSupported 1 "SUPPORTED" 0 "NOT_SUPPORTED" ;
VAL_ 2047 GTW_frontSeatHeaterGridType 1 "LARGER_SURFACE_AREA" 0 "STANDARD" ;
VAL_ 2047 GTW_frontSeatSideSwitchType 1 "NONE" 0 "STANDARD" ;
VAL_ 2047 GTW_sohRegulatoryStatus 1 "REGULATED_SOH" 0 "NON_REGULATED_SOH" ;
VAL_ 2047 GTW_passengerTiltMotorType 2 "MINITILT" 1 "NONE" 0 "INSTALLED_DEFAULT" ;
VAL_ 2047 GTW_frunkInteriorReleaseType 1 "NOT_INSTALLED" 0 "TYPE_1" ;
VAL_ 2047 GTW_m3yBusArchitecture 2 "PRIVATE_TORQUE_CHASSIS" 1 "PRIVATE_TORQUE" 0 "PUBLIC_TORQUE" ;
VAL_ 2047 GTW_passengerLiftMotorType 2 "BOSCH_KEIPER_COMMON" 1 "NONE" 0 "INSTALLED_DEFAULT" ;
VAL_ 2047 GTW_interiorUpperTrimType 1 "MAMMOTH_BLACK" 0 "POLAR_GREY" ;
VAL_ 2047 GTW_blindSpotIndicatorLightType 2 "INSTALLED_TYPE_2" 1 "INSTALLED_TYPE_1" 0 "NOT_INSTALLED" ;
VAL_ 2047 GTW_wiperMotorAsicType 2 "TYPE_2" 1 "TYPE_1" 0 "UNKNOWN_OR_NA" ;
VAL_ 2047 GTW_hvacCaseDoorType 1 "FLAT_EDGE" 0 "SERRATED_EDGE" ;
VAL_ 2047 GTW_occupancyDetectionSourceRequ 1 "TESLA_CABIN_RADAR" 0 "DISCRETE_SENSOR_OR_NA" ;
VAL_ 2047 GTW_rduCableType 1 "COPPER" 0 "ALUMINUM" ;
VAL_ 2047 GTW_parkTelltaleBehaviorType 1 "TYPE_1_REVISED_BEHAVIOR" 0 "LEGACY_BEHAVIOR" ;
VAL_ 2047 GTW_numberKeyCardsPairedInFactor 2 "2" 1 "1" ;
VAL_ 2047 GTW_secondRowSeatVentilationType 1 "TWO_SEATS_GENTHERM" 0 "NONE" ;
VAL_ 2047 GTW_thirdRowSeatHeaterType 1 "TWO_SEATS_KONGSBERG" 0 "NONE" ;
VAL_ 2047 GTW_interiorCameraType 2 "VD1942" 1 "VD6763" 0 "AR0136" ;
VAL_ 2047 GTW_frontFasciaCameraType 2 "IMX00N" 1 "IMX963" 0 "NONE" ;
VAL_ 2047 GTW_interiorCamFanType 3 "NIDEC" 2 "DELTA_FDB" 0 "NONE" ;
VAL_ 2047 GTW_puddleLampType 2 "INSTALLED_1R_ONLY_TYPE_1" 1 "INSTALLED_TYPE_1" 0 "NOT_INSTALLED" ;
VAL_ 2047 GTW_solarLensType 1 "PEGATRON" 0 "BCS" ;
VAL_ 2047 GTW_liftgateGeometryType 2 "TYPE_2" 1 "TYPE_1" 0 "DEFAULT" ;
VAL_ 2047 GTW_repeaterAeroRibType 4 "RETROFIT_OPTIMIZED" 3 "OPTIMIZED" 0 "UNOPTIMIZED" ;
VAL_ 2047 GTW_highTipForceWiperArmsType 1 "INSTALLED_TYPE_1" 0 "NOT_INSTALLED" ;
VAL_ 2047 GTW_rcmUndersideAbuseZThreshold 7 "threshold7" 6 "threshold6" 5 "threshold5" 4 "threshold4" 3 "threshold3" 2 "threshold2" 1 "threshold1" 0 "threshold0" ;
VAL_ 2047 GTW_rcmUndersideAbuseYThreshold 7 "threshold7" 6 "threshold6" 5 "threshold5" 4 "threshold4" 3 "threshold3" 2 "threshold2" 1 "threshold1" 0 "threshold0" ;
VAL_ 2047 GTW_rcmUndersideAbuseWindow 3 "window3" 2 "window2" 1 "window1" 0 "window0" ;
VAL_ 2047 GTW_uhfChargePortEnabled 1 "DISABLED" 0 "ENABLED" ;
VAL_ 2047 GTW_automaticFeatureResetPackage 1 "TYPE_1" 0 "NONE" ;
VAL_ 2047 GTW_autopilotFeaturePackage 1 "TACC_AND_FSD_ONLY" 0 "LEGACY_AND_FSD" ;
VAL_ 2047 GTW_doorLatchType 1 "SELF_TESTABLE" 0 "DIGITAL" ;
VAL_ 2047 GTW_headlinerMaterialType 2 "POLYURETHANE_FIBERGLASS_LIGHT" 1 "POLYURETHANE_FIBERGLASS" 0 "POLYCARBONATE_ABS" ;
VAL_ 2047 GTW_glareShieldHeaterType 1 "TYPE_1" 0 "NONE" ;
VAL_ 2047 GTW_rearLightHardwareVariant 2 "V3" 1 "V2" 0 "V1" ;
VAL_ 2047 GTW_fasciaHarnessCleanPointType 2 "POST_CLEANPOINT" 1 "PRE_CLEANPOINT" 0 "UNKOWN" ;
VAL_ 2047 GTW_epasSubType 1 "GEN4" 0 "GEN3_OR_NA" ;
VAL_ 2047 GTW_wiperSupplyChainOrigin 2 "NA_SUPPLY_CHAIN" 1 "CN_SUPPLY_CHAIN" 0 "UNKNOWN_OR_SNA" ;
VAL_ 2047 GTW_windowPinchParameterType 2 "TYPE_2" 1 "TYPE_1" 0 "DEFAULT" ;
VAL_ 2047 GTW_badgingMaterialType 1 "BLACK_MATTE" 0 "CHROME_SILVER" ;
VAL_ 2047 GTW_mRecordVersion 1 "VER_2025" 0 "VER_2016_OR_NA" ;
VAL_ 2047 GTW_tcuType 1 "5G" 0 "4G" ;
VAL_ 2047 GTW_carbComplianceBehaviorType 1 "ACCII_2026_BEHAVIOR" 0 "NONE" ;
VAL_ 2047 GTW_indirectTPMSCalibrationType 4 "EXPERIMENTAL_V2" 3 "EXPERIMENTAL_V1_EU" 2 "EXPERIMENTAL_V1" 1 "STANDARD_EU" 0 "STANDARD" ;
VAL_ 2047 GTW_v2xEnabled 1 "DISABLED" 0 "ENABLED" ;
VAL_ 2047 GTW_liftgateStrutType 1 "TYPE_1" 0 "DEFAULT" ;
VAL_ 2047 GTW_exteriorMicrophoneType 1 "TWO_EXT_MICS" 0 "NONE" ;
VAL_ 2047 GTW_contactorPowerSource 1 "VCFRONT" 0 "VCRIGHT" ;
VAL_ 2047 GTW_roofGlassType 4 "AG3" 3 "UNCOATED" 2 "NONE" 1 "TSA5_NOPET" 0 "TSA3_PET" ;
VAL_ 2047 GTW_pedalMapNameOverride 1 "CHILL_STANDARD" 0 "NO_OVERRIDE" ;
VAL_ 1638 GTW_diagLevel 100 "LEVEL_NORMAL_OPERATION" 80 "LEVEL_PARK" 70 "LEVEL_PARK_ROBOTAXI" 50 "LEVEL_SERVICE_DRIVE" 25 "LEVEL_SERVICE" 10 "LEVEL_DIAG_LINK_ACTIVE" 0 "LEVEL_FACTORY" ;
VAL_ 1080 GTW_ethWakeUpReason 17 "GTW_WAKEUP_REASON_TCU_TC10_VERSION_CHECK" 16 "GTW_WAKEUP_REASON_EGGLEFT_LINK_DOWN" 15 "GTW_WAKEUP_REASON_RCMPRIVATE_CAN" 14 "GTW_WAKEUP_REASON_VCLEFT" 13 "GTW_WAKEUP_REASON_LOOP" 12 "GTW_WAKEUP_REASON_DISPLAY_TAP" 11 "GTW_WAKEUP_REASON_URGENT_TRANSMIT_ALERT" 10 "GTW_WAKEUP_REASON_BDY_CAN" 9 "GTW_WAKEUP_REASON_PT_CAN" 8 "GTW_WAKEUP_REASON_UI_SCHEDULED" 7 "GTW_WAKEUP_REASON_RTC_ALARM" 6 "GTW_WAKEUP_REASON_VCFRONT" 5 "GTW_WAKEUP_REASON_VEH_CAN" 4 "GTW_WAKEUP_REASON_ETH_CAN" 3 "GTW_WAKEUP_REASON_CH_CAN" 2 "GTW_WAKEUP_REASON_GSM_RI" 1 "GTW_WAKEUP_REASON_RESET" 0 "GTW_WAKEUP_REASON_NONE" ;
VAL_ 1656 GTW_gearShiftRequest 4 "GEAR_REQUEST_DRIVE" 3 "GEAR_REQUEST_NEUTRAL" 2 "GEAR_REQUEST_REVERSE" 1 "GEAR_REQUEST_PARK" 0 "GEAR_REQUEST_IDLE_SNA" ;
VAL_ 1656 GTW_primaryGearControlStatus 14 "NOT_QUALIFIED_RHD_CONFIG_UNAVAILABLE" 13 "NOT_QUALIFIED_DISPLAY_KNOWN_FROZEN_SCREEN" 12 "NOT_QUALIFIED_DISPLAY_ASIL_VIDEO_ERROR" 11 "NOT_QUALIFIED_GEAR_STRIP_MISMATCH" 10 "NOT_QUALIFIED_DISPLAY_UNTRAINED" 9 "NOT_QUALIFIED_UI_NO_RESP_GEAR_STRIP" 8 "NOT_QUALIFIED_CENTER_DISP_UI_UNHEALTHY" 7 "NOT_QUALIFIED_DISPLAY_FROZEN_ON_GESTURE" 6 "NOT_QUALIFIED_LOW_BRIGHTNESS" 5 "NOT_QUALIFIED_FALSE_TOUCH" 4 "NOT_QUALIFIED_MANUAL" 3 "NOT_QUALIFIED_DISPLAY_ERRS" 2 "NOT_QUALIFIED_FULLSCREEN" 1 "QUALIFIED" 0 "NOT_QUALIFIED" ;
VAL_ 1656 GTW_autoParkRequest 1 "ACTIVE" 0 "IDLE" ;
VAL_ 1656 GTW_smartShiftStatus 9 "DISABLED_AUDIO_NOT_READY" 8 "DISABLED_OSD_ACTIVATED" 7 "DISABLED_DISQUALIFIED" 6 "DISABLED_FULLSCREEN" 5 "DISABLED_UI_MIA" 4 "DISABLED_CLUSTER_DISP_ERR" 3 "DISABLED_CENTER_DISP_ERR" 2 "DISABLED_UI_CONFIG" 1 "ENABLED" 0 "DISABLED_SNA" ;
VAL_ 1656 GTW_gearStripChangeReason 27 "EBUCK_DISABLE" 26 "SLEEP_DISABLE" 25 "VC_MIA_GRACE_DISABLE" 24 "VC_MIA_ENABLE" 23 "DRIVERLESS_NO_TAKEOVER_DISABLE" 22 "EMERGENCY_OPERATION_ENABLE" 21 "WOT_ENABLE" 20 "PARK_ENGAGED_ENABLE" 19 "MISSING_SPEED_OR_STEERING_ESTIMATE_IN_D_ENABLE" 18 "UI_MIA_ENABLE" 16 "NOT_DRIVE_STATE_DISABLE" 15 "FULLSCREEN_DISABLE" 14 "DEFAULT_DISABLE" 13 "REVERSE_ENABLE" 12 "NEUTRAL_ENABLE" 11 "P_AND_BRAKE_ENABLE" 10 "CHARGING_DISABLE" 9 "CRUISE_ACTIVE_DISABLE" 8 "DI_MIA_ENABLE" 7 "HIGH_ACCEL_DISABLE" 6 "MEDIUM_SPEED_DISABLE" 5 "TRAFFIC_CONTROL_NO_CHANGE" 4 "VERY_LOW_SPEED_ENABLE" 3 "HIGH_STEERING_ANGLE_ENABLE" 2 "HIGH_JERK_ENABLE" 1 "DRIVER_BRAKE_APPLY_ENABLE" 0 "SNA" ;
VAL_ 1656 GTW_screenPCBTemperature 2047 "GTW_I2C_TEMP_SNA" ;
VAL_ 2033 GTW_hrlIndex 2 "Mux2" 1 "Mux1" ;
VAL_ 2033 GTW_hrlSdCardSizeGB 0 "SNA" ;
VAL_ 2033 GTW_hrlState 1 "ENABLED" 0 "DISABLED" ;
VAL_ 2033 GTW_hrlTriggerType 15 "HRL_TRIGGER_NONE" 5 "HRL_TRIGGER_EVENT_EXTERNAL" 4 "HRL_TRIGGER_PSEUDONYMOUS" 3 "HRL_TRIGGER_CONTINUOUS" 2 "HRL_TRIGGER_GAME_MODE" 1 "HRL_TRIGGER_EVENT" 0 "HRL_TRIGGER_UDPAPI" ;
VAL_ 60 GTW_infoIndex 255 "END" 31 "SUBCOMPONENT_GITHASH" 30 "PACKAGE_SN_8_14" 29 "PACKAGE_SN_1_7" 27 "PACKAGE_PN_15_20" 26 "PACKAGE_PN_8_14" 25 "PACKAGE_PN_1_7" 23 "SUBCOMPONENT2" 22 "VARIANTCRC" 20 "UDS_PROTOCOL_BOOTCRC" 19 "VERSION_DEPRECATED" 18 "BOOTLOADER_GITHASH" 17 "APP_GITHASH" 16 "SUBCOMPONENT" 15 "BOOTLOADER_CRC" 14 "BOOTLOADER_SVN" 13 "APP_CRC" 11 "PCBAID_ASSYID_USAGEID" 10 "BUILD_HWID_COMPONENTID" 9 "DEPRECATED_9" 8 "DEPRECATED_8" 7 "DEPRECATED_7" 6 "DEPRECATED_6" 5 "DEPRECATED_5" 4 "DEPRECATED_4" 3 "DEPRECATED_3" 2 "DEPRECATED_2" 1 "DEPRECATED_1" 0 "DEPRECATED_0" ;
VAL_ 60 GTW_buildType 4 "INFO_MFG_BUILD" 3 "INFO_TRACEABLE_CI_BUILD" 2 "INFO_LOCAL_BUILD" 1 "INFO_PLATFORM_BUILD" 0 "INFO_UNKNOWN_BUILD" ;
VAL_ 60 GTW_platformType 255 "GTW_PLATFORM_END" 3 "GTW_PLATFORM_MODEL3" 0 "GTW_PLATFORM_UNKNOWN" ;
VAL_ 1370 GTW_mismatchFaultIndex 5 "Mux5" 4 "Mux4" 3 "Mux3" 2 "Mux2" 1 "Mux1" ;
VAL_ 840 GTW_vehicleVersionMatchStatus 2 "MATCHED" 1 "MISMATCHED" 0 "NOT_CALCULATED_YET" ;
VAL_ 840 GTW_hwtype 3 "TRAVEO2" 2 "SPC58" 1 "MPC57" 0 "SNA" ;
VAL_ 840 GTW_jcanProductName 11 "SEMITRUCKV2" 10 "GOLDENSNITCH" 8 "BAYBERRY" 7 "CYBERTRUCK" 6 "POPPYSEED" 5 "SEMITRUCK" 4 "TAMARIND" 3 "LYCHEE" 2 "MODELY" 1 "MODEL3" 0 "SNA" ;
VAL_ 840 GTW_touchcoreOsType 1 "GTW_OS_RT" 0 "GTW_OS_FREERTOS" ;
VAL_ 840 GTW_sentryModeState 6 "SNA" 5 "QUIET" 4 "PANIC" 3 "AWARE" 2 "ARMED" 1 "IDLE" 0 "OFF" ;
VAL_ 840 GTW_secureBootEnabled 1 "TRUE" 0 "FALSE" ;
VAL_ 840 GTW_socSleepType 2 "SHALLOW" 1 "S3" 0 "SNA" ;
VAL_ 840 GTW_resetType 8 "OTHER" 7 "TOUCHCORE_WATCHDOG" 6 "CANCORE_WATCHDOG" 5 "MAINCORE_WATCHDOG" 4 "WAKE" 3 "BUTTON" 2 "SOFTWARE" 1 "POR" 0 "SNA" ;
VAL_ 1005 GTW_peripheralConfirmedUpdateNee 3 "UPDATE_CONDITIONS_NOT_CORRECT" 2 "UPDATE_NOT_NEEDED" 1 "UPDATE_NEEDED" 0 "UNKNOWN" ;
VAL_ 1112 GTW_nmKeepAwakeReason 15 "GTW_KEEPAWAKE_REASON_TBD" 7 "GTW_KEEPAWAKE_REASON_TCU_TC10_VERSION_UNSUPPORTED" 6 "GTW_KEEPAWAKE_REASON_TCU_TC10_VERSION_CHECK" 5 "GTW_KEEPAWAKE_REASON_EGGLEFT_LINK_DOWN" 4 "GTW_KEEPAWAKE_REASON_URGENT_TRANSMIT_ALERT" 3 "GTW_KEEPAWAKE_REASON_FCSM_ACTIVE" 2 "GTW_KEEPAWAKE_REASON_GSM_RI" 1 "GTW_KEEPAWAKE_REASON_UI_SCHEDULED" 0 "GTW_KEEPAWAKE_REASON_NONE_SNA" ;
VAL_ 1112 GTW_nmWakeUpReason 17 "GTW_WAKEUP_REASON_TCU_TC10_VERSION_CHECK" 16 "GTW_WAKEUP_REASON_EGGLEFT_LINK_DOWN" 15 "GTW_WAKEUP_REASON_RCMPRIVATE_CAN" 14 "GTW_WAKEUP_REASON_VCLEFT" 13 "GTW_WAKEUP_REASON_LOOP" 12 "GTW_WAKEUP_REASON_DISPLAY_TAP" 11 "GTW_WAKEUP_REASON_URGENT_TRANSMIT_ALERT" 10 "GTW_WAKEUP_REASON_BDY_CAN" 9 "GTW_WAKEUP_REASON_PT_CAN" 8 "GTW_WAKEUP_REASON_UI_SCHEDULED" 7 "GTW_WAKEUP_REASON_RTC_ALARM" 6 "GTW_WAKEUP_REASON_VCFRONT" 5 "GTW_WAKEUP_REASON_VEH_CAN" 4 "GTW_WAKEUP_REASON_ETH_CAN" 3 "GTW_WAKEUP_REASON_CH_CAN" 2 "GTW_WAKEUP_REASON_GSM_RI" 1 "GTW_WAKEUP_REASON_RESET" 0 "GTW_WAKEUP_REASON_NONE" ;
VAL_ 1112 GTW_ethKeepAwakeReason 3 "TCU_TC10_VERSION_UNSUPPORTED" 2 "TCU_TC10_VERSION_CHECK" 1 "URGENT_TRANSMIT_ALERT" 0 "NONE_SNA" ;
VAL_ 1112 GTW_nmDebugWakeUp 2147483648 "WKPU_31" 1073741824 "WKPU_30" 536870912 "WKPU_29" 268435456 "WKPU_28" 134217728 "WKPU_27" 67108864 "WKPU_26" 33554432 "WKPU_25" 16777216 "WKPU_24" 8388608 "WKPU_23" 4194304 "WKPU_22" 2097152 "WKPU_21" 1048576 "WKPU_20" 524288 "WKPU_19" 262144 "WKPU_18" 131072 "WKPU_17" 65536 "WKPU_16" 32768 "WKPU_15" 16384 "WKPU_14" 8192 "WKPU_13" 4096 "WKPU_12" 2048 "WKPU_11" 1024 "WKPU_10" 512 "WKPU_9" 256 "WKPU_8" 128 "WKPU_7" 64 "WKPU_6" 32 "WKPU_5" 16 "WKPU_4" 8 "WKPU_3" 4 "WKPU_2" 2 "WKPU_1" 1 "WKPU_0" 0 "WKPU_NONE" ;
VAL_ 1650 VC_hcmlInfoIndex 9 "END" 8 "ECULESS_MISC" 7 "ECULESS_BOOST" 6 "ECULESS_LED_VOLTAGES" 5 "ECULESS_IC700_SM" 4 "ECULESS_IC600_DRL_TURN" 3 "ECULESS_IC500_LB" 2 "ECULESS_IC400_HB" 1 "HCML_ASSEMBLY_PCBA_USAGE_ID" 0 "HCML_BUILD_CONFIG_ID_LMM_VARIANT" ;
VAL_ 1650 VC_leftHeadlampLMMVariant 2 "LMM_VARIANT_LMM4" 1 "LMM_VARIANT_NOT_LMM4_OR_UNKNOWN" 0 "LMM_VARIANT_SNA" ;
VAL_ 1980 VC_hcmrInfoIndex 9 "END" 8 "ECULESS_MISC" 7 "ECULESS_BOOST" 6 "ECULESS_LED_VOLTAGES" 5 "ECULESS_IC700_SM" 4 "ECULESS_IC600_DRL_TURN" 3 "ECULESS_IC500_LB" 2 "ECULESS_IC400_HB" 1 "HCMR_ASSEMBLY_PCBA_USAGE_ID" 0 "HCMR_BUILD_CONFIG_ID_LMM_VARIANT" ;
VAL_ 1980 VC_rightHeadlampLMMVariant 2 "LMM_VARIANT_LMM4" 1 "LMM_VARIANT_NOT_LMM4_OR_UNKNOWN" 0 "LMM_VARIANT_SNA" ;
